VERSION "Version"

NS_ :

BS_:

BU_: ADC FLR FRR Tester

BO_ 541 FLR_Obj_28: 32 FLR
 SG_ SGU28_Msg_CheckSum : 7|8@0+ (1,0) [0|255] ""  ADC
 SG_ SGU28_Msg_AliveCounter : 11|4@0+ (1,0) [0|14] ""  ADC
 SG_ SGU28_BlockCounter : 15|4@0+ (1,0) [0|15] ""  ADC
 SG_ SGU28_Object_ID : 23|8@0+ (1,0) [0|255] ""  ADC
 SG_ SGU28_Object_wExist : 28|5@0+ (0.03125,0) [0|0.96875] ""  ADC
 SG_ SGU28_Object_Type : 31|3@0+ (1,0) [0|7] ""  ADC
 SG_ SGU28_Object_Motion_Pattern : 34|3@0+ (1,0) [0|7] ""  ADC
 SG_ SGU28_Object_wObstacle : 39|5@0+ (0.03125,0) [0|0.96875] ""  ADC
 SG_ SGU28_Object_dx : 43|12@0+ (0.0625,-128) [-128|127.9375] "m"  ADC
 SG_ SGU28_Object_dy : 59|12@0+ (0.125,-128) [-128|127.875] "m"  ADC
 SG_ SGU28_Object_DistLong_rms : 79|16@0+ (0.001953125,0) [0|127.998046875] "m"  ADC
 SG_ SGU28_Obj_DistLat_rms : 95|16@0+ (0.001953125,0) [0|127.998046875] "m"  ADC
 SG_ SGU28_Object_vx : 107|12@0+ (0.0625,-128) [-128|127.9375] "m/s"  ADC
 SG_ SGU28_Object_vy : 123|12@0+ (0.0625,-128) [-128|127.9375] "m/s"  ADC
 SG_ SGU28_Obj_VrelLong_rms : 143|16@0+ (0.001953125,0) [0|127.998046875] "m/s"  ADC
 SG_ SGU28_Obj_Vrelat_rms : 159|16@0+ (0.001953125,0) [0|127.998046875] "m/s"  ADC
 SG_ SGU28_Object_ax : 170|11@0+ (0.03125,-16) [-16|15.96875] "m/s^2"  ADC
 SG_ SGU28_Object_ay : 191|11@0+ (0.03125,-16) [-16|15.96875] "m/s^2"  ADC
 SG_ SGU28_Object_DetStatus : 173|3@0+ (1,0) [0|7] ""  ADC
 SG_ SGU28_LifeCycles_OBJ : 196|8@0+ (1,0) [0|255] ""  ADC
 SG_ SGU28_ObjRCS_28 : 204|10@0+ (0.125,-50) [-50|70] "dBm2"  ADC
 SG_ SGU28_Object_dx_Rear : 209|12@0+ (0.0625,-128) [-128|127.9375] "m"  ADC
 SG_ SGU28_Object_dy_Rear : 229|12@0+ (0.125,-128) [-128|127.875] "m"  ADC

BO_ 542 FLR_Obj_29: 32 FLR
 SG_ SGU29_Msg_CheckSum : 7|8@0+ (1,0) [0|255] ""  ADC
 SG_ SGU29_Msg_AliveCounter : 11|4@0+ (1,0) [0|14] ""  ADC
 SG_ SGU29_BlockCounter : 15|4@0+ (1,0) [0|15] ""  ADC
 SG_ SGU29_Object_ID : 23|8@0+ (1,0) [0|255] ""  ADC
 SG_ SGU29_Object_wExist : 28|5@0+ (0.03125,0) [0|0.96875] ""  ADC
 SG_ SGU29_Object_Type : 31|3@0+ (1,0) [0|7] ""  ADC
 SG_ SGU29_Object_Motion_Pattern : 34|3@0+ (1,0) [0|7] ""  ADC
 SG_ SGU29_Object_wObstacle : 39|5@0+ (0.03125,0) [0|0.96875] ""  ADC
 SG_ SGU29_Object_dx : 43|12@0+ (0.0625,-128) [-128|127.9375] "m"  ADC
 SG_ SGU29_Object_dy : 59|12@0+ (0.125,-128) [-128|127.875] "m"  ADC
 SG_ SGU29_Object_DistLong_rms : 79|16@0+ (0.001953125,0) [0|127.998046875] "m"  ADC
 SG_ SGU29_Obj_DistLat_rms : 95|16@0+ (0.001953125,0) [0|127.998046875] "m"  ADC
 SG_ SGU29_Object_vx : 107|12@0+ (0.0625,-128) [-128|127.9375] "m/s"  ADC
 SG_ SGU29_Object_vy : 123|12@0+ (0.0625,-128) [-128|127.9375] "m/s"  ADC
 SG_ SGU29_Obj_VrelLong_rms : 143|16@0+ (0.001953125,0) [0|127.998046875] "m/s"  ADC
 SG_ SGU29_Obj_Vrelat_rms : 159|16@0+ (0.001953125,0) [0|127.998046875] "m/s"  ADC
 SG_ SGU29_Object_ax : 170|11@0+ (0.03125,-16) [-16|15.96875] "m/s^2"  ADC
 SG_ SGU29_Object_ay : 191|11@0+ (0.03125,-16) [-16|15.96875] "m/s^2"  ADC
 SG_ SGU29_Object_DetStatus : 173|3@0+ (1,0) [0|7] ""  ADC
 SG_ SGU29_LifeCycles_OBJ : 196|8@0+ (1,0) [0|255] ""  ADC
 SG_ SGU29_ObjRCS_29 : 204|10@0+ (0.125,-50) [-50|70] "dBm2"  ADC
 SG_ SGU29_Object_dx_Rear : 209|12@0+ (0.0625,-128) [-128|127.9375] "m"  ADC
 SG_ SGU29_Object_dy_Rear : 229|12@0+ (0.125,-128) [-128|127.875] "m"  ADC

BO_ 543 FLR_Obj_30: 32 FLR
 SG_ SGU30_Msg_CheckSum : 7|8@0+ (1,0) [0|255] ""  ADC
 SG_ SGU30_Msg_AliveCounter : 11|4@0+ (1,0) [0|14] ""  ADC
 SG_ SGU30_BlockCounter : 15|4@0+ (1,0) [0|15] ""  ADC
 SG_ SGU30_Object_ID : 23|8@0+ (1,0) [0|255] ""  ADC
 SG_ SGU30_Object_wExist : 28|5@0+ (0.03125,0) [0|0.96875] ""  ADC
 SG_ SGU30_Object_Type : 31|3@0+ (1,0) [0|7] ""  ADC
 SG_ SGU30_Object_Motion_Pattern : 34|3@0+ (1,0) [0|7] ""  ADC
 SG_ SGU30_Object_wObstacle : 39|5@0+ (0.03125,0) [0|0.96875] ""  ADC
 SG_ SGU30_Object_dx : 43|12@0+ (0.0625,-128) [-128|127.9375] "m"  ADC
 SG_ SGU30_Object_dy : 59|12@0+ (0.125,-128) [-128|127.875] "m"  ADC
 SG_ SGU30_Object_DistLong_rms : 79|16@0+ (0.001953125,0) [0|127.998046875] "m"  ADC
 SG_ SGU30_Obj_DistLat_rms : 95|16@0+ (0.001953125,0) [0|127.998046875] "m"  ADC
 SG_ SGU30_Object_vx : 107|12@0+ (0.0625,-128) [-128|127.9375] "m/s"  ADC
 SG_ SGU30_Object_vy : 123|12@0+ (0.0625,-128) [-128|127.9375] "m/s"  ADC
 SG_ SGU30_Obj_VrelLong_rms : 143|16@0+ (0.001953125,0) [0|127.998046875] "m/s"  ADC
 SG_ SGU30_Obj_Vrelat_rms : 159|16@0+ (0.001953125,0) [0|127.998046875] "m/s"  ADC
 SG_ SGU30_Object_ax : 170|11@0+ (0.03125,-16) [-16|15.96875] "m/s^2"  ADC
 SG_ SGU30_Object_ay : 191|11@0+ (0.03125,-16) [-16|15.96875] "m/s^2"  ADC
 SG_ SGU30_Object_DetStatus : 173|3@0+ (1,0) [0|7] ""  ADC
 SG_ SGU30_LifeCycles_OBJ : 196|8@0+ (1,0) [0|255] ""  ADC
 SG_ SGU30_ObjRCS_30 : 204|10@0+ (0.125,-50) [-50|70] "dBm2"  ADC
 SG_ SGU30_Object_dx_Rear : 209|12@0+ (0.0625,-128) [-128|127.9375] "m"  ADC
 SG_ SGU30_Object_dy_Rear : 229|12@0+ (0.125,-128) [-128|127.875] "m"  ADC

BO_ 544 FLR_Obj_31: 32 FLR
 SG_ SGU31_Msg_CheckSum : 7|8@0+ (1,0) [0|255] ""  ADC
 SG_ SGU31_Msg_AliveCounter : 11|4@0+ (1,0) [0|14] ""  ADC
 SG_ SGU31_BlockCounter : 15|4@0+ (1,0) [0|15] ""  ADC
 SG_ SGU31_Object_ID : 23|8@0+ (1,0) [0|255] ""  ADC
 SG_ SGU31_Object_wExist : 28|5@0+ (0.03125,0) [0|0.96875] ""  ADC
 SG_ SGU31_Object_Type : 31|3@0+ (1,0) [0|7] ""  ADC
 SG_ SGU31_Object_Motion_Pattern : 34|3@0+ (1,0) [0|7] ""  ADC
 SG_ SGU31_Object_wObstacle : 39|5@0+ (0.03125,0) [0|0.96875] ""  ADC
 SG_ SGU31_Object_dx : 43|12@0+ (0.0625,-128) [-128|127.9375] "m"  ADC
 SG_ SGU31_Object_dy : 59|12@0+ (0.125,-128) [-128|127.875] "m"  ADC
 SG_ SGU31_Object_DistLong_rms : 79|16@0+ (0.001953125,0) [0|127.998046875] "m"  ADC
 SG_ SGU31_Obj_DistLat_rms : 95|16@0+ (0.001953125,0) [0|127.998046875] "m"  ADC
 SG_ SGU31_Object_vx : 107|12@0+ (0.0625,-128) [-128|127.9375] "m/s"  ADC
 SG_ SGU31_Object_vy : 123|12@0+ (0.0625,-128) [-128|127.9375] "m/s"  ADC
 SG_ SGU31_Obj_VrelLong_rms : 143|16@0+ (0.001953125,0) [0|127.998046875] "m/s"  ADC
 SG_ SGU31_Obj_Vrelat_rms : 159|16@0+ (0.001953125,0) [0|127.998046875] "m/s"  ADC
 SG_ SGU31_Object_ax : 170|11@0+ (0.03125,-16) [-16|15.96875] "m/s^2"  ADC
 SG_ SGU31_Object_ay : 191|11@0+ (0.03125,-16) [-16|15.96875] "m/s^2"  ADC
 SG_ SGU31_Object_DetStatus : 173|3@0+ (1,0) [0|7] ""  ADC
 SG_ SGU31_LifeCycles_OBJ : 196|8@0+ (1,0) [0|255] ""  ADC
 SG_ SGU31_ObjRCS_31 : 204|10@0+ (0.125,-50) [-50|70] "dBm2"  ADC
 SG_ SGU31_Object_dx_Rear : 209|12@0+ (0.0625,-128) [-128|127.9375] "m"  ADC
 SG_ SGU31_Object_dy_Rear : 229|12@0+ (0.125,-128) [-128|127.875] "m"  ADC

BO_ 545 FLR_Obj_32: 32 FLR
 SG_ SGU32_Msg_CheckSum : 7|8@0+ (1,0) [0|255] ""  ADC
 SG_ SGU32_Msg_AliveCounter : 11|4@0+ (1,0) [0|14] ""  ADC
 SG_ SGU32_BlockCounter : 15|4@0+ (1,0) [0|15] ""  ADC
 SG_ SGU32_Object_ID : 23|8@0+ (1,0) [0|255] ""  ADC
 SG_ SGU32_Object_wExist : 28|5@0+ (0.03125,0) [0|0.96875] ""  ADC
 SG_ SGU32_Object_Type : 31|3@0+ (1,0) [0|7] ""  ADC
 SG_ SGU32_Object_Motion_Pattern : 34|3@0+ (1,0) [0|7] ""  ADC
 SG_ SGU32_Object_wObstacle : 39|5@0+ (0.03125,0) [0|0.96875] ""  ADC
 SG_ SGU32_Object_dx : 43|12@0+ (0.0625,-128) [-128|127.9375] "m"  ADC
 SG_ SGU32_Object_dy : 59|12@0+ (0.125,-128) [-128|127.875] "m"  ADC
 SG_ SGU32_Object_DistLong_rms : 79|16@0+ (0.001953125,0) [0|127.998046875] "m"  ADC
 SG_ SGU32_Obj_DistLat_rms : 95|16@0+ (0.001953125,0) [0|127.998046875] "m"  ADC
 SG_ SGU32_Object_vx : 107|12@0+ (0.0625,-128) [-128|127.9375] "m/s"  ADC
 SG_ SGU32_Object_vy : 123|12@0+ (0.0625,-128) [-128|127.9375] "m/s"  ADC
 SG_ SGU32_Obj_VrelLong_rms : 143|16@0+ (0.001953125,0) [0|127.998046875] "m/s"  ADC
 SG_ SGU32_Obj_Vrelat_rms : 159|16@0+ (0.001953125,0) [0|127.998046875] "m/s"  ADC
 SG_ SGU32_Object_ax : 170|11@0+ (0.03125,-16) [-16|15.96875] "m/s^2"  ADC
 SG_ SGU32_Object_ay : 191|11@0+ (0.03125,-16) [-16|15.96875] "m/s^2"  ADC
 SG_ SGU32_Object_DetStatus : 173|3@0+ (1,0) [0|7] ""  ADC
 SG_ SGU32_LifeCycles_OBJ : 196|8@0+ (1,0) [0|255] ""  ADC
 SG_ SGU32_ObjRCS_32 : 204|10@0+ (0.125,-50) [-50|70] "dBm2"  ADC
 SG_ SGU32_Object_dx_Rear : 209|12@0+ (0.0625,-128) [-128|127.9375] "m"  ADC
 SG_ SGU32_Object_dy_Rear : 229|12@0+ (0.125,-128) [-128|127.875] "m"  ADC

BO_ 546 FLR_RadarInfo: 32 FLR
 SG_ FLR_RadarInfor_Checksum : 7|8@0+ (1,0) [0|255] ""  ADC
 SG_ FLR_RadarInfor_AliveCounter : 11|4@0+ (1,0) [0|14] ""  ADC
 SG_ mountAngleIndicator_az : 31|9@0+ (0.05,-12.8) [-12.8|12.75] "degree"  ADC
 SG_ mountAngleCurrent_az : 38|9@0+ (0.05,-12.8) [-12.8|12.75] "degree"  ADC
 SG_ mountAngleIndicator_el : 45|9@0+ (0.05,-12.8) [-12.8|12.75] "degree"  ADC
 SG_ mountAngleCurrent_el : 52|9@0+ (0.05,-12.8) [-12.8|12.75] "degree"  ADC
 SG_ malStablePosAz : 59|9@0+ (0.05,-12.8) [-12.8|12.75] "degree"  ADC
 SG_ malStablePosEl : 66|9@0+ (0.05,-12.8) [-12.8|12.75] "degree"  ADC
 SG_ AngleEMEIndicatorAz : 73|9@0+ (0.05,-12.8) [-12.8|12.75] "degree"  ADC
 SG_ AngleEMEIndicatorEl : 95|9@0+ (0.05,-12.8) [-12.8|12.75] "degree"  ADC
 SG_ FilteredPhiSpread : 102|11@0+ (0.1,-102.4) [-102.4|102.3] "m"  ADC
 SG_ highSpreadIndicator_el : 107|9@0+ (0.05,-12.8) [-12.8|12.75] "degree"  ADC
 SG_ highSpreadIndicator_az : 114|9@0+ (0.05,-12.8) [-12.8|12.75] "degree"  ADC
 SG_ elOutOfSpecCause : 129|2@0+ (1,0) [0|3] ""  ADC
 SG_ azOutOfSpecCause : 131|2@0+ (1,0) [0|3] ""  ADC
 SG_ Fault_MAL_HOR_ABS_EVENT : 132|1@0+ (1,0) [0|1] ""  ADC
 SG_ Fault_MAL_HOR_REL_EVENT : 133|1@0+ (1,0) [0|1] ""  ADC
 SG_ Fault_MAL_VER_ABS_EVENT : 134|1@0+ (1,0) [0|1] ""  ADC
 SG_ Fault_MAL_VER_REL_EVENT : 135|1@0+ (1,0) [0|1] ""  ADC
 SG_ azOutOfProfileCause : 143|8@0+ (1,0) [0|255] ""  ADC
 SG_ elOutOfProfileCause : 151|8@0+ (1,0) [0|255] ""  ADC
 SG_ FLR_SW_Baseline : 155|4@0+ (1,0) [0|15] ""  ADC
 SG_ FLR_SW_ReleaseType : 159|4@0+ (1,0) [0|15] ""  ADC
 SG_ FLR_SW_MajorVersion : 163|4@0+ (1,0) [0|15] ""  ADC
 SG_ FLR_SW_MinorVersion : 167|4@0+ (1,0) [0|15] ""  ADC
 SG_ FLR_SDA_CalibrationSts : 175|8@0+ (1,0) [0|255] ""  ADC
 SG_ FLR_EOL_CalibrationSts : 183|8@0+ (1,0) [0|255] ""  ADC
 SG_ FLR_Blindness_FaultSts : 192|1@0+ (1,0) [0|1] ""  ADC
 SG_ FLR_ModulationSts : 193|1@0+ (1,0) [0|1] ""  ADC
 SG_ FLR_Misalignment_FaultSts : 194|1@0+ (1,0) [0|1] ""  ADC
 SG_ FLR_Radar_FaultSts : 207|8@0+ (1,0) [0|31] ""  ADC
 SG_ FLR_DTC_VBAT_HIGH : 208|1@0+ (1,0) [0|1] ""  ADC
 SG_ FLR_DTC_VBAT_LOW : 209|1@0+ (1,0) [0|1] ""  ADC
 SG_ FLR_DTC_HARDWARE_FAILURE : 210|1@0+ (1,0) [0|1] ""  ADC
 SG_ FLR_DTC_RADAR_OVER_TEMPERATURE : 211|1@0+ (1,0) [0|1] ""  ADC
 SG_ FLR_DTC_CORNER_RADAR_BLIND : 212|1@0+ (1,0) [0|1] ""  ADC
 SG_ FLR_DTC_CORNER_RADAR_MISALIGNED : 213|1@0+ (1,0) [0|1] ""  ADC
 SG_ FLR_DTC_DACORE_OOS : 214|1@0+ (1,0) [0|1] ""  ADC
 SG_ FLR_DTC_DSP_FAILURE : 215|1@0+ (1,0) [0|1] ""  ADC
 SG_ FLR_DTC_VARIANT_SELECTION_NOT_DONE : 216|1@0+ (1,0) [0|1] ""  ADC
 SG_ FLR_DTC_RADAR_SIDE_MISMATCH : 217|1@0+ (1,0) [0|1] ""  ADC
 SG_ FLR_DTC_ALIGNMENT_NOT_DONE : 218|1@0+ (1,0) [0|1] ""  ADC
 SG_ FLR_DTC_PUBLIC_CAN_BUSOFF : 219|1@0+ (1,0) [0|1] ""  ADC
 SG_ FLR_DTC_LOST_COMM_EPS : 222|1@0+ (1,0) [0|1] ""  ADC
 SG_ FLR_DTC_INVALID_DATA_EPS : 223|1@0+ (1,0) [0|1] ""  ADC
 SG_ FLR_DTC_LOST_COMM_BCS : 224|1@0+ (1,0) [0|1] ""  ADC
 SG_ FLR_DTC_INVALID_DATA_BCS : 225|1@0+ (1,0) [0|1] ""  ADC
 SG_ FLR_DTC_LOST_COMM_SOC : 230|1@0+ (1,0) [0|1] ""  ADC
 SG_ FLR_DTC_INVALID_DATA_SOC : 231|1@0+ (1,0) [0|1] ""  ADC
 SG_ FLR_DTC_SOC_Time_SYNC_FAIL : 232|1@0+ (1,0) [0|1] ""  ADC

BO_ 616 ADC_SOC_Time: 64 ADC
 SG_ UMM_UsageModeSt : 26|3@0+ (1,0) [0|7] ""  FLR,FRR
 SG_ VMM_OTAModeSt : 167|2@0+ (1,0) [0|3] ""  FLR,FRR
 SG_ Time_Year : 343|8@0+ (1,2000) [2000|2255] "y"  FLR,FRR
 SG_ Time_Month : 351|4@0+ (1,0) [1|12] "m"  FLR,FRR
 SG_ Time_Day : 347|5@0+ (1,0) [1|31] "d"  FLR,FRR
 SG_ Time_Hour : 358|5@0+ (1,0) [0|23] "h"  FLR,FRR
 SG_ Time_Min : 353|6@0+ (1,0) [0|59] "min"  FLR,FRR
 SG_ Time_Sec : 363|6@0+ (1,0) [0|59] "s"  FLR,FRR

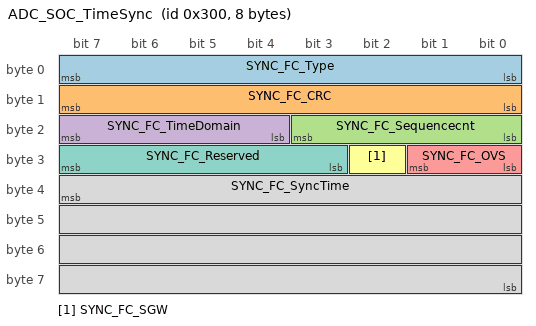
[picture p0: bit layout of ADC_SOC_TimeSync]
BO_ 768 ADC_SOC_TimeSync: 8 ADC
 SG_ SYNC_FC_Type : 7|8@0+ (1,0) [0|255] ""  FLR,FRR
 SG_ SYNC_FC_CRC : 15|8@0+ (1,0) [0|255] ""  FLR,FRR
 SG_ SYNC_FC_Sequencecnt : 19|4@0+ (1,0) [0|15] ""  FLR,FRR
 SG_ SYNC_FC_TimeDomain : 23|4@0+ (1,0) [0|15] ""  FLR,FRR
 SG_ SYNC_FC_OVS : 25|2@0+ (1,0) [0|3] ""  FLR,FRR
 SG_ SYNC_FC_SGW : 26|1@0+ (1,0) [0|1] ""  FLR,FRR
 SG_ SYNC_FC_Reserved : 31|5@0+ (1,0) [0|31] ""  FLR,FRR
 SG_ SYNC_FC_SyncTime : 39|32@0+ (1,0) [0|4294967295] ""  FLR,FRR

BO_ 769 FRR_SensorState: 32 FRR
 SG_ FRR_Msg_CheckSum : 7|8@0+ (1,0) [0|255] ""  ADC
 SG_ FRR_Msg_AliveCounter : 11|4@0+ (1,0) [0|14] ""  ADC
 SG_ FRR_BlockCounter : 15|4@0+ (1,0) [0|15] ""  ADC
 SG_ FRR_OperationMode : 20|3@0+ (1,0) [0|7] ""  ADC
 SG_ FRR_SensorType : 23|3@0+ (1,0) [0|7] ""  ADC
 SG_ FRR_Num_Of_Objects : 29|6@0+ (1,0) [0|32] ""  ADC
 SG_ FRR_SGUFail : 16|3@0+ (1,0) [0|7] ""  ADC
 SG_ FRR_TimerStampStatus : 39|8@0+ (1,0) [0|255] ""  ADC
 SG_ FRR_Object_Mea_timestamp_1 : 79|64@0+ (1,0) [0|18.4467440737096] "ns"  ADC
 SG_ FRR_Object_Mea_timestamp_2 : 143|32@0+ (1,0) [0|4294967295] "ns"  ADC
 SG_ FRR_SDA_HorzDeviationAngle_Can03 : 175|16@0+ (0.01,-180) [-180|180] "degree"  ADC
 SG_ FRR_SDA_VertDeviationAngle_Can03 : 191|16@0+ (0.01,-180) [-180|180] "degree"  ADC
 SG_ FRR_Signal_Operation_State : 210|3@0+ (1,0) [0|7] ""  ADC
 SG_ FRR_TimeSync_Operation_State : 213|3@0+ (1,0) [0|7] ""  ADC
 SG_ FRR_Signal_Operatation_Channel : 215|2@0+ (1,0) [0|4] ""  ADC
 SG_ FRR_TimeSync_Operatation_Channel : 217|2@0+ (1,0) [0|4] ""  ADC
 SG_ FRR_Moudulation_State : 220|3@0+ (1,0) [0|7] ""  ADC

BO_ 770 FRR_Obj_01: 32 FRR
 SG_ SGU1_Msg_CheckSum : 7|8@0+ (1,0) [0|255] ""  ADC
 SG_ SGU1_Msg_AliveCounter : 11|4@0+ (1,0) [0|14] ""  ADC
 SG_ SGU1_BlockCounter : 15|4@0+ (1,0) [0|15] ""  ADC
 SG_ SGU1_Object_ID : 23|8@0+ (1,0) [0|255] ""  ADC
 SG_ SGU1_Object_wExist : 28|5@0+ (0.03125,0) [0|0.96875] ""  ADC
 SG_ SGU1_Object_Type : 31|3@0+ (1,0) [0|7] ""  ADC
 SG_ SGU1_Object_Motion_Pattern : 34|3@0+ (1,0) [0|7] ""  ADC
 SG_ SGU1_Object_wObstacle : 39|5@0+ (0.03125,0) [0|0.96875] ""  ADC
 SG_ SGU1_Object_dx : 43|12@0+ (0.0625,-128) [-128|127.9375] "m"  ADC
 SG_ SGU1_Object_dy : 59|12@0+ (0.125,-128) [-128|127.875] "m"  ADC
 SG_ SGU1_Object_DistLong_rms : 79|16@0+ (0.001953125,0) [0|127.998046875] "m"  ADC
 SG_ SGU1_Obj_DistLat_rms : 95|16@0+ (0.001953125,0) [0|127.998046875] "m"  ADC
 SG_ SGU1_Object_vx : 107|12@0+ (0.0625,-128) [-128|127.9375] "m/s"  ADC
 SG_ SGU1_Object_vy : 123|12@0+ (0.0625,-128) [-128|127.9375] "m/s"  ADC
 SG_ SGU1_Obj_VrelLong_rms : 143|16@0+ (0.001953125,0) [0|127.998046875] "m/s"  ADC
 SG_ SGU1_Obj_Vrelat_rms : 159|16@0+ (0.001953125,0) [0|127.998046875] "m/s"  ADC
 SG_ SGU1_Object_ax : 170|11@0+ (0.03125,-16) [-16|15.96875] "m/s^2"  ADC
 SG_ SGU1_Object_ay : 191|11@0+ (0.03125,-16) [-16|15.96875] "m/s^2"  ADC
 SG_ SGU1_Object_DetStatus : 173|3@0+ (1,0) [0|7] ""  ADC
 SG_ SGU1_LifeCycles_OBJ : 196|8@0+ (1,0) [0|255] ""  ADC
 SG_ SGU1_ObjRCS_01 : 204|10@0+ (0.125,-50) [-50|70] "dBm2"  ADC
 SG_ SGU1_Object_dx_Rear : 209|12@0+ (0.0625,-128) [-128|127.9375] "m"  ADC
 SG_ SGU1_Object_dy_Rear : 229|12@0+ (0.125,-128) [-128|127.875] "m"  ADC

BO_ 771 FRR_Obj_02: 32 FRR
 SG_ SGU2_Msg_CheckSum : 7|8@0+ (1,0) [0|255] ""  ADC
 SG_ SGU2_Msg_AliveCounter : 11|4@0+ (1,0) [0|14] ""  ADC
 SG_ SGU2_BlockCounter : 15|4@0+ (1,0) [0|15] ""  ADC
 SG_ SGU2_Object_ID : 23|8@0+ (1,0) [0|255] ""  ADC
 SG_ SGU2_Object_wExist : 28|5@0+ (0.03125,0) [0|0.96875] ""  ADC
 SG_ SGU2_Object_Type : 31|3@0+ (1,0) [0|7] ""  ADC
 SG_ SGU2_Object_Motion_Pattern : 34|3@0+ (1,0) [0|7] ""  ADC
 SG_ SGU2_Object_wObstacle : 39|5@0+ (0.03125,0) [0|0.96875] ""  ADC
 SG_ SGU2_Object_dx : 43|12@0+ (0.0625,-128) [-128|127.9375] "m"  ADC
 SG_ SGU2_Object_dy : 59|12@0+ (0.125,-128) [-128|127.875] "m"  ADC
 SG_ SGU2_Object_DistLong_rms : 79|16@0+ (0.001953125,0) [0|127.998046875] "m"  ADC
 SG_ SGU2_Obj_DistLat_rms : 95|16@0+ (0.001953125,0) [0|127.998046875] "m"  ADC
 SG_ SGU2_Object_vx : 107|12@0+ (0.0625,-128) [-128|127.9375] "m/s"  ADC
 SG_ SGU2_Object_vy : 123|12@0+ (0.0625,-128) [-128|127.9375] "m/s"  ADC
 SG_ SGU2_Obj_VrelLong_rms : 143|16@0+ (0.001953125,0) [0|127.998046875] "m/s"  ADC
 SG_ SGU2_Obj_Vrelat_rms : 159|16@0+ (0.001953125,0) [0|127.998046875] "m/s"  ADC
 SG_ SGU2_Object_ax : 170|11@0+ (0.03125,-16) [-16|15.96875] "m/s^2"  ADC
 SG_ SGU2_Object_ay : 191|11@0+ (0.03125,-16) [-16|15.96875] "m/s^2"  ADC
 SG_ SGU2_Object_DetStatus : 173|3@0+ (1,0) [0|7] ""  ADC
 SG_ SGU2_LifeCycles_OBJ : 196|8@0+ (1,0) [0|255] ""  ADC
 SG_ SGU2_ObjRCS_02 : 204|10@0+ (0.125,-50) [-50|70] "dBm2"  ADC
 SG_ SGU2_Object_dx_Rear : 209|12@0+ (0.0625,-128) [-128|127.9375] "m"  ADC
 SG_ SGU2_Object_dy_Rear : 229|12@0+ (0.125,-128) [-128|127.875] "m"  ADC

BO_ 772 FRR_Obj_03: 32 FRR
 SG_ SGU3_Msg_CheckSum : 7|8@0+ (1,0) [0|255] ""  ADC
 SG_ SGU3_Msg_AliveCounter : 11|4@0+ (1,0) [0|14] ""  ADC
 SG_ SGU3_BlockCounter : 15|4@0+ (1,0) [0|15] ""  ADC
 SG_ SGU3_Object_ID : 23|8@0+ (1,0) [0|255] ""  ADC
 SG_ SGU3_Object_wExist : 28|5@0+ (0.03125,0) [0|0.96875] ""  ADC
 SG_ SGU3_Object_Type : 31|3@0+ (1,0) [0|7] ""  ADC
 SG_ SGU3_Object_Motion_Pattern : 34|3@0+ (1,0) [0|7] ""  ADC
 SG_ SGU3_Object_wObstacle : 39|5@0+ (0.03125,0) [0|0.96875] ""  ADC
 SG_ SGU3_Object_dx : 43|12@0+ (0.0625,-128) [-128|127.9375] "m"  ADC
 SG_ SGU3_Object_dy : 59|12@0+ (0.125,-128) [-128|127.875] "m"  ADC
 SG_ SGU3_Object_DistLong_rms : 79|16@0+ (0.001953125,0) [0|127.998046875] "m"  ADC
 SG_ SGU3_Obj_DistLat_rms : 95|16@0+ (0.001953125,0) [0|127.998046875] "m"  ADC
 SG_ SGU3_Object_vx : 107|12@0+ (0.0625,-128) [-128|127.9375] "m/s"  ADC
 SG_ SGU3_Object_vy : 123|12@0+ (0.0625,-128) [-128|127.9375] "m/s"  ADC
 SG_ SGU3_Obj_VrelLong_rms : 143|16@0+ (0.001953125,0) [0|127.998046875] "m/s"  ADC
 SG_ SGU3_Obj_Vrelat_rms : 159|16@0+ (0.001953125,0) [0|127.998046875] "m/s"  ADC
 SG_ SGU3_Object_ax : 170|11@0+ (0.03125,-16) [-16|15.96875] "m/s^2"  ADC
 SG_ SGU3_Object_ay : 191|11@0+ (0.03125,-16) [-16|15.96875] "m/s^2"  ADC
 SG_ SGU3_Object_DetStatus : 173|3@0+ (1,0) [0|7] ""  ADC
 SG_ SGU3_LifeCycles_OBJ : 196|8@0+ (1,0) [0|255] ""  ADC
 SG_ SGU3_ObjRCS_03 : 204|10@0+ (0.125,-50) [-50|70] "dBm2"  ADC
 SG_ SGU3_Object_dx_Rear : 209|12@0+ (0.0625,-128) [-128|127.9375] "m"  ADC
 SG_ SGU3_Object_dy_Rear : 229|12@0+ (0.125,-128) [-128|127.875] "m"  ADC

BO_ 773 FRR_Obj_04: 32 FRR
 SG_ SGU4_Msg_CheckSum : 7|8@0+ (1,0) [0|255] ""  ADC
 SG_ SGU4_Msg_AliveCounter : 11|4@0+ (1,0) [0|14] ""  ADC
 SG_ SGU4_BlockCounter : 15|4@0+ (1,0) [0|15] ""  ADC
 SG_ SGU4_Object_ID : 23|8@0+ (1,0) [0|255] ""  ADC
 SG_ SGU4_Object_wExist : 28|5@0+ (0.03125,0) [0|0.96875] ""  ADC
 SG_ SGU4_Object_Type : 31|3@0+ (1,0) [0|7] ""  ADC
 SG_ SGU4_Object_Motion_Pattern : 34|3@0+ (1,0) [0|7] ""  ADC
 SG_ SGU4_Object_wObstacle : 39|5@0+ (0.03125,0) [0|0.96875] ""  ADC
 SG_ SGU4_Object_dx : 43|12@0+ (0.0625,-128) [-128|127.9375] "m"  ADC
 SG_ SGU4_Object_dy : 59|12@0+ (0.125,-128) [-128|127.875] "m"  ADC
 SG_ SGU4_Object_DistLong_rms : 79|16@0+ (0.001953125,0) [0|127.998046875] "m"  ADC
 SG_ SGU4_Obj_DistLat_rms : 95|16@0+ (0.001953125,0) [0|127.998046875] "m"  ADC
 SG_ SGU4_Object_vx : 107|12@0+ (0.0625,-128) [-128|127.9375] "m/s"  ADC
 SG_ SGU4_Object_vy : 123|12@0+ (0.0625,-128) [-128|127.9375] "m/s"  ADC
 SG_ SGU4_Obj_VrelLong_rms : 143|16@0+ (0.001953125,0) [0|127.998046875] "m/s"  ADC
 SG_ SGU4_Obj_Vrelat_rms : 159|16@0+ (0.001953125,0) [0|127.998046875] "m/s"  ADC
 SG_ SGU4_Object_ax : 170|11@0+ (0.03125,-16) [-16|15.96875] "m/s^2"  ADC
 SG_ SGU4_Object_ay : 191|11@0+ (0.03125,-16) [-16|15.96875] "m/s^2"  ADC
 SG_ SGU4_Object_DetStatus : 173|3@0+ (1,0) [0|7] ""  ADC
 SG_ SGU4_LifeCycles_OBJ : 196|8@0+ (1,0) [0|255] ""  ADC
 SG_ SGU4_ObjRCS_04 : 204|10@0+ (0.125,-50) [-50|70] "dBm2"  ADC
 SG_ SGU4_Object_dx_Rear : 209|12@0+ (0.0625,-128) [-128|127.9375] "m"  ADC
 SG_ SGU4_Object_dy_Rear : 229|12@0+ (0.125,-128) [-128|127.875] "m"  ADC

BO_ 774 FRR_Obj_05: 32 FRR
 SG_ SGU5_Msg_CheckSum : 7|8@0+ (1,0) [0|255] ""  ADC
 SG_ SGU5_Msg_AliveCounter : 11|4@0+ (1,0) [0|14] ""  ADC
 SG_ SGU5_BlockCounter : 15|4@0+ (1,0) [0|15] ""  ADC
 SG_ SGU5_Object_ID : 23|8@0+ (1,0) [0|255] ""  ADC
 SG_ SGU5_Object_wExist : 28|5@0+ (0.03125,0) [0|0.96875] ""  ADC
 SG_ SGU5_Object_Type : 31|3@0+ (1,0) [0|7] ""  ADC
 SG_ SGU5_Object_Motion_Pattern : 34|3@0+ (1,0) [0|7] ""  ADC
 SG_ SGU5_Object_wObstacle : 39|5@0+ (0.03125,0) [0|0.96875] ""  ADC
 SG_ SGU5_Object_dx : 43|12@0+ (0.0625,-128) [-128|127.9375] "m"  ADC
 SG_ SGU5_Object_dy : 59|12@0+ (0.125,-128) [-128|127.875] "m"  ADC
 SG_ SGU5_Object_DistLong_rms : 79|16@0+ (0.001953125,0) [0|127.998046875] "m"  ADC
 SG_ SGU5_Obj_DistLat_rms : 95|16@0+ (0.001953125,0) [0|127.998046875] "m"  ADC
 SG_ SGU5_Object_vx : 107|12@0+ (0.0625,-128) [-128|127.9375] "m/s"  ADC
 SG_ SGU5_Object_vy : 123|12@0+ (0.0625,-128) [-128|127.9375] "m/s"  ADC
 SG_ SGU5_Obj_VrelLong_rms : 143|16@0+ (0.001953125,0) [0|127.998046875] "m/s"  ADC
 SG_ SGU5_Obj_Vrelat_rms : 159|16@0+ (0.001953125,0) [0|127.998046875] "m/s"  ADC
 SG_ SGU5_Object_ax : 170|11@0+ (0.03125,-16) [-16|15.96875] "m/s^2"  ADC
 SG_ SGU5_Object_ay : 191|11@0+ (0.03125,-16) [-16|15.96875] "m/s^2"  ADC
 SG_ SGU5_Object_DetStatus : 173|3@0+ (1,0) [0|7] ""  ADC
 SG_ SGU5_LifeCycles_OBJ : 196|8@0+ (1,0) [0|255] ""  ADC
 SG_ SGU5_ObjRCS_05 : 204|10@0+ (0.125,-50) [-50|70] "dBm2"  ADC
 SG_ SGU5_Object_dx_Rear : 209|12@0+ (0.0625,-128) [-128|127.9375] "m"  ADC
 SG_ SGU5_Object_dy_Rear : 229|12@0+ (0.125,-128) [-128|127.875] "m"  ADC

BO_ 775 FRR_Obj_06: 32 FRR
 SG_ SGU6_Msg_CheckSum : 7|8@0+ (1,0) [0|255] ""  ADC
 SG_ SGU6_Msg_AliveCounter : 11|4@0+ (1,0) [0|14] ""  ADC
 SG_ SGU6_BlockCounter : 15|4@0+ (1,0) [0|15] ""  ADC
 SG_ SGU6_Object_ID : 23|8@0+ (1,0) [0|255] ""  ADC
 SG_ SGU6_Object_wExist : 28|5@0+ (0.03125,0) [0|0.96875] ""  ADC
 SG_ SGU6_Object_Type : 31|3@0+ (1,0) [0|7] ""  ADC
 SG_ SGU6_Object_Motion_Pattern : 34|3@0+ (1,0) [0|7] ""  ADC
 SG_ SGU6_Object_wObstacle : 39|5@0+ (0.03125,0) [0|0.96875] ""  ADC
 SG_ SGU6_Object_dx : 43|12@0+ (0.0625,-128) [-128|127.9375] "m"  ADC
 SG_ SGU6_Object_dy : 59|12@0+ (0.125,-128) [-128|127.875] "m"  ADC
 SG_ SGU6_Object_DistLong_rms : 79|16@0+ (0.001953125,0) [0|127.998046875] "m"  ADC
 SG_ SGU6_Obj_DistLat_rms : 95|16@0+ (0.001953125,0) [0|127.998046875] "m"  ADC
 SG_ SGU6_Object_vx : 107|12@0+ (0.0625,-128) [-128|127.9375] "m/s"  ADC
 SG_ SGU6_Object_vy : 123|12@0+ (0.0625,-128) [-128|127.9375] "m/s"  ADC
 SG_ SGU6_Obj_VrelLong_rms : 143|16@0+ (0.001953125,0) [0|127.998046875] "m/s"  ADC
 SG_ SGU6_Obj_Vrelat_rms : 159|16@0+ (0.001953125,0) [0|127.998046875] "m/s"  ADC
 SG_ SGU6_Object_ax : 170|11@0+ (0.03125,-16) [-16|15.96875] "m/s^2"  ADC
 SG_ SGU6_Object_ay : 191|11@0+ (0.03125,-16) [-16|15.96875] "m/s^2"  ADC
 SG_ SGU6_Object_DetStatus : 173|3@0+ (1,0) [0|7] ""  ADC
 SG_ SGU6_LifeCycles_OBJ : 196|8@0+ (1,0) [0|255] ""  ADC
 SG_ SGU6_ObjRCS_06 : 204|10@0+ (0.125,-50) [-50|70] "dBm2"  ADC
 SG_ SGU6_Object_dx_Rear : 209|12@0+ (0.0625,-128) [-128|127.9375] "m"  ADC
 SG_ SGU6_Object_dy_Rear : 229|12@0+ (0.125,-128) [-128|127.875] "m"  ADC

BA_DEF_ BO_  "CANFD_BRS" ENUM  "0","1";
BA_DEF_ BO_  "GenMsgCycleTime" INT 0 0;
BA_DEF_ BO_  "GenMsgCycleTimeFast" INT 0 0;
BA_DEF_ BO_  "GenMsgSendType" ENUM  "Periodic","Event","IfActive","POE","PA","FixedPeriodic","Event","EnabledPeriodic","NotUsed","NotUsed","EventPeriodic","NotUsed","NotUsed","NoMsgSendType";
BA_DEF_ BO_  "VFrameFormat" ENUM  "StandardCAN","ExtendedCAN","reserved","reserved","reserved","reserved","reserved","reserved","reserved","reserved","reserved","reserved","reserved","reserved","StandardCAN_FD","ExtendedCAN_FD";
BA_DEF_ SG_  "EventCommandSignal" ENUM  "No","Yes";
BA_DEF_ SG_  "GatewayedSignals" ENUM  "No","Yes";
BA_DEF_ SG_  "GenSigInactiveValue" HEX 0 0;
BA_DEF_ SG_  "GenSigInvalidValue" HEX 0 0;
BA_DEF_ SG_  "GenSigSendType" ENUM  "Trigger","Passive","Cyclic","OnWrite","OnWriteWithRepetition","OnChange","OnChangeWithRepetition","IfActive","IfActiveWithRepetition","NoSigSendType";
BA_DEF_ SG_  "GenSigStartValue" HEX 0 0;
BA_DEF_ SG_  "GenSigTimeoutValue" HEX 0 0;
BA_DEF_ SG_  "Remark" STRING ;
BA_DEF_ BO_  "GenMsgILSupport" ENUM  "No","Yes";
BA_DEF_ BO_  "MsgType" ENUM  "Normal","NM","Diag","vector_leerstring";
BA_DEF_ BO_  "NmAsrMessage" ENUM  "No","Yes";
BA_DEF_ SG_  "IsCrcSignal" ENUM  "No","Yes";
BA_DEF_ SG_  "SystemSignalLongSymbol" STRING ;

BA_DEF_DEF_  "GenMsgILSupport" "Yes";
BA_DEF_DEF_  "IsCrcSignal" "No";
BA_DEF_DEF_  "MsgType" "";
BA_DEF_DEF_  "NmAsrMessage" "No";
BA_DEF_DEF_  "SystemSignalLongSymbol" "";
BA_ "CANFD_BRS" BO_ 541 1;
BA_ "CANFD_BRS" BO_ 542 1;
BA_ "CANFD_BRS" BO_ 543 1;
BA_ "CANFD_BRS" BO_ 544 1;
BA_ "CANFD_BRS" BO_ 545 1;
BA_ "CANFD_BRS" BO_ 546 1;
BA_ "CANFD_BRS" BO_ 616 1;
BA_ "CANFD_BRS" BO_ 768 1;
BA_ "CANFD_BRS" BO_ 769 1;
BA_ "CANFD_BRS" BO_ 770 1;
BA_ "CANFD_BRS" BO_ 771 1;
BA_ "CANFD_BRS" BO_ 772 1;
BA_ "CANFD_BRS" BO_ 773 1;
BA_ "CANFD_BRS" BO_ 774 1;
BA_ "CANFD_BRS" BO_ 775 1;
BA_ "GenMsgCycleTime" BO_ 541 0;
BA_ "GenMsgCycleTime" BO_ 542 0;
BA_ "GenMsgCycleTime" BO_ 543 0;
BA_ "GenMsgCycleTime" BO_ 544 0;
BA_ "GenMsgCycleTime" BO_ 545 0;
BA_ "GenMsgCycleTime" BO_ 546 50;
BA_ "GenMsgCycleTime" BO_ 616 20;
BA_ "GenMsgCycleTime" BO_ 768 500;
BA_ "GenMsgCycleTime" BO_ 769 0;
BA_ "GenMsgCycleTime" BO_ 770 0;
BA_ "GenMsgCycleTime" BO_ 771 0;
BA_ "GenMsgCycleTime" BO_ 772 0;
BA_ "GenMsgCycleTime" BO_ 773 0;
BA_ "GenMsgCycleTime" BO_ 774 0;
BA_ "GenMsgCycleTime" BO_ 775 0;
BA_ "GenMsgCycleTimeFast" BO_ 541 0;
BA_ "GenMsgCycleTimeFast" BO_ 542 0;
BA_ "GenMsgCycleTimeFast" BO_ 543 0;
BA_ "GenMsgCycleTimeFast" BO_ 544 0;
BA_ "GenMsgCycleTimeFast" BO_ 545 0;
BA_ "GenMsgCycleTimeFast" BO_ 546 0;
BA_ "GenMsgCycleTimeFast" BO_ 616 0;
BA_ "GenMsgCycleTimeFast" BO_ 768 0;
BA_ "GenMsgCycleTimeFast" BO_ 769 0;
BA_ "GenMsgCycleTimeFast" BO_ 770 0;
BA_ "GenMsgCycleTimeFast" BO_ 771 0;
BA_ "GenMsgCycleTimeFast" BO_ 772 0;
BA_ "GenMsgCycleTimeFast" BO_ 773 0;
BA_ "GenMsgCycleTimeFast" BO_ 774 0;
BA_ "GenMsgCycleTimeFast" BO_ 775 0;
BA_ "GenMsgSendType" BO_ 541 1;
BA_ "GenMsgSendType" BO_ 542 1;
BA_ "GenMsgSendType" BO_ 543 1;
BA_ "GenMsgSendType" BO_ 544 1;
BA_ "GenMsgSendType" BO_ 545 1;
BA_ "GenMsgSendType" BO_ 546 0;
BA_ "GenMsgSendType" BO_ 616 0;
BA_ "GenMsgSendType" BO_ 768 0;
BA_ "GenMsgSendType" BO_ 769 1;
BA_ "GenMsgSendType" BO_ 770 1;
BA_ "GenMsgSendType" BO_ 771 1;
BA_ "GenMsgSendType" BO_ 772 1;
BA_ "GenMsgSendType" BO_ 773 1;
BA_ "GenMsgSendType" BO_ 774 1;
BA_ "GenMsgSendType" BO_ 775 1;
BA_ "VFrameFormat" BO_ 541 14;
BA_ "VFrameFormat" BO_ 542 14;
BA_ "VFrameFormat" BO_ 543 14;
BA_ "VFrameFormat" BO_ 544 14;
BA_ "VFrameFormat" BO_ 545 14;
BA_ "VFrameFormat" BO_ 546 14;
BA_ "VFrameFormat" BO_ 616 14;
BA_ "VFrameFormat" BO_ 768 14;
BA_ "VFrameFormat" BO_ 769 14;
BA_ "VFrameFormat" BO_ 770 14;
BA_ "VFrameFormat" BO_ 771 14;
BA_ "VFrameFormat" BO_ 772 14;
BA_ "VFrameFormat" BO_ 773 14;
BA_ "VFrameFormat" BO_ 774 14;
BA_ "VFrameFormat" BO_ 775 14;
BA_ "EventCommandSignal" SG_ 541 SGU28_BlockCounter 0;
BA_ "GatewayedSignals" SG_ 541 SGU28_BlockCounter 0;
BA_ "GenSigInactiveValue" SG_ 541 SGU28_BlockCounter 0;
BA_ "GenSigInvalidValue" SG_ 541 SGU28_BlockCounter 0;
BA_ "GenSigSendType" SG_ 541 SGU28_BlockCounter 1;
BA_ "GenSigStartValue" SG_ 541 SGU28_BlockCounter 0;
BA_ "GenSigTimeoutValue" SG_ 541 SGU28_BlockCounter 0;
BA_ "Remark" SG_ 541 SGU28_BlockCounter "";
BA_ "EventCommandSignal" SG_ 541 SGU28_LifeCycles_OBJ 0;
BA_ "GatewayedSignals" SG_ 541 SGU28_LifeCycles_OBJ 0;
BA_ "GenSigInactiveValue" SG_ 541 SGU28_LifeCycles_OBJ 0;
BA_ "GenSigInvalidValue" SG_ 541 SGU28_LifeCycles_OBJ 0;
BA_ "GenSigSendType" SG_ 541 SGU28_LifeCycles_OBJ 1;
BA_ "GenSigStartValue" SG_ 541 SGU28_LifeCycles_OBJ 0;
BA_ "GenSigTimeoutValue" SG_ 541 SGU28_LifeCycles_OBJ 0;
BA_ "Remark" SG_ 541 SGU28_LifeCycles_OBJ "";
BA_ "EventCommandSignal" SG_ 541 SGU28_Msg_AliveCounter 0;
BA_ "GatewayedSignals" SG_ 541 SGU28_Msg_AliveCounter 0;
BA_ "GenSigInactiveValue" SG_ 541 SGU28_Msg_AliveCounter 0;
BA_ "GenSigInvalidValue" SG_ 541 SGU28_Msg_AliveCounter 0;
BA_ "GenSigSendType" SG_ 541 SGU28_Msg_AliveCounter 1;
BA_ "GenSigStartValue" SG_ 541 SGU28_Msg_AliveCounter 0;
BA_ "GenSigTimeoutValue" SG_ 541 SGU28_Msg_AliveCounter 0;
BA_ "Remark" SG_ 541 SGU28_Msg_AliveCounter "";
BA_ "EventCommandSignal" SG_ 541 SGU28_Msg_CheckSum 0;
BA_ "GatewayedSignals" SG_ 541 SGU28_Msg_CheckSum 0;
BA_ "GenSigInactiveValue" SG_ 541 SGU28_Msg_CheckSum 0;
BA_ "GenSigInvalidValue" SG_ 541 SGU28_Msg_CheckSum 0;
BA_ "GenSigSendType" SG_ 541 SGU28_Msg_CheckSum 1;
BA_ "GenSigStartValue" SG_ 541 SGU28_Msg_CheckSum 0;
BA_ "GenSigTimeoutValue" SG_ 541 SGU28_Msg_CheckSum 0;
BA_ "Remark" SG_ 541 SGU28_Msg_CheckSum "";
BA_ "EventCommandSignal" SG_ 541 SGU28_ObjRCS_28 0;
BA_ "GatewayedSignals" SG_ 541 SGU28_ObjRCS_28 0;
BA_ "GenSigInactiveValue" SG_ 541 SGU28_ObjRCS_28 0;
BA_ "GenSigInvalidValue" SG_ 541 SGU28_ObjRCS_28 0;
BA_ "GenSigSendType" SG_ 541 SGU28_ObjRCS_28 1;
BA_ "GenSigStartValue" SG_ 541 SGU28_ObjRCS_28 0;
BA_ "GenSigTimeoutValue" SG_ 541 SGU28_ObjRCS_28 0;
BA_ "Remark" SG_ 541 SGU28_ObjRCS_28 "";
BA_ "EventCommandSignal" SG_ 541 SGU28_Obj_DistLat_rms 0;
BA_ "GatewayedSignals" SG_ 541 SGU28_Obj_DistLat_rms 0;
BA_ "GenSigInactiveValue" SG_ 541 SGU28_Obj_DistLat_rms 0;
BA_ "GenSigInvalidValue" SG_ 541 SGU28_Obj_DistLat_rms 0;
BA_ "GenSigSendType" SG_ 541 SGU28_Obj_DistLat_rms 1;
BA_ "GenSigStartValue" SG_ 541 SGU28_Obj_DistLat_rms 0;
BA_ "GenSigTimeoutValue" SG_ 541 SGU28_Obj_DistLat_rms 0;
BA_ "Remark" SG_ 541 SGU28_Obj_DistLat_rms "";
BA_ "EventCommandSignal" SG_ 541 SGU28_Obj_VrelLong_rms 0;
BA_ "GatewayedSignals" SG_ 541 SGU28_Obj_VrelLong_rms 0;
BA_ "GenSigInactiveValue" SG_ 541 SGU28_Obj_VrelLong_rms 0;
BA_ "GenSigInvalidValue" SG_ 541 SGU28_Obj_VrelLong_rms 0;
BA_ "GenSigSendType" SG_ 541 SGU28_Obj_VrelLong_rms 1;
BA_ "GenSigStartValue" SG_ 541 SGU28_Obj_VrelLong_rms 0;
BA_ "GenSigTimeoutValue" SG_ 541 SGU28_Obj_VrelLong_rms 0;
BA_ "Remark" SG_ 541 SGU28_Obj_VrelLong_rms "";
BA_ "EventCommandSignal" SG_ 541 SGU28_Obj_Vrelat_rms 0;
BA_ "GatewayedSignals" SG_ 541 SGU28_Obj_Vrelat_rms 0;
BA_ "GenSigInactiveValue" SG_ 541 SGU28_Obj_Vrelat_rms 0;
BA_ "GenSigInvalidValue" SG_ 541 SGU28_Obj_Vrelat_rms 0;
BA_ "GenSigSendType" SG_ 541 SGU28_Obj_Vrelat_rms 1;
BA_ "GenSigStartValue" SG_ 541 SGU28_Obj_Vrelat_rms 0;
BA_ "GenSigTimeoutValue" SG_ 541 SGU28_Obj_Vrelat_rms 0;
BA_ "Remark" SG_ 541 SGU28_Obj_Vrelat_rms "";
BA_ "EventCommandSignal" SG_ 541 SGU28_Object_DetStatus 0;
BA_ "GatewayedSignals" SG_ 541 SGU28_Object_DetStatus 0;
BA_ "GenSigInactiveValue" SG_ 541 SGU28_Object_DetStatus 0;
BA_ "GenSigInvalidValue" SG_ 541 SGU28_Object_DetStatus 0;
BA_ "GenSigSendType" SG_ 541 SGU28_Object_DetStatus 1;
BA_ "GenSigStartValue" SG_ 541 SGU28_Object_DetStatus 0;
BA_ "GenSigTimeoutValue" SG_ 541 SGU28_Object_DetStatus 0;
BA_ "Remark" SG_ 541 SGU28_Object_DetStatus "";
BA_ "EventCommandSignal" SG_ 541 SGU28_Object_DistLong_rms 0;
BA_ "GatewayedSignals" SG_ 541 SGU28_Object_DistLong_rms 0;
BA_ "GenSigInactiveValue" SG_ 541 SGU28_Object_DistLong_rms 0;
BA_ "GenSigInvalidValue" SG_ 541 SGU28_Object_DistLong_rms 0;
BA_ "GenSigSendType" SG_ 541 SGU28_Object_DistLong_rms 1;
BA_ "GenSigStartValue" SG_ 541 SGU28_Object_DistLong_rms 0;
BA_ "GenSigTimeoutValue" SG_ 541 SGU28_Object_DistLong_rms 0;
BA_ "Remark" SG_ 541 SGU28_Object_DistLong_rms "";
BA_ "EventCommandSignal" SG_ 541 SGU28_Object_ID 0;
BA_ "GatewayedSignals" SG_ 541 SGU28_Object_ID 0;
BA_ "GenSigInactiveValue" SG_ 541 SGU28_Object_ID 0;
BA_ "GenSigInvalidValue" SG_ 541 SGU28_Object_ID 0;
BA_ "GenSigSendType" SG_ 541 SGU28_Object_ID 1;
BA_ "GenSigStartValue" SG_ 541 SGU28_Object_ID 0;
BA_ "GenSigTimeoutValue" SG_ 541 SGU28_Object_ID 0;
BA_ "Remark" SG_ 541 SGU28_Object_ID "";
BA_ "EventCommandSignal" SG_ 541 SGU28_Object_Motion_Pattern 0;
BA_ "GatewayedSignals" SG_ 541 SGU28_Object_Motion_Pattern 0;
BA_ "GenSigInactiveValue" SG_ 541 SGU28_Object_Motion_Pattern 0;
BA_ "GenSigInvalidValue" SG_ 541 SGU28_Object_Motion_Pattern 0;
BA_ "GenSigSendType" SG_ 541 SGU28_Object_Motion_Pattern 1;
BA_ "GenSigStartValue" SG_ 541 SGU28_Object_Motion_Pattern 0;
BA_ "GenSigTimeoutValue" SG_ 541 SGU28_Object_Motion_Pattern 0;
BA_ "Remark" SG_ 541 SGU28_Object_Motion_Pattern "";
BA_ "EventCommandSignal" SG_ 541 SGU28_Object_Type 0;
BA_ "GatewayedSignals" SG_ 541 SGU28_Object_Type 0;
BA_ "GenSigInactiveValue" SG_ 541 SGU28_Object_Type 0;
BA_ "GenSigInvalidValue" SG_ 541 SGU28_Object_Type 0;
BA_ "GenSigSendType" SG_ 541 SGU28_Object_Type 1;
BA_ "GenSigStartValue" SG_ 541 SGU28_Object_Type 0;
BA_ "GenSigTimeoutValue" SG_ 541 SGU28_Object_Type 0;
BA_ "Remark" SG_ 541 SGU28_Object_Type "";
BA_ "EventCommandSignal" SG_ 541 SGU28_Object_ax 0;
BA_ "GatewayedSignals" SG_ 541 SGU28_Object_ax 0;
BA_ "GenSigInactiveValue" SG_ 541 SGU28_Object_ax 0;
BA_ "GenSigInvalidValue" SG_ 541 SGU28_Object_ax 0;
BA_ "GenSigSendType" SG_ 541 SGU28_Object_ax 1;
BA_ "GenSigStartValue" SG_ 541 SGU28_Object_ax 0;
BA_ "GenSigTimeoutValue" SG_ 541 SGU28_Object_ax 0;
BA_ "Remark" SG_ 541 SGU28_Object_ax "";
BA_ "EventCommandSignal" SG_ 541 SGU28_Object_ay 0;
BA_ "GatewayedSignals" SG_ 541 SGU28_Object_ay 0;
BA_ "GenSigInactiveValue" SG_ 541 SGU28_Object_ay 0;
BA_ "GenSigInvalidValue" SG_ 541 SGU28_Object_ay 0;
BA_ "GenSigSendType" SG_ 541 SGU28_Object_ay 1;
BA_ "GenSigStartValue" SG_ 541 SGU28_Object_ay 0;
BA_ "GenSigTimeoutValue" SG_ 541 SGU28_Object_ay 0;
BA_ "Remark" SG_ 541 SGU28_Object_ay "";
BA_ "EventCommandSignal" SG_ 541 SGU28_Object_dx 0;
BA_ "GatewayedSignals" SG_ 541 SGU28_Object_dx 0;
BA_ "GenSigInactiveValue" SG_ 541 SGU28_Object_dx 0;
BA_ "GenSigInvalidValue" SG_ 541 SGU28_Object_dx 0;
BA_ "GenSigSendType" SG_ 541 SGU28_Object_dx 1;
BA_ "GenSigStartValue" SG_ 541 SGU28_Object_dx 0;
BA_ "GenSigTimeoutValue" SG_ 541 SGU28_Object_dx 0;
BA_ "Remark" SG_ 541 SGU28_Object_dx "";
BA_ "EventCommandSignal" SG_ 541 SGU28_Object_dx_Rear 0;
BA_ "GatewayedSignals" SG_ 541 SGU28_Object_dx_Rear 0;
BA_ "GenSigInactiveValue" SG_ 541 SGU28_Object_dx_Rear 0;
BA_ "GenSigInvalidValue" SG_ 541 SGU28_Object_dx_Rear 0;
BA_ "GenSigSendType" SG_ 541 SGU28_Object_dx_Rear 1;
BA_ "GenSigStartValue" SG_ 541 SGU28_Object_dx_Rear 0;
BA_ "GenSigTimeoutValue" SG_ 541 SGU28_Object_dx_Rear 0;
BA_ "Remark" SG_ 541 SGU28_Object_dx_Rear "";
BA_ "EventCommandSignal" SG_ 541 SGU28_Object_dy 0;
BA_ "GatewayedSignals" SG_ 541 SGU28_Object_dy 0;
BA_ "GenSigInactiveValue" SG_ 541 SGU28_Object_dy 0;
BA_ "GenSigInvalidValue" SG_ 541 SGU28_Object_dy 0;
BA_ "GenSigSendType" SG_ 541 SGU28_Object_dy 1;
BA_ "GenSigStartValue" SG_ 541 SGU28_Object_dy 0;
BA_ "GenSigTimeoutValue" SG_ 541 SGU28_Object_dy 0;
BA_ "Remark" SG_ 541 SGU28_Object_dy "";
BA_ "EventCommandSignal" SG_ 541 SGU28_Object_dy_Rear 0;
BA_ "GatewayedSignals" SG_ 541 SGU28_Object_dy_Rear 0;
BA_ "GenSigInactiveValue" SG_ 541 SGU28_Object_dy_Rear 0;
BA_ "GenSigInvalidValue" SG_ 541 SGU28_Object_dy_Rear 0;
BA_ "GenSigSendType" SG_ 541 SGU28_Object_dy_Rear 1;
BA_ "GenSigStartValue" SG_ 541 SGU28_Object_dy_Rear 0;
BA_ "GenSigTimeoutValue" SG_ 541 SGU28_Object_dy_Rear 0;
BA_ "Remark" SG_ 541 SGU28_Object_dy_Rear "";
BA_ "EventCommandSignal" SG_ 541 SGU28_Object_vx 0;
BA_ "GatewayedSignals" SG_ 541 SGU28_Object_vx 0;
BA_ "GenSigInactiveValue" SG_ 541 SGU28_Object_vx 0;
BA_ "GenSigInvalidValue" SG_ 541 SGU28_Object_vx 0;
BA_ "GenSigSendType" SG_ 541 SGU28_Object_vx 1;
BA_ "GenSigStartValue" SG_ 541 SGU28_Object_vx 0;
BA_ "GenSigTimeoutValue" SG_ 541 SGU28_Object_vx 0;
BA_ "Remark" SG_ 541 SGU28_Object_vx "";
BA_ "EventCommandSignal" SG_ 541 SGU28_Object_vy 0;
BA_ "GatewayedSignals" SG_ 541 SGU28_Object_vy 0;
BA_ "GenSigInactiveValue" SG_ 541 SGU28_Object_vy 0;
BA_ "GenSigInvalidValue" SG_ 541 SGU28_Object_vy 0;
BA_ "GenSigSendType" SG_ 541 SGU28_Object_vy 1;
BA_ "GenSigStartValue" SG_ 541 SGU28_Object_vy 0;
BA_ "GenSigTimeoutValue" SG_ 541 SGU28_Object_vy 0;
BA_ "Remark" SG_ 541 SGU28_Object_vy "";
BA_ "EventCommandSignal" SG_ 541 SGU28_Object_wExist 0;
BA_ "GatewayedSignals" SG_ 541 SGU28_Object_wExist 0;
BA_ "GenSigInactiveValue" SG_ 541 SGU28_Object_wExist 0;
BA_ "GenSigInvalidValue" SG_ 541 SGU28_Object_wExist 0;
BA_ "GenSigSendType" SG_ 541 SGU28_Object_wExist 1;
BA_ "GenSigStartValue" SG_ 541 SGU28_Object_wExist 0;
BA_ "GenSigTimeoutValue" SG_ 541 SGU28_Object_wExist 0;
BA_ "Remark" SG_ 541 SGU28_Object_wExist "";
BA_ "EventCommandSignal" SG_ 541 SGU28_Object_wObstacle 0;
BA_ "GatewayedSignals" SG_ 541 SGU28_Object_wObstacle 0;
BA_ "GenSigInactiveValue" SG_ 541 SGU28_Object_wObstacle 0;
BA_ "GenSigInvalidValue" SG_ 541 SGU28_Object_wObstacle 0;
BA_ "GenSigSendType" SG_ 541 SGU28_Object_wObstacle 1;
BA_ "GenSigStartValue" SG_ 541 SGU28_Object_wObstacle 0;
BA_ "GenSigTimeoutValue" SG_ 541 SGU28_Object_wObstacle 0;
BA_ "Remark" SG_ 541 SGU28_Object_wObstacle "";
BA_ "EventCommandSignal" SG_ 542 SGU29_BlockCounter 0;
BA_ "GatewayedSignals" SG_ 542 SGU29_BlockCounter 0;
BA_ "GenSigInactiveValue" SG_ 542 SGU29_BlockCounter 0;
BA_ "GenSigInvalidValue" SG_ 542 SGU29_BlockCounter 0;
BA_ "GenSigSendType" SG_ 542 SGU29_BlockCounter 1;
BA_ "GenSigStartValue" SG_ 542 SGU29_BlockCounter 0;
BA_ "GenSigTimeoutValue" SG_ 542 SGU29_BlockCounter 0;
BA_ "Remark" SG_ 542 SGU29_BlockCounter "";
BA_ "EventCommandSignal" SG_ 542 SGU29_LifeCycles_OBJ 0;
BA_ "GatewayedSignals" SG_ 542 SGU29_LifeCycles_OBJ 0;
BA_ "GenSigInactiveValue" SG_ 542 SGU29_LifeCycles_OBJ 0;
BA_ "GenSigInvalidValue" SG_ 542 SGU29_LifeCycles_OBJ 0;
BA_ "GenSigSendType" SG_ 542 SGU29_LifeCycles_OBJ 1;
BA_ "GenSigStartValue" SG_ 542 SGU29_LifeCycles_OBJ 0;
BA_ "GenSigTimeoutValue" SG_ 542 SGU29_LifeCycles_OBJ 0;
BA_ "Remark" SG_ 542 SGU29_LifeCycles_OBJ "";
BA_ "EventCommandSignal" SG_ 542 SGU29_Msg_AliveCounter 0;
BA_ "GatewayedSignals" SG_ 542 SGU29_Msg_AliveCounter 0;
BA_ "GenSigInactiveValue" SG_ 542 SGU29_Msg_AliveCounter 0;
BA_ "GenSigInvalidValue" SG_ 542 SGU29_Msg_AliveCounter 0;
BA_ "GenSigSendType" SG_ 542 SGU29_Msg_AliveCounter 1;
BA_ "GenSigStartValue" SG_ 542 SGU29_Msg_AliveCounter 0;
BA_ "GenSigTimeoutValue" SG_ 542 SGU29_Msg_AliveCounter 0;
BA_ "Remark" SG_ 542 SGU29_Msg_AliveCounter "";
BA_ "EventCommandSignal" SG_ 542 SGU29_Msg_CheckSum 0;
BA_ "GatewayedSignals" SG_ 542 SGU29_Msg_CheckSum 0;
BA_ "GenSigInactiveValue" SG_ 542 SGU29_Msg_CheckSum 0;
BA_ "GenSigInvalidValue" SG_ 542 SGU29_Msg_CheckSum 0;
BA_ "GenSigSendType" SG_ 542 SGU29_Msg_CheckSum 1;
BA_ "GenSigStartValue" SG_ 542 SGU29_Msg_CheckSum 0;
BA_ "GenSigTimeoutValue" SG_ 542 SGU29_Msg_CheckSum 0;
BA_ "Remark" SG_ 542 SGU29_Msg_CheckSum "";
BA_ "EventCommandSignal" SG_ 542 SGU29_ObjRCS_29 0;
BA_ "GatewayedSignals" SG_ 542 SGU29_ObjRCS_29 0;
BA_ "GenSigInactiveValue" SG_ 542 SGU29_ObjRCS_29 0;
BA_ "GenSigInvalidValue" SG_ 542 SGU29_ObjRCS_29 0;
BA_ "GenSigSendType" SG_ 542 SGU29_ObjRCS_29 1;
BA_ "GenSigStartValue" SG_ 542 SGU29_ObjRCS_29 0;
BA_ "GenSigTimeoutValue" SG_ 542 SGU29_ObjRCS_29 0;
BA_ "Remark" SG_ 542 SGU29_ObjRCS_29 "";
BA_ "EventCommandSignal" SG_ 542 SGU29_Obj_DistLat_rms 0;
BA_ "GatewayedSignals" SG_ 542 SGU29_Obj_DistLat_rms 0;
BA_ "GenSigInactiveValue" SG_ 542 SGU29_Obj_DistLat_rms 0;
BA_ "GenSigInvalidValue" SG_ 542 SGU29_Obj_DistLat_rms 0;
BA_ "GenSigSendType" SG_ 542 SGU29_Obj_DistLat_rms 1;
BA_ "GenSigStartValue" SG_ 542 SGU29_Obj_DistLat_rms 0;
BA_ "GenSigTimeoutValue" SG_ 542 SGU29_Obj_DistLat_rms 0;
BA_ "Remark" SG_ 542 SGU29_Obj_DistLat_rms "";
BA_ "EventCommandSignal" SG_ 542 SGU29_Obj_VrelLong_rms 0;
BA_ "GatewayedSignals" SG_ 542 SGU29_Obj_VrelLong_rms 0;
BA_ "GenSigInactiveValue" SG_ 542 SGU29_Obj_VrelLong_rms 0;
BA_ "GenSigInvalidValue" SG_ 542 SGU29_Obj_VrelLong_rms 0;
BA_ "GenSigSendType" SG_ 542 SGU29_Obj_VrelLong_rms 1;
BA_ "GenSigStartValue" SG_ 542 SGU29_Obj_VrelLong_rms 0;
BA_ "GenSigTimeoutValue" SG_ 542 SGU29_Obj_VrelLong_rms 0;
BA_ "Remark" SG_ 542 SGU29_Obj_VrelLong_rms "";
BA_ "EventCommandSignal" SG_ 542 SGU29_Obj_Vrelat_rms 0;
BA_ "GatewayedSignals" SG_ 542 SGU29_Obj_Vrelat_rms 0;
BA_ "GenSigInactiveValue" SG_ 542 SGU29_Obj_Vrelat_rms 0;
BA_ "GenSigInvalidValue" SG_ 542 SGU29_Obj_Vrelat_rms 0;
BA_ "GenSigSendType" SG_ 542 SGU29_Obj_Vrelat_rms 1;
BA_ "GenSigStartValue" SG_ 542 SGU29_Obj_Vrelat_rms 0;
BA_ "GenSigTimeoutValue" SG_ 542 SGU29_Obj_Vrelat_rms 0;
BA_ "Remark" SG_ 542 SGU29_Obj_Vrelat_rms "";
BA_ "EventCommandSignal" SG_ 542 SGU29_Object_DetStatus 0;
BA_ "GatewayedSignals" SG_ 542 SGU29_Object_DetStatus 0;
BA_ "GenSigInactiveValue" SG_ 542 SGU29_Object_DetStatus 0;
BA_ "GenSigInvalidValue" SG_ 542 SGU29_Object_DetStatus 0;
BA_ "GenSigSendType" SG_ 542 SGU29_Object_DetStatus 1;
BA_ "GenSigStartValue" SG_ 542 SGU29_Object_DetStatus 0;
BA_ "GenSigTimeoutValue" SG_ 542 SGU29_Object_DetStatus 0;
BA_ "Remark" SG_ 542 SGU29_Object_DetStatus "";
BA_ "EventCommandSignal" SG_ 542 SGU29_Object_DistLong_rms 0;
BA_ "GatewayedSignals" SG_ 542 SGU29_Object_DistLong_rms 0;
BA_ "GenSigInactiveValue" SG_ 542 SGU29_Object_DistLong_rms 0;
BA_ "GenSigInvalidValue" SG_ 542 SGU29_Object_DistLong_rms 0;
BA_ "GenSigSendType" SG_ 542 SGU29_Object_DistLong_rms 1;
BA_ "GenSigStartValue" SG_ 542 SGU29_Object_DistLong_rms 0;
BA_ "GenSigTimeoutValue" SG_ 542 SGU29_Object_DistLong_rms 0;
BA_ "Remark" SG_ 542 SGU29_Object_DistLong_rms "";
BA_ "EventCommandSignal" SG_ 542 SGU29_Object_ID 0;
BA_ "GatewayedSignals" SG_ 542 SGU29_Object_ID 0;
BA_ "GenSigInactiveValue" SG_ 542 SGU29_Object_ID 0;
BA_ "GenSigInvalidValue" SG_ 542 SGU29_Object_ID 0;
BA_ "GenSigSendType" SG_ 542 SGU29_Object_ID 1;
BA_ "GenSigStartValue" SG_ 542 SGU29_Object_ID 0;
BA_ "GenSigTimeoutValue" SG_ 542 SGU29_Object_ID 0;
BA_ "Remark" SG_ 542 SGU29_Object_ID "";
BA_ "EventCommandSignal" SG_ 542 SGU29_Object_Motion_Pattern 0;
BA_ "GatewayedSignals" SG_ 542 SGU29_Object_Motion_Pattern 0;
BA_ "GenSigInactiveValue" SG_ 542 SGU29_Object_Motion_Pattern 0;
BA_ "GenSigInvalidValue" SG_ 542 SGU29_Object_Motion_Pattern 0;
BA_ "GenSigSendType" SG_ 542 SGU29_Object_Motion_Pattern 1;
BA_ "GenSigStartValue" SG_ 542 SGU29_Object_Motion_Pattern 0;
BA_ "GenSigTimeoutValue" SG_ 542 SGU29_Object_Motion_Pattern 0;
BA_ "Remark" SG_ 542 SGU29_Object_Motion_Pattern "";
BA_ "EventCommandSignal" SG_ 542 SGU29_Object_Type 0;
BA_ "GatewayedSignals" SG_ 542 SGU29_Object_Type 0;
BA_ "GenSigInactiveValue" SG_ 542 SGU29_Object_Type 0;
BA_ "GenSigInvalidValue" SG_ 542 SGU29_Object_Type 0;
BA_ "GenSigSendType" SG_ 542 SGU29_Object_Type 1;
BA_ "GenSigStartValue" SG_ 542 SGU29_Object_Type 0;
BA_ "GenSigTimeoutValue" SG_ 542 SGU29_Object_Type 0;
BA_ "Remark" SG_ 542 SGU29_Object_Type "";
BA_ "EventCommandSignal" SG_ 542 SGU29_Object_ax 0;
BA_ "GatewayedSignals" SG_ 542 SGU29_Object_ax 0;
BA_ "GenSigInactiveValue" SG_ 542 SGU29_Object_ax 0;
BA_ "GenSigInvalidValue" SG_ 542 SGU29_Object_ax 0;
BA_ "GenSigSendType" SG_ 542 SGU29_Object_ax 1;
BA_ "GenSigStartValue" SG_ 542 SGU29_Object_ax 0;
BA_ "GenSigTimeoutValue" SG_ 542 SGU29_Object_ax 0;
BA_ "Remark" SG_ 542 SGU29_Object_ax "";
BA_ "EventCommandSignal" SG_ 542 SGU29_Object_ay 0;
BA_ "GatewayedSignals" SG_ 542 SGU29_Object_ay 0;
BA_ "GenSigInactiveValue" SG_ 542 SGU29_Object_ay 0;
BA_ "GenSigInvalidValue" SG_ 542 SGU29_Object_ay 0;
BA_ "GenSigSendType" SG_ 542 SGU29_Object_ay 1;
BA_ "GenSigStartValue" SG_ 542 SGU29_Object_ay 0;
BA_ "GenSigTimeoutValue" SG_ 542 SGU29_Object_ay 0;
BA_ "Remark" SG_ 542 SGU29_Object_ay "";
BA_ "EventCommandSignal" SG_ 542 SGU29_Object_dx 0;
BA_ "GatewayedSignals" SG_ 542 SGU29_Object_dx 0;
BA_ "GenSigInactiveValue" SG_ 542 SGU29_Object_dx 0;
BA_ "GenSigInvalidValue" SG_ 542 SGU29_Object_dx 0;
BA_ "GenSigSendType" SG_ 542 SGU29_Object_dx 1;
BA_ "GenSigStartValue" SG_ 542 SGU29_Object_dx 0;
BA_ "GenSigTimeoutValue" SG_ 542 SGU29_Object_dx 0;
BA_ "Remark" SG_ 542 SGU29_Object_dx "";
BA_ "EventCommandSignal" SG_ 542 SGU29_Object_dx_Rear 0;
BA_ "GatewayedSignals" SG_ 542 SGU29_Object_dx_Rear 0;
BA_ "GenSigInactiveValue" SG_ 542 SGU29_Object_dx_Rear 0;
BA_ "GenSigInvalidValue" SG_ 542 SGU29_Object_dx_Rear 0;
BA_ "GenSigSendType" SG_ 542 SGU29_Object_dx_Rear 1;
BA_ "GenSigStartValue" SG_ 542 SGU29_Object_dx_Rear 0;
BA_ "GenSigTimeoutValue" SG_ 542 SGU29_Object_dx_Rear 0;
BA_ "Remark" SG_ 542 SGU29_Object_dx_Rear "";
BA_ "EventCommandSignal" SG_ 542 SGU29_Object_dy 0;
BA_ "GatewayedSignals" SG_ 542 SGU29_Object_dy 0;
BA_ "GenSigInactiveValue" SG_ 542 SGU29_Object_dy 0;
BA_ "GenSigInvalidValue" SG_ 542 SGU29_Object_dy 0;
BA_ "GenSigSendType" SG_ 542 SGU29_Object_dy 1;
BA_ "GenSigStartValue" SG_ 542 SGU29_Object_dy 0;
BA_ "GenSigTimeoutValue" SG_ 542 SGU29_Object_dy 0;
BA_ "Remark" SG_ 542 SGU29_Object_dy "";
BA_ "EventCommandSignal" SG_ 542 SGU29_Object_dy_Rear 0;
BA_ "GatewayedSignals" SG_ 542 SGU29_Object_dy_Rear 0;
BA_ "GenSigInactiveValue" SG_ 542 SGU29_Object_dy_Rear 0;
BA_ "GenSigInvalidValue" SG_ 542 SGU29_Object_dy_Rear 0;
BA_ "GenSigSendType" SG_ 542 SGU29_Object_dy_Rear 1;
BA_ "GenSigStartValue" SG_ 542 SGU29_Object_dy_Rear 0;
BA_ "GenSigTimeoutValue" SG_ 542 SGU29_Object_dy_Rear 0;
BA_ "Remark" SG_ 542 SGU29_Object_dy_Rear "";
BA_ "EventCommandSignal" SG_ 542 SGU29_Object_vx 0;
BA_ "GatewayedSignals" SG_ 542 SGU29_Object_vx 0;
BA_ "GenSigInactiveValue" SG_ 542 SGU29_Object_vx 0;
BA_ "GenSigInvalidValue" SG_ 542 SGU29_Object_vx 0;
BA_ "GenSigSendType" SG_ 542 SGU29_Object_vx 1;
BA_ "GenSigStartValue" SG_ 542 SGU29_Object_vx 0;
BA_ "GenSigTimeoutValue" SG_ 542 SGU29_Object_vx 0;
BA_ "Remark" SG_ 542 SGU29_Object_vx "";
BA_ "EventCommandSignal" SG_ 542 SGU29_Object_vy 0;
BA_ "GatewayedSignals" SG_ 542 SGU29_Object_vy 0;
BA_ "GenSigInactiveValue" SG_ 542 SGU29_Object_vy 0;
BA_ "GenSigInvalidValue" SG_ 542 SGU29_Object_vy 0;
BA_ "GenSigSendType" SG_ 542 SGU29_Object_vy 1;
BA_ "GenSigStartValue" SG_ 542 SGU29_Object_vy 0;
BA_ "GenSigTimeoutValue" SG_ 542 SGU29_Object_vy 0;
BA_ "Remark" SG_ 542 SGU29_Object_vy "";
BA_ "EventCommandSignal" SG_ 542 SGU29_Object_wExist 0;
BA_ "GatewayedSignals" SG_ 542 SGU29_Object_wExist 0;
BA_ "GenSigInactiveValue" SG_ 542 SGU29_Object_wExist 0;
BA_ "GenSigInvalidValue" SG_ 542 SGU29_Object_wExist 0;
BA_ "GenSigSendType" SG_ 542 SGU29_Object_wExist 1;
BA_ "GenSigStartValue" SG_ 542 SGU29_Object_wExist 0;
BA_ "GenSigTimeoutValue" SG_ 542 SGU29_Object_wExist 0;
BA_ "Remark" SG_ 542 SGU29_Object_wExist "";
BA_ "EventCommandSignal" SG_ 542 SGU29_Object_wObstacle 0;
BA_ "GatewayedSignals" SG_ 542 SGU29_Object_wObstacle 0;
BA_ "GenSigInactiveValue" SG_ 542 SGU29_Object_wObstacle 0;
BA_ "GenSigInvalidValue" SG_ 542 SGU29_Object_wObstacle 0;
BA_ "GenSigSendType" SG_ 542 SGU29_Object_wObstacle 1;
BA_ "GenSigStartValue" SG_ 542 SGU29_Object_wObstacle 0;
BA_ "GenSigTimeoutValue" SG_ 542 SGU29_Object_wObstacle 0;
BA_ "Remark" SG_ 542 SGU29_Object_wObstacle "";
BA_ "EventCommandSignal" SG_ 543 SGU30_BlockCounter 0;
BA_ "GatewayedSignals" SG_ 543 SGU30_BlockCounter 0;
BA_ "GenSigInactiveValue" SG_ 543 SGU30_BlockCounter 0;
BA_ "GenSigInvalidValue" SG_ 543 SGU30_BlockCounter 0;
BA_ "GenSigSendType" SG_ 543 SGU30_BlockCounter 1;
BA_ "GenSigStartValue" SG_ 543 SGU30_BlockCounter 0;
BA_ "GenSigTimeoutValue" SG_ 543 SGU30_BlockCounter 0;
BA_ "Remark" SG_ 543 SGU30_BlockCounter "";
BA_ "EventCommandSignal" SG_ 543 SGU30_LifeCycles_OBJ 0;
BA_ "GatewayedSignals" SG_ 543 SGU30_LifeCycles_OBJ 0;
BA_ "GenSigInactiveValue" SG_ 543 SGU30_LifeCycles_OBJ 0;
BA_ "GenSigInvalidValue" SG_ 543 SGU30_LifeCycles_OBJ 0;
BA_ "GenSigSendType" SG_ 543 SGU30_LifeCycles_OBJ 1;
BA_ "GenSigStartValue" SG_ 543 SGU30_LifeCycles_OBJ 0;
BA_ "GenSigTimeoutValue" SG_ 543 SGU30_LifeCycles_OBJ 0;
BA_ "Remark" SG_ 543 SGU30_LifeCycles_OBJ "";
BA_ "EventCommandSignal" SG_ 543 SGU30_Msg_AliveCounter 0;
BA_ "GatewayedSignals" SG_ 543 SGU30_Msg_AliveCounter 0;
BA_ "GenSigInactiveValue" SG_ 543 SGU30_Msg_AliveCounter 0;
BA_ "GenSigInvalidValue" SG_ 543 SGU30_Msg_AliveCounter 0;
BA_ "GenSigSendType" SG_ 543 SGU30_Msg_AliveCounter 1;
BA_ "GenSigStartValue" SG_ 543 SGU30_Msg_AliveCounter 0;
BA_ "GenSigTimeoutValue" SG_ 543 SGU30_Msg_AliveCounter 0;
BA_ "Remark" SG_ 543 SGU30_Msg_AliveCounter "";
BA_ "EventCommandSignal" SG_ 543 SGU30_Msg_CheckSum 0;
BA_ "GatewayedSignals" SG_ 543 SGU30_Msg_CheckSum 0;
BA_ "GenSigInactiveValue" SG_ 543 SGU30_Msg_CheckSum 0;
BA_ "GenSigInvalidValue" SG_ 543 SGU30_Msg_CheckSum 0;
BA_ "GenSigSendType" SG_ 543 SGU30_Msg_CheckSum 1;
BA_ "GenSigStartValue" SG_ 543 SGU30_Msg_CheckSum 0;
BA_ "GenSigTimeoutValue" SG_ 543 SGU30_Msg_CheckSum 0;
BA_ "Remark" SG_ 543 SGU30_Msg_CheckSum "";
BA_ "EventCommandSignal" SG_ 543 SGU30_ObjRCS_30 0;
BA_ "GatewayedSignals" SG_ 543 SGU30_ObjRCS_30 0;
BA_ "GenSigInactiveValue" SG_ 543 SGU30_ObjRCS_30 0;
BA_ "GenSigInvalidValue" SG_ 543 SGU30_ObjRCS_30 0;
BA_ "GenSigSendType" SG_ 543 SGU30_ObjRCS_30 1;
BA_ "GenSigStartValue" SG_ 543 SGU30_ObjRCS_30 0;
BA_ "GenSigTimeoutValue" SG_ 543 SGU30_ObjRCS_30 0;
BA_ "Remark" SG_ 543 SGU30_ObjRCS_30 "";
BA_ "EventCommandSignal" SG_ 543 SGU30_Obj_DistLat_rms 0;
BA_ "GatewayedSignals" SG_ 543 SGU30_Obj_DistLat_rms 0;
BA_ "GenSigInactiveValue" SG_ 543 SGU30_Obj_DistLat_rms 0;
BA_ "GenSigInvalidValue" SG_ 543 SGU30_Obj_DistLat_rms 0;
BA_ "GenSigSendType" SG_ 543 SGU30_Obj_DistLat_rms 1;
BA_ "GenSigStartValue" SG_ 543 SGU30_Obj_DistLat_rms 0;
BA_ "GenSigTimeoutValue" SG_ 543 SGU30_Obj_DistLat_rms 0;
BA_ "Remark" SG_ 543 SGU30_Obj_DistLat_rms "";
BA_ "EventCommandSignal" SG_ 543 SGU30_Obj_VrelLong_rms 0;
BA_ "GatewayedSignals" SG_ 543 SGU30_Obj_VrelLong_rms 0;
BA_ "GenSigInactiveValue" SG_ 543 SGU30_Obj_VrelLong_rms 0;
BA_ "GenSigInvalidValue" SG_ 543 SGU30_Obj_VrelLong_rms 0;
BA_ "GenSigSendType" SG_ 543 SGU30_Obj_VrelLong_rms 1;
BA_ "GenSigStartValue" SG_ 543 SGU30_Obj_VrelLong_rms 0;
BA_ "GenSigTimeoutValue" SG_ 543 SGU30_Obj_VrelLong_rms 0;
BA_ "Remark" SG_ 543 SGU30_Obj_VrelLong_rms "";
BA_ "EventCommandSignal" SG_ 543 SGU30_Obj_Vrelat_rms 0;
BA_ "GatewayedSignals" SG_ 543 SGU30_Obj_Vrelat_rms 0;
BA_ "GenSigInactiveValue" SG_ 543 SGU30_Obj_Vrelat_rms 0;
BA_ "GenSigInvalidValue" SG_ 543 SGU30_Obj_Vrelat_rms 0;
BA_ "GenSigSendType" SG_ 543 SGU30_Obj_Vrelat_rms 1;
BA_ "GenSigStartValue" SG_ 543 SGU30_Obj_Vrelat_rms 0;
BA_ "GenSigTimeoutValue" SG_ 543 SGU30_Obj_Vrelat_rms 0;
BA_ "Remark" SG_ 543 SGU30_Obj_Vrelat_rms "";
BA_ "EventCommandSignal" SG_ 543 SGU30_Object_DetStatus 0;
BA_ "GatewayedSignals" SG_ 543 SGU30_Object_DetStatus 0;
BA_ "GenSigInactiveValue" SG_ 543 SGU30_Object_DetStatus 0;
BA_ "GenSigInvalidValue" SG_ 543 SGU30_Object_DetStatus 0;
BA_ "GenSigSendType" SG_ 543 SGU30_Object_DetStatus 1;
BA_ "GenSigStartValue" SG_ 543 SGU30_Object_DetStatus 0;
BA_ "GenSigTimeoutValue" SG_ 543 SGU30_Object_DetStatus 0;
BA_ "Remark" SG_ 543 SGU30_Object_DetStatus "";
BA_ "EventCommandSignal" SG_ 543 SGU30_Object_DistLong_rms 0;
BA_ "GatewayedSignals" SG_ 543 SGU30_Object_DistLong_rms 0;
BA_ "GenSigInactiveValue" SG_ 543 SGU30_Object_DistLong_rms 0;
BA_ "GenSigInvalidValue" SG_ 543 SGU30_Object_DistLong_rms 0;
BA_ "GenSigSendType" SG_ 543 SGU30_Object_DistLong_rms 1;
BA_ "GenSigStartValue" SG_ 543 SGU30_Object_DistLong_rms 0;
BA_ "GenSigTimeoutValue" SG_ 543 SGU30_Object_DistLong_rms 0;
BA_ "Remark" SG_ 543 SGU30_Object_DistLong_rms "";
BA_ "EventCommandSignal" SG_ 543 SGU30_Object_ID 0;
BA_ "GatewayedSignals" SG_ 543 SGU30_Object_ID 0;
BA_ "GenSigInactiveValue" SG_ 543 SGU30_Object_ID 0;
BA_ "GenSigInvalidValue" SG_ 543 SGU30_Object_ID 0;
BA_ "GenSigSendType" SG_ 543 SGU30_Object_ID 1;
BA_ "GenSigStartValue" SG_ 543 SGU30_Object_ID 0;
BA_ "GenSigTimeoutValue" SG_ 543 SGU30_Object_ID 0;
BA_ "Remark" SG_ 543 SGU30_Object_ID "";
BA_ "EventCommandSignal" SG_ 543 SGU30_Object_Motion_Pattern 0;
BA_ "GatewayedSignals" SG_ 543 SGU30_Object_Motion_Pattern 0;
BA_ "GenSigInactiveValue" SG_ 543 SGU30_Object_Motion_Pattern 0;
BA_ "GenSigInvalidValue" SG_ 543 SGU30_Object_Motion_Pattern 0;
BA_ "GenSigSendType" SG_ 543 SGU30_Object_Motion_Pattern 1;
BA_ "GenSigStartValue" SG_ 543 SGU30_Object_Motion_Pattern 0;
BA_ "GenSigTimeoutValue" SG_ 543 SGU30_Object_Motion_Pattern 0;
BA_ "Remark" SG_ 543 SGU30_Object_Motion_Pattern "";
BA_ "EventCommandSignal" SG_ 543 SGU30_Object_Type 0;
BA_ "GatewayedSignals" SG_ 543 SGU30_Object_Type 0;
BA_ "GenSigInactiveValue" SG_ 543 SGU30_Object_Type 0;
BA_ "GenSigInvalidValue" SG_ 543 SGU30_Object_Type 0;
BA_ "GenSigSendType" SG_ 543 SGU30_Object_Type 1;
BA_ "GenSigStartValue" SG_ 543 SGU30_Object_Type 0;
BA_ "GenSigTimeoutValue" SG_ 543 SGU30_Object_Type 0;
BA_ "Remark" SG_ 543 SGU30_Object_Type "";
BA_ "EventCommandSignal" SG_ 543 SGU30_Object_ax 0;
BA_ "GatewayedSignals" SG_ 543 SGU30_Object_ax 0;
BA_ "GenSigInactiveValue" SG_ 543 SGU30_Object_ax 0;
BA_ "GenSigInvalidValue" SG_ 543 SGU30_Object_ax 0;
BA_ "GenSigSendType" SG_ 543 SGU30_Object_ax 1;
BA_ "GenSigStartValue" SG_ 543 SGU30_Object_ax 0;
BA_ "GenSigTimeoutValue" SG_ 543 SGU30_Object_ax 0;
BA_ "Remark" SG_ 543 SGU30_Object_ax "";
BA_ "EventCommandSignal" SG_ 543 SGU30_Object_ay 0;
BA_ "GatewayedSignals" SG_ 543 SGU30_Object_ay 0;
BA_ "GenSigInactiveValue" SG_ 543 SGU30_Object_ay 0;
BA_ "GenSigInvalidValue" SG_ 543 SGU30_Object_ay 0;
BA_ "GenSigSendType" SG_ 543 SGU30_Object_ay 1;
BA_ "GenSigStartValue" SG_ 543 SGU30_Object_ay 0;
BA_ "GenSigTimeoutValue" SG_ 543 SGU30_Object_ay 0;
BA_ "Remark" SG_ 543 SGU30_Object_ay "";
BA_ "EventCommandSignal" SG_ 543 SGU30_Object_dx 0;
BA_ "GatewayedSignals" SG_ 543 SGU30_Object_dx 0;
BA_ "GenSigInactiveValue" SG_ 543 SGU30_Object_dx 0;
BA_ "GenSigInvalidValue" SG_ 543 SGU30_Object_dx 0;
BA_ "GenSigSendType" SG_ 543 SGU30_Object_dx 1;
BA_ "GenSigStartValue" SG_ 543 SGU30_Object_dx 0;
BA_ "GenSigTimeoutValue" SG_ 543 SGU30_Object_dx 0;
BA_ "Remark" SG_ 543 SGU30_Object_dx "";
BA_ "EventCommandSignal" SG_ 543 SGU30_Object_dx_Rear 0;
BA_ "GatewayedSignals" SG_ 543 SGU30_Object_dx_Rear 0;
BA_ "GenSigInactiveValue" SG_ 543 SGU30_Object_dx_Rear 0;
BA_ "GenSigInvalidValue" SG_ 543 SGU30_Object_dx_Rear 0;
BA_ "GenSigSendType" SG_ 543 SGU30_Object_dx_Rear 1;
BA_ "GenSigStartValue" SG_ 543 SGU30_Object_dx_Rear 0;
BA_ "GenSigTimeoutValue" SG_ 543 SGU30_Object_dx_Rear 0;
BA_ "Remark" SG_ 543 SGU30_Object_dx_Rear "";
BA_ "EventCommandSignal" SG_ 543 SGU30_Object_dy 0;
BA_ "GatewayedSignals" SG_ 543 SGU30_Object_dy 0;
BA_ "GenSigInactiveValue" SG_ 543 SGU30_Object_dy 0;
BA_ "GenSigInvalidValue" SG_ 543 SGU30_Object_dy 0;
BA_ "GenSigSendType" SG_ 543 SGU30_Object_dy 1;
BA_ "GenSigStartValue" SG_ 543 SGU30_Object_dy 0;
BA_ "GenSigTimeoutValue" SG_ 543 SGU30_Object_dy 0;
BA_ "Remark" SG_ 543 SGU30_Object_dy "";
BA_ "EventCommandSignal" SG_ 543 SGU30_Object_dy_Rear 0;
BA_ "GatewayedSignals" SG_ 543 SGU30_Object_dy_Rear 0;
BA_ "GenSigInactiveValue" SG_ 543 SGU30_Object_dy_Rear 0;
BA_ "GenSigInvalidValue" SG_ 543 SGU30_Object_dy_Rear 0;
BA_ "GenSigSendType" SG_ 543 SGU30_Object_dy_Rear 1;
BA_ "GenSigStartValue" SG_ 543 SGU30_Object_dy_Rear 0;
BA_ "GenSigTimeoutValue" SG_ 543 SGU30_Object_dy_Rear 0;
BA_ "Remark" SG_ 543 SGU30_Object_dy_Rear "";
BA_ "EventCommandSignal" SG_ 543 SGU30_Object_vx 0;
BA_ "GatewayedSignals" SG_ 543 SGU30_Object_vx 0;
BA_ "GenSigInactiveValue" SG_ 543 SGU30_Object_vx 0;
BA_ "GenSigInvalidValue" SG_ 543 SGU30_Object_vx 0;
BA_ "GenSigSendType" SG_ 543 SGU30_Object_vx 1;
BA_ "GenSigStartValue" SG_ 543 SGU30_Object_vx 0;
BA_ "GenSigTimeoutValue" SG_ 543 SGU30_Object_vx 0;
BA_ "Remark" SG_ 543 SGU30_Object_vx "";
BA_ "EventCommandSignal" SG_ 543 SGU30_Object_vy 0;
BA_ "GatewayedSignals" SG_ 543 SGU30_Object_vy 0;
BA_ "GenSigInactiveValue" SG_ 543 SGU30_Object_vy 0;
BA_ "GenSigInvalidValue" SG_ 543 SGU30_Object_vy 0;
BA_ "GenSigSendType" SG_ 543 SGU30_Object_vy 1;
BA_ "GenSigStartValue" SG_ 543 SGU30_Object_vy 0;
BA_ "GenSigTimeoutValue" SG_ 543 SGU30_Object_vy 0;
BA_ "Remark" SG_ 543 SGU30_Object_vy "";
BA_ "EventCommandSignal" SG_ 543 SGU30_Object_wExist 0;
BA_ "GatewayedSignals" SG_ 543 SGU30_Object_wExist 0;
BA_ "GenSigInactiveValue" SG_ 543 SGU30_Object_wExist 0;
BA_ "GenSigInvalidValue" SG_ 543 SGU30_Object_wExist 0;
BA_ "GenSigSendType" SG_ 543 SGU30_Object_wExist 1;
BA_ "GenSigStartValue" SG_ 543 SGU30_Object_wExist 0;
BA_ "GenSigTimeoutValue" SG_ 543 SGU30_Object_wExist 0;
BA_ "Remark" SG_ 543 SGU30_Object_wExist "";
BA_ "EventCommandSignal" SG_ 543 SGU30_Object_wObstacle 0;
BA_ "GatewayedSignals" SG_ 543 SGU30_Object_wObstacle 0;
BA_ "GenSigInactiveValue" SG_ 543 SGU30_Object_wObstacle 0;
BA_ "GenSigInvalidValue" SG_ 543 SGU30_Object_wObstacle 0;
BA_ "GenSigSendType" SG_ 543 SGU30_Object_wObstacle 1;
BA_ "GenSigStartValue" SG_ 543 SGU30_Object_wObstacle 0;
BA_ "GenSigTimeoutValue" SG_ 543 SGU30_Object_wObstacle 0;
BA_ "Remark" SG_ 543 SGU30_Object_wObstacle "";
BA_ "EventCommandSignal" SG_ 544 SGU31_BlockCounter 0;
BA_ "GatewayedSignals" SG_ 544 SGU31_BlockCounter 0;
BA_ "GenSigInactiveValue" SG_ 544 SGU31_BlockCounter 0;
BA_ "GenSigInvalidValue" SG_ 544 SGU31_BlockCounter 0;
BA_ "GenSigSendType" SG_ 544 SGU31_BlockCounter 1;
BA_ "GenSigStartValue" SG_ 544 SGU31_BlockCounter 0;
BA_ "GenSigTimeoutValue" SG_ 544 SGU31_BlockCounter 0;
BA_ "Remark" SG_ 544 SGU31_BlockCounter "";
BA_ "EventCommandSignal" SG_ 544 SGU31_LifeCycles_OBJ 0;
BA_ "GatewayedSignals" SG_ 544 SGU31_LifeCycles_OBJ 0;
BA_ "GenSigInactiveValue" SG_ 544 SGU31_LifeCycles_OBJ 0;
BA_ "GenSigInvalidValue" SG_ 544 SGU31_LifeCycles_OBJ 0;
BA_ "GenSigSendType" SG_ 544 SGU31_LifeCycles_OBJ 1;
BA_ "GenSigStartValue" SG_ 544 SGU31_LifeCycles_OBJ 0;
BA_ "GenSigTimeoutValue" SG_ 544 SGU31_LifeCycles_OBJ 0;
BA_ "Remark" SG_ 544 SGU31_LifeCycles_OBJ "";
BA_ "EventCommandSignal" SG_ 544 SGU31_Msg_AliveCounter 0;
BA_ "GatewayedSignals" SG_ 544 SGU31_Msg_AliveCounter 0;
BA_ "GenSigInactiveValue" SG_ 544 SGU31_Msg_AliveCounter 0;
BA_ "GenSigInvalidValue" SG_ 544 SGU31_Msg_AliveCounter 0;
BA_ "GenSigSendType" SG_ 544 SGU31_Msg_AliveCounter 1;
BA_ "GenSigStartValue" SG_ 544 SGU31_Msg_AliveCounter 0;
BA_ "GenSigTimeoutValue" SG_ 544 SGU31_Msg_AliveCounter 0;
BA_ "Remark" SG_ 544 SGU31_Msg_AliveCounter "";
BA_ "EventCommandSignal" SG_ 544 SGU31_Msg_CheckSum 0;
BA_ "GatewayedSignals" SG_ 544 SGU31_Msg_CheckSum 0;
BA_ "GenSigInactiveValue" SG_ 544 SGU31_Msg_CheckSum 0;
BA_ "GenSigInvalidValue" SG_ 544 SGU31_Msg_CheckSum 0;
BA_ "GenSigSendType" SG_ 544 SGU31_Msg_CheckSum 1;
BA_ "GenSigStartValue" SG_ 544 SGU31_Msg_CheckSum 0;
BA_ "GenSigTimeoutValue" SG_ 544 SGU31_Msg_CheckSum 0;
BA_ "Remark" SG_ 544 SGU31_Msg_CheckSum "";
BA_ "EventCommandSignal" SG_ 544 SGU31_ObjRCS_31 0;
BA_ "GatewayedSignals" SG_ 544 SGU31_ObjRCS_31 0;
BA_ "GenSigInactiveValue" SG_ 544 SGU31_ObjRCS_31 0;
BA_ "GenSigInvalidValue" SG_ 544 SGU31_ObjRCS_31 0;
BA_ "GenSigSendType" SG_ 544 SGU31_ObjRCS_31 1;
BA_ "GenSigStartValue" SG_ 544 SGU31_ObjRCS_31 0;
BA_ "GenSigTimeoutValue" SG_ 544 SGU31_ObjRCS_31 0;
BA_ "Remark" SG_ 544 SGU31_ObjRCS_31 "";
BA_ "EventCommandSignal" SG_ 544 SGU31_Obj_DistLat_rms 0;
BA_ "GatewayedSignals" SG_ 544 SGU31_Obj_DistLat_rms 0;
BA_ "GenSigInactiveValue" SG_ 544 SGU31_Obj_DistLat_rms 0;
BA_ "GenSigInvalidValue" SG_ 544 SGU31_Obj_DistLat_rms 0;
BA_ "GenSigSendType" SG_ 544 SGU31_Obj_DistLat_rms 1;
BA_ "GenSigStartValue" SG_ 544 SGU31_Obj_DistLat_rms 0;
BA_ "GenSigTimeoutValue" SG_ 544 SGU31_Obj_DistLat_rms 0;
BA_ "Remark" SG_ 544 SGU31_Obj_DistLat_rms "";
BA_ "EventCommandSignal" SG_ 544 SGU31_Obj_VrelLong_rms 0;
BA_ "GatewayedSignals" SG_ 544 SGU31_Obj_VrelLong_rms 0;
BA_ "GenSigInactiveValue" SG_ 544 SGU31_Obj_VrelLong_rms 0;
BA_ "GenSigInvalidValue" SG_ 544 SGU31_Obj_VrelLong_rms 0;
BA_ "GenSigSendType" SG_ 544 SGU31_Obj_VrelLong_rms 1;
BA_ "GenSigStartValue" SG_ 544 SGU31_Obj_VrelLong_rms 0;
BA_ "GenSigTimeoutValue" SG_ 544 SGU31_Obj_VrelLong_rms 0;
BA_ "Remark" SG_ 544 SGU31_Obj_VrelLong_rms "";
BA_ "EventCommandSignal" SG_ 544 SGU31_Obj_Vrelat_rms 0;
BA_ "GatewayedSignals" SG_ 544 SGU31_Obj_Vrelat_rms 0;
BA_ "GenSigInactiveValue" SG_ 544 SGU31_Obj_Vrelat_rms 0;
BA_ "GenSigInvalidValue" SG_ 544 SGU31_Obj_Vrelat_rms 0;
BA_ "GenSigSendType" SG_ 544 SGU31_Obj_Vrelat_rms 1;
BA_ "GenSigStartValue" SG_ 544 SGU31_Obj_Vrelat_rms 0;
BA_ "GenSigTimeoutValue" SG_ 544 SGU31_Obj_Vrelat_rms 0;
BA_ "Remark" SG_ 544 SGU31_Obj_Vrelat_rms "";
BA_ "EventCommandSignal" SG_ 544 SGU31_Object_DetStatus 0;
BA_ "GatewayedSignals" SG_ 544 SGU31_Object_DetStatus 0;
BA_ "GenSigInactiveValue" SG_ 544 SGU31_Object_DetStatus 0;
BA_ "GenSigInvalidValue" SG_ 544 SGU31_Object_DetStatus 0;
BA_ "GenSigSendType" SG_ 544 SGU31_Object_DetStatus 1;
BA_ "GenSigStartValue" SG_ 544 SGU31_Object_DetStatus 0;
BA_ "GenSigTimeoutValue" SG_ 544 SGU31_Object_DetStatus 0;
BA_ "Remark" SG_ 544 SGU31_Object_DetStatus "";
BA_ "EventCommandSignal" SG_ 544 SGU31_Object_DistLong_rms 0;
BA_ "GatewayedSignals" SG_ 544 SGU31_Object_DistLong_rms 0;
BA_ "GenSigInactiveValue" SG_ 544 SGU31_Object_DistLong_rms 0;
BA_ "GenSigInvalidValue" SG_ 544 SGU31_Object_DistLong_rms 0;
BA_ "GenSigSendType" SG_ 544 SGU31_Object_DistLong_rms 1;
BA_ "GenSigStartValue" SG_ 544 SGU31_Object_DistLong_rms 0;
BA_ "GenSigTimeoutValue" SG_ 544 SGU31_Object_DistLong_rms 0;
BA_ "Remark" SG_ 544 SGU31_Object_DistLong_rms "";
BA_ "EventCommandSignal" SG_ 544 SGU31_Object_ID 0;
BA_ "GatewayedSignals" SG_ 544 SGU31_Object_ID 0;
BA_ "GenSigInactiveValue" SG_ 544 SGU31_Object_ID 0;
BA_ "GenSigInvalidValue" SG_ 544 SGU31_Object_ID 0;
BA_ "GenSigSendType" SG_ 544 SGU31_Object_ID 1;
BA_ "GenSigStartValue" SG_ 544 SGU31_Object_ID 0;
BA_ "GenSigTimeoutValue" SG_ 544 SGU31_Object_ID 0;
BA_ "Remark" SG_ 544 SGU31_Object_ID "";
BA_ "EventCommandSignal" SG_ 544 SGU31_Object_Motion_Pattern 0;
BA_ "GatewayedSignals" SG_ 544 SGU31_Object_Motion_Pattern 0;
BA_ "GenSigInactiveValue" SG_ 544 SGU31_Object_Motion_Pattern 0;
BA_ "GenSigInvalidValue" SG_ 544 SGU31_Object_Motion_Pattern 0;
BA_ "GenSigSendType" SG_ 544 SGU31_Object_Motion_Pattern 1;
BA_ "GenSigStartValue" SG_ 544 SGU31_Object_Motion_Pattern 0;
BA_ "GenSigTimeoutValue" SG_ 544 SGU31_Object_Motion_Pattern 0;
BA_ "Remark" SG_ 544 SGU31_Object_Motion_Pattern "";
BA_ "EventCommandSignal" SG_ 544 SGU31_Object_Type 0;
BA_ "GatewayedSignals" SG_ 544 SGU31_Object_Type 0;
BA_ "GenSigInactiveValue" SG_ 544 SGU31_Object_Type 0;
BA_ "GenSigInvalidValue" SG_ 544 SGU31_Object_Type 0;
BA_ "GenSigSendType" SG_ 544 SGU31_Object_Type 1;
BA_ "GenSigStartValue" SG_ 544 SGU31_Object_Type 0;
BA_ "GenSigTimeoutValue" SG_ 544 SGU31_Object_Type 0;
BA_ "Remark" SG_ 544 SGU31_Object_Type "";
BA_ "EventCommandSignal" SG_ 544 SGU31_Object_ax 0;
BA_ "GatewayedSignals" SG_ 544 SGU31_Object_ax 0;
BA_ "GenSigInactiveValue" SG_ 544 SGU31_Object_ax 0;
BA_ "GenSigInvalidValue" SG_ 544 SGU31_Object_ax 0;
BA_ "GenSigSendType" SG_ 544 SGU31_Object_ax 1;
BA_ "GenSigStartValue" SG_ 544 SGU31_Object_ax 0;
BA_ "GenSigTimeoutValue" SG_ 544 SGU31_Object_ax 0;
BA_ "Remark" SG_ 544 SGU31_Object_ax "";
BA_ "EventCommandSignal" SG_ 544 SGU31_Object_ay 0;
BA_ "GatewayedSignals" SG_ 544 SGU31_Object_ay 0;
BA_ "GenSigInactiveValue" SG_ 544 SGU31_Object_ay 0;
BA_ "GenSigInvalidValue" SG_ 544 SGU31_Object_ay 0;
BA_ "GenSigSendType" SG_ 544 SGU31_Object_ay 1;
BA_ "GenSigStartValue" SG_ 544 SGU31_Object_ay 0;
BA_ "GenSigTimeoutValue" SG_ 544 SGU31_Object_ay 0;
BA_ "Remark" SG_ 544 SGU31_Object_ay "";
BA_ "EventCommandSignal" SG_ 544 SGU31_Object_dx 0;
BA_ "GatewayedSignals" SG_ 544 SGU31_Object_dx 0;
BA_ "GenSigInactiveValue" SG_ 544 SGU31_Object_dx 0;
BA_ "GenSigInvalidValue" SG_ 544 SGU31_Object_dx 0;
BA_ "GenSigSendType" SG_ 544 SGU31_Object_dx 1;
BA_ "GenSigStartValue" SG_ 544 SGU31_Object_dx 0;
BA_ "GenSigTimeoutValue" SG_ 544 SGU31_Object_dx 0;
BA_ "Remark" SG_ 544 SGU31_Object_dx "";
BA_ "EventCommandSignal" SG_ 544 SGU31_Object_dx_Rear 0;
BA_ "GatewayedSignals" SG_ 544 SGU31_Object_dx_Rear 0;
BA_ "GenSigInactiveValue" SG_ 544 SGU31_Object_dx_Rear 0;
BA_ "GenSigInvalidValue" SG_ 544 SGU31_Object_dx_Rear 0;
BA_ "GenSigSendType" SG_ 544 SGU31_Object_dx_Rear 1;
BA_ "GenSigStartValue" SG_ 544 SGU31_Object_dx_Rear 0;
BA_ "GenSigTimeoutValue" SG_ 544 SGU31_Object_dx_Rear 0;
BA_ "Remark" SG_ 544 SGU31_Object_dx_Rear "";
BA_ "EventCommandSignal" SG_ 544 SGU31_Object_dy 0;
BA_ "GatewayedSignals" SG_ 544 SGU31_Object_dy 0;
BA_ "GenSigInactiveValue" SG_ 544 SGU31_Object_dy 0;
BA_ "GenSigInvalidValue" SG_ 544 SGU31_Object_dy 0;
BA_ "GenSigSendType" SG_ 544 SGU31_Object_dy 1;
BA_ "GenSigStartValue" SG_ 544 SGU31_Object_dy 0;
BA_ "GenSigTimeoutValue" SG_ 544 SGU31_Object_dy 0;
BA_ "Remark" SG_ 544 SGU31_Object_dy "";
BA_ "EventCommandSignal" SG_ 544 SGU31_Object_dy_Rear 0;
BA_ "GatewayedSignals" SG_ 544 SGU31_Object_dy_Rear 0;
BA_ "GenSigInactiveValue" SG_ 544 SGU31_Object_dy_Rear 0;
BA_ "GenSigInvalidValue" SG_ 544 SGU31_Object_dy_Rear 0;
BA_ "GenSigSendType" SG_ 544 SGU31_Object_dy_Rear 1;
BA_ "GenSigStartValue" SG_ 544 SGU31_Object_dy_Rear 0;
BA_ "GenSigTimeoutValue" SG_ 544 SGU31_Object_dy_Rear 0;
BA_ "Remark" SG_ 544 SGU31_Object_dy_Rear "";
BA_ "EventCommandSignal" SG_ 544 SGU31_Object_vx 0;
BA_ "GatewayedSignals" SG_ 544 SGU31_Object_vx 0;
BA_ "GenSigInactiveValue" SG_ 544 SGU31_Object_vx 0;
BA_ "GenSigInvalidValue" SG_ 544 SGU31_Object_vx 0;
BA_ "GenSigSendType" SG_ 544 SGU31_Object_vx 1;
BA_ "GenSigStartValue" SG_ 544 SGU31_Object_vx 0;
BA_ "GenSigTimeoutValue" SG_ 544 SGU31_Object_vx 0;
BA_ "Remark" SG_ 544 SGU31_Object_vx "";
BA_ "EventCommandSignal" SG_ 544 SGU31_Object_vy 0;
BA_ "GatewayedSignals" SG_ 544 SGU31_Object_vy 0;
BA_ "GenSigInactiveValue" SG_ 544 SGU31_Object_vy 0;
BA_ "GenSigInvalidValue" SG_ 544 SGU31_Object_vy 0;
BA_ "GenSigSendType" SG_ 544 SGU31_Object_vy 1;
BA_ "GenSigStartValue" SG_ 544 SGU31_Object_vy 0;
BA_ "GenSigTimeoutValue" SG_ 544 SGU31_Object_vy 0;
BA_ "Remark" SG_ 544 SGU31_Object_vy "";
BA_ "EventCommandSignal" SG_ 544 SGU31_Object_wExist 0;
BA_ "GatewayedSignals" SG_ 544 SGU31_Object_wExist 0;
BA_ "GenSigInactiveValue" SG_ 544 SGU31_Object_wExist 0;
BA_ "GenSigInvalidValue" SG_ 544 SGU31_Object_wExist 0;
BA_ "GenSigSendType" SG_ 544 SGU31_Object_wExist 1;
BA_ "GenSigStartValue" SG_ 544 SGU31_Object_wExist 0;
BA_ "GenSigTimeoutValue" SG_ 544 SGU31_Object_wExist 0;
BA_ "Remark" SG_ 544 SGU31_Object_wExist "";
BA_ "EventCommandSignal" SG_ 544 SGU31_Object_wObstacle 0;
BA_ "GatewayedSignals" SG_ 544 SGU31_Object_wObstacle 0;
BA_ "GenSigInactiveValue" SG_ 544 SGU31_Object_wObstacle 0;
BA_ "GenSigInvalidValue" SG_ 544 SGU31_Object_wObstacle 0;
BA_ "GenSigSendType" SG_ 544 SGU31_Object_wObstacle 1;
BA_ "GenSigStartValue" SG_ 544 SGU31_Object_wObstacle 0;
BA_ "GenSigTimeoutValue" SG_ 544 SGU31_Object_wObstacle 0;
BA_ "Remark" SG_ 544 SGU31_Object_wObstacle "";
BA_ "EventCommandSignal" SG_ 545 SGU32_BlockCounter 0;
BA_ "GatewayedSignals" SG_ 545 SGU32_BlockCounter 0;
BA_ "GenSigInactiveValue" SG_ 545 SGU32_BlockCounter 0;
BA_ "GenSigInvalidValue" SG_ 545 SGU32_BlockCounter 0;
BA_ "GenSigSendType" SG_ 545 SGU32_BlockCounter 1;
BA_ "GenSigStartValue" SG_ 545 SGU32_BlockCounter 0;
BA_ "GenSigTimeoutValue" SG_ 545 SGU32_BlockCounter 0;
BA_ "Remark" SG_ 545 SGU32_BlockCounter "";
BA_ "EventCommandSignal" SG_ 545 SGU32_LifeCycles_OBJ 0;
BA_ "GatewayedSignals" SG_ 545 SGU32_LifeCycles_OBJ 0;
BA_ "GenSigInactiveValue" SG_ 545 SGU32_LifeCycles_OBJ 0;
BA_ "GenSigInvalidValue" SG_ 545 SGU32_LifeCycles_OBJ 0;
BA_ "GenSigSendType" SG_ 545 SGU32_LifeCycles_OBJ 1;
BA_ "GenSigStartValue" SG_ 545 SGU32_LifeCycles_OBJ 0;
BA_ "GenSigTimeoutValue" SG_ 545 SGU32_LifeCycles_OBJ 0;
BA_ "Remark" SG_ 545 SGU32_LifeCycles_OBJ "";
BA_ "EventCommandSignal" SG_ 545 SGU32_Msg_AliveCounter 0;
BA_ "GatewayedSignals" SG_ 545 SGU32_Msg_AliveCounter 0;
BA_ "GenSigInactiveValue" SG_ 545 SGU32_Msg_AliveCounter 0;
BA_ "GenSigInvalidValue" SG_ 545 SGU32_Msg_AliveCounter 0;
BA_ "GenSigSendType" SG_ 545 SGU32_Msg_AliveCounter 1;
BA_ "GenSigStartValue" SG_ 545 SGU32_Msg_AliveCounter 0;
BA_ "GenSigTimeoutValue" SG_ 545 SGU32_Msg_AliveCounter 0;
BA_ "Remark" SG_ 545 SGU32_Msg_AliveCounter "";
BA_ "EventCommandSignal" SG_ 545 SGU32_Msg_CheckSum 0;
BA_ "GatewayedSignals" SG_ 545 SGU32_Msg_CheckSum 0;
BA_ "GenSigInactiveValue" SG_ 545 SGU32_Msg_CheckSum 0;
BA_ "GenSigInvalidValue" SG_ 545 SGU32_Msg_CheckSum 0;
BA_ "GenSigSendType" SG_ 545 SGU32_Msg_CheckSum 1;
BA_ "GenSigStartValue" SG_ 545 SGU32_Msg_CheckSum 0;
BA_ "GenSigTimeoutValue" SG_ 545 SGU32_Msg_CheckSum 0;
BA_ "Remark" SG_ 545 SGU32_Msg_CheckSum "";
BA_ "EventCommandSignal" SG_ 545 SGU32_ObjRCS_32 0;
BA_ "GatewayedSignals" SG_ 545 SGU32_ObjRCS_32 0;
BA_ "GenSigInactiveValue" SG_ 545 SGU32_ObjRCS_32 0;
BA_ "GenSigInvalidValue" SG_ 545 SGU32_ObjRCS_32 0;
BA_ "GenSigSendType" SG_ 545 SGU32_ObjRCS_32 1;
BA_ "GenSigStartValue" SG_ 545 SGU32_ObjRCS_32 0;
BA_ "GenSigTimeoutValue" SG_ 545 SGU32_ObjRCS_32 0;
BA_ "Remark" SG_ 545 SGU32_ObjRCS_32 "";
BA_ "EventCommandSignal" SG_ 545 SGU32_Obj_DistLat_rms 0;
BA_ "GatewayedSignals" SG_ 545 SGU32_Obj_DistLat_rms 0;
BA_ "GenSigInactiveValue" SG_ 545 SGU32_Obj_DistLat_rms 0;
BA_ "GenSigInvalidValue" SG_ 545 SGU32_Obj_DistLat_rms 0;
BA_ "GenSigSendType" SG_ 545 SGU32_Obj_DistLat_rms 1;
BA_ "GenSigStartValue" SG_ 545 SGU32_Obj_DistLat_rms 0;
BA_ "GenSigTimeoutValue" SG_ 545 SGU32_Obj_DistLat_rms 0;
BA_ "Remark" SG_ 545 SGU32_Obj_DistLat_rms "";
BA_ "EventCommandSignal" SG_ 545 SGU32_Obj_VrelLong_rms 0;
BA_ "GatewayedSignals" SG_ 545 SGU32_Obj_VrelLong_rms 0;
BA_ "GenSigInactiveValue" SG_ 545 SGU32_Obj_VrelLong_rms 0;
BA_ "GenSigInvalidValue" SG_ 545 SGU32_Obj_VrelLong_rms 0;
BA_ "GenSigSendType" SG_ 545 SGU32_Obj_VrelLong_rms 1;
BA_ "GenSigStartValue" SG_ 545 SGU32_Obj_VrelLong_rms 0;
BA_ "GenSigTimeoutValue" SG_ 545 SGU32_Obj_VrelLong_rms 0;
BA_ "Remark" SG_ 545 SGU32_Obj_VrelLong_rms "";
BA_ "EventCommandSignal" SG_ 545 SGU32_Obj_Vrelat_rms 0;
BA_ "GatewayedSignals" SG_ 545 SGU32_Obj_Vrelat_rms 0;
BA_ "GenSigInactiveValue" SG_ 545 SGU32_Obj_Vrelat_rms 0;
BA_ "GenSigInvalidValue" SG_ 545 SGU32_Obj_Vrelat_rms 0;
BA_ "GenSigSendType" SG_ 545 SGU32_Obj_Vrelat_rms 1;
BA_ "GenSigStartValue" SG_ 545 SGU32_Obj_Vrelat_rms 0;
BA_ "GenSigTimeoutValue" SG_ 545 SGU32_Obj_Vrelat_rms 0;
BA_ "Remark" SG_ 545 SGU32_Obj_Vrelat_rms "";
BA_ "EventCommandSignal" SG_ 545 SGU32_Object_DetStatus 0;
BA_ "GatewayedSignals" SG_ 545 SGU32_Object_DetStatus 0;
BA_ "GenSigInactiveValue" SG_ 545 SGU32_Object_DetStatus 0;
BA_ "GenSigInvalidValue" SG_ 545 SGU32_Object_DetStatus 0;
BA_ "GenSigSendType" SG_ 545 SGU32_Object_DetStatus 1;
BA_ "GenSigStartValue" SG_ 545 SGU32_Object_DetStatus 0;
BA_ "GenSigTimeoutValue" SG_ 545 SGU32_Object_DetStatus 0;
BA_ "Remark" SG_ 545 SGU32_Object_DetStatus "";
BA_ "EventCommandSignal" SG_ 545 SGU32_Object_DistLong_rms 0;
BA_ "GatewayedSignals" SG_ 545 SGU32_Object_DistLong_rms 0;
BA_ "GenSigInactiveValue" SG_ 545 SGU32_Object_DistLong_rms 0;
BA_ "GenSigInvalidValue" SG_ 545 SGU32_Object_DistLong_rms 0;
BA_ "GenSigSendType" SG_ 545 SGU32_Object_DistLong_rms 1;
BA_ "GenSigStartValue" SG_ 545 SGU32_Object_DistLong_rms 0;
BA_ "GenSigTimeoutValue" SG_ 545 SGU32_Object_DistLong_rms 0;
BA_ "Remark" SG_ 545 SGU32_Object_DistLong_rms "";
BA_ "EventCommandSignal" SG_ 545 SGU32_Object_ID 0;
BA_ "GatewayedSignals" SG_ 545 SGU32_Object_ID 0;
BA_ "GenSigInactiveValue" SG_ 545 SGU32_Object_ID 0;
BA_ "GenSigInvalidValue" SG_ 545 SGU32_Object_ID 0;
BA_ "GenSigSendType" SG_ 545 SGU32_Object_ID 1;
BA_ "GenSigStartValue" SG_ 545 SGU32_Object_ID 0;
BA_ "GenSigTimeoutValue" SG_ 545 SGU32_Object_ID 0;
BA_ "Remark" SG_ 545 SGU32_Object_ID "";
BA_ "EventCommandSignal" SG_ 545 SGU32_Object_Motion_Pattern 0;
BA_ "GatewayedSignals" SG_ 545 SGU32_Object_Motion_Pattern 0;
BA_ "GenSigInactiveValue" SG_ 545 SGU32_Object_Motion_Pattern 0;
BA_ "GenSigInvalidValue" SG_ 545 SGU32_Object_Motion_Pattern 0;
BA_ "GenSigSendType" SG_ 545 SGU32_Object_Motion_Pattern 1;
BA_ "GenSigStartValue" SG_ 545 SGU32_Object_Motion_Pattern 0;
BA_ "GenSigTimeoutValue" SG_ 545 SGU32_Object_Motion_Pattern 0;
BA_ "Remark" SG_ 545 SGU32_Object_Motion_Pattern "";
BA_ "EventCommandSignal" SG_ 545 SGU32_Object_Type 0;
BA_ "GatewayedSignals" SG_ 545 SGU32_Object_Type 0;
BA_ "GenSigInactiveValue" SG_ 545 SGU32_Object_Type 0;
BA_ "GenSigInvalidValue" SG_ 545 SGU32_Object_Type 0;
BA_ "GenSigSendType" SG_ 545 SGU32_Object_Type 1;
BA_ "GenSigStartValue" SG_ 545 SGU32_Object_Type 0;
BA_ "GenSigTimeoutValue" SG_ 545 SGU32_Object_Type 0;
BA_ "Remark" SG_ 545 SGU32_Object_Type "";
BA_ "EventCommandSignal" SG_ 545 SGU32_Object_ax 0;
BA_ "GatewayedSignals" SG_ 545 SGU32_Object_ax 0;
BA_ "GenSigInactiveValue" SG_ 545 SGU32_Object_ax 0;
BA_ "GenSigInvalidValue" SG_ 545 SGU32_Object_ax 0;
BA_ "GenSigSendType" SG_ 545 SGU32_Object_ax 1;
BA_ "GenSigStartValue" SG_ 545 SGU32_Object_ax 0;
BA_ "GenSigTimeoutValue" SG_ 545 SGU32_Object_ax 0;
BA_ "Remark" SG_ 545 SGU32_Object_ax "";
BA_ "EventCommandSignal" SG_ 545 SGU32_Object_ay 0;
BA_ "GatewayedSignals" SG_ 545 SGU32_Object_ay 0;
BA_ "GenSigInactiveValue" SG_ 545 SGU32_Object_ay 0;
BA_ "GenSigInvalidValue" SG_ 545 SGU32_Object_ay 0;
BA_ "GenSigSendType" SG_ 545 SGU32_Object_ay 1;
BA_ "GenSigStartValue" SG_ 545 SGU32_Object_ay 0;
BA_ "GenSigTimeoutValue" SG_ 545 SGU32_Object_ay 0;
BA_ "Remark" SG_ 545 SGU32_Object_ay "";
BA_ "EventCommandSignal" SG_ 545 SGU32_Object_dx 0;
BA_ "GatewayedSignals" SG_ 545 SGU32_Object_dx 0;
BA_ "GenSigInactiveValue" SG_ 545 SGU32_Object_dx 0;
BA_ "GenSigInvalidValue" SG_ 545 SGU32_Object_dx 0;
BA_ "GenSigSendType" SG_ 545 SGU32_Object_dx 1;
BA_ "GenSigStartValue" SG_ 545 SGU32_Object_dx 0;
BA_ "GenSigTimeoutValue" SG_ 545 SGU32_Object_dx 0;
BA_ "Remark" SG_ 545 SGU32_Object_dx "";
BA_ "EventCommandSignal" SG_ 545 SGU32_Object_dx_Rear 0;
BA_ "GatewayedSignals" SG_ 545 SGU32_Object_dx_Rear 0;
BA_ "GenSigInactiveValue" SG_ 545 SGU32_Object_dx_Rear 0;
BA_ "GenSigInvalidValue" SG_ 545 SGU32_Object_dx_Rear 0;
BA_ "GenSigSendType" SG_ 545 SGU32_Object_dx_Rear 1;
BA_ "GenSigStartValue" SG_ 545 SGU32_Object_dx_Rear 0;
BA_ "GenSigTimeoutValue" SG_ 545 SGU32_Object_dx_Rear 0;
BA_ "Remark" SG_ 545 SGU32_Object_dx_Rear "";
BA_ "EventCommandSignal" SG_ 545 SGU32_Object_dy 0;
BA_ "GatewayedSignals" SG_ 545 SGU32_Object_dy 0;
BA_ "GenSigInactiveValue" SG_ 545 SGU32_Object_dy 0;
BA_ "GenSigInvalidValue" SG_ 545 SGU32_Object_dy 0;
BA_ "GenSigSendType" SG_ 545 SGU32_Object_dy 1;
BA_ "GenSigStartValue" SG_ 545 SGU32_Object_dy 0;
BA_ "GenSigTimeoutValue" SG_ 545 SGU32_Object_dy 0;
BA_ "Remark" SG_ 545 SGU32_Object_dy "";
BA_ "EventCommandSignal" SG_ 545 SGU32_Object_dy_Rear 0;
BA_ "GatewayedSignals" SG_ 545 SGU32_Object_dy_Rear 0;
BA_ "GenSigInactiveValue" SG_ 545 SGU32_Object_dy_Rear 0;
BA_ "GenSigInvalidValue" SG_ 545 SGU32_Object_dy_Rear 0;
BA_ "GenSigSendType" SG_ 545 SGU32_Object_dy_Rear 1;
BA_ "GenSigStartValue" SG_ 545 SGU32_Object_dy_Rear 0;
BA_ "GenSigTimeoutValue" SG_ 545 SGU32_Object_dy_Rear 0;
BA_ "Remark" SG_ 545 SGU32_Object_dy_Rear "";
BA_ "EventCommandSignal" SG_ 545 SGU32_Object_vx 0;
BA_ "GatewayedSignals" SG_ 545 SGU32_Object_vx 0;
BA_ "GenSigInactiveValue" SG_ 545 SGU32_Object_vx 0;
BA_ "GenSigInvalidValue" SG_ 545 SGU32_Object_vx 0;
BA_ "GenSigSendType" SG_ 545 SGU32_Object_vx 1;
BA_ "GenSigStartValue" SG_ 545 SGU32_Object_vx 0;
BA_ "GenSigTimeoutValue" SG_ 545 SGU32_Object_vx 0;
BA_ "Remark" SG_ 545 SGU32_Object_vx "";
BA_ "EventCommandSignal" SG_ 545 SGU32_Object_vy 0;
BA_ "GatewayedSignals" SG_ 545 SGU32_Object_vy 0;
BA_ "GenSigInactiveValue" SG_ 545 SGU32_Object_vy 0;
BA_ "GenSigInvalidValue" SG_ 545 SGU32_Object_vy 0;
BA_ "GenSigSendType" SG_ 545 SGU32_Object_vy 1;
BA_ "GenSigStartValue" SG_ 545 SGU32_Object_vy 0;
BA_ "GenSigTimeoutValue" SG_ 545 SGU32_Object_vy 0;
BA_ "Remark" SG_ 545 SGU32_Object_vy "";
BA_ "EventCommandSignal" SG_ 545 SGU32_Object_wExist 0;
BA_ "GatewayedSignals" SG_ 545 SGU32_Object_wExist 0;
BA_ "GenSigInactiveValue" SG_ 545 SGU32_Object_wExist 0;
BA_ "GenSigInvalidValue" SG_ 545 SGU32_Object_wExist 0;
BA_ "GenSigSendType" SG_ 545 SGU32_Object_wExist 1;
BA_ "GenSigStartValue" SG_ 545 SGU32_Object_wExist 0;
BA_ "GenSigTimeoutValue" SG_ 545 SGU32_Object_wExist 0;
BA_ "Remark" SG_ 545 SGU32_Object_wExist "";
BA_ "EventCommandSignal" SG_ 545 SGU32_Object_wObstacle 0;
BA_ "GatewayedSignals" SG_ 545 SGU32_Object_wObstacle 0;
BA_ "GenSigInactiveValue" SG_ 545 SGU32_Object_wObstacle 0;
BA_ "GenSigInvalidValue" SG_ 545 SGU32_Object_wObstacle 0;
BA_ "GenSigSendType" SG_ 545 SGU32_Object_wObstacle 1;
BA_ "GenSigStartValue" SG_ 545 SGU32_Object_wObstacle 0;
BA_ "GenSigTimeoutValue" SG_ 545 SGU32_Object_wObstacle 0;
BA_ "Remark" SG_ 545 SGU32_Object_wObstacle "";
BA_ "EventCommandSignal" SG_ 546 AngleEMEIndicatorAz 0;
BA_ "GatewayedSignals" SG_ 546 AngleEMEIndicatorAz 0;
BA_ "GenSigInactiveValue" SG_ 546 AngleEMEIndicatorAz 0;
BA_ "GenSigInvalidValue" SG_ 546 AngleEMEIndicatorAz 0;
BA_ "GenSigSendType" SG_ 546 AngleEMEIndicatorAz 1;
BA_ "GenSigStartValue" SG_ 546 AngleEMEIndicatorAz 0;
BA_ "GenSigTimeoutValue" SG_ 546 AngleEMEIndicatorAz 0;
BA_ "Remark" SG_ 546 AngleEMEIndicatorAz "";
BA_ "EventCommandSignal" SG_ 546 AngleEMEIndicatorEl 0;
BA_ "GatewayedSignals" SG_ 546 AngleEMEIndicatorEl 0;
BA_ "GenSigInactiveValue" SG_ 546 AngleEMEIndicatorEl 0;
BA_ "GenSigInvalidValue" SG_ 546 AngleEMEIndicatorEl 0;
BA_ "GenSigSendType" SG_ 546 AngleEMEIndicatorEl 1;
BA_ "GenSigStartValue" SG_ 546 AngleEMEIndicatorEl 0;
BA_ "GenSigTimeoutValue" SG_ 546 AngleEMEIndicatorEl 0;
BA_ "Remark" SG_ 546 AngleEMEIndicatorEl "";
BA_ "EventCommandSignal" SG_ 546 FLR_Blindness_FaultSts 0;
BA_ "GatewayedSignals" SG_ 546 FLR_Blindness_FaultSts 0;
BA_ "GenSigInactiveValue" SG_ 546 FLR_Blindness_FaultSts 0;
BA_ "GenSigInvalidValue" SG_ 546 FLR_Blindness_FaultSts 0;
BA_ "GenSigSendType" SG_ 546 FLR_Blindness_FaultSts 1;
BA_ "GenSigStartValue" SG_ 546 FLR_Blindness_FaultSts 0;
BA_ "GenSigTimeoutValue" SG_ 546 FLR_Blindness_FaultSts 0;
BA_ "Remark" SG_ 546 FLR_Blindness_FaultSts "";
BA_ "EventCommandSignal" SG_ 546 FLR_DTC_ALIGNMENT_NOT_DONE 0;
BA_ "GatewayedSignals" SG_ 546 FLR_DTC_ALIGNMENT_NOT_DONE 0;
BA_ "GenSigInactiveValue" SG_ 546 FLR_DTC_ALIGNMENT_NOT_DONE 0;
BA_ "GenSigInvalidValue" SG_ 546 FLR_DTC_ALIGNMENT_NOT_DONE 0;
BA_ "GenSigSendType" SG_ 546 FLR_DTC_ALIGNMENT_NOT_DONE 1;
BA_ "GenSigStartValue" SG_ 546 FLR_DTC_ALIGNMENT_NOT_DONE 0;
BA_ "GenSigTimeoutValue" SG_ 546 FLR_DTC_ALIGNMENT_NOT_DONE 0;
BA_ "Remark" SG_ 546 FLR_DTC_ALIGNMENT_NOT_DONE "";
BA_ "EventCommandSignal" SG_ 546 FLR_DTC_CORNER_RADAR_BLIND 0;
BA_ "GatewayedSignals" SG_ 546 FLR_DTC_CORNER_RADAR_BLIND 0;
BA_ "GenSigInactiveValue" SG_ 546 FLR_DTC_CORNER_RADAR_BLIND 0;
BA_ "GenSigInvalidValue" SG_ 546 FLR_DTC_CORNER_RADAR_BLIND 0;
BA_ "GenSigSendType" SG_ 546 FLR_DTC_CORNER_RADAR_BLIND 1;
BA_ "GenSigStartValue" SG_ 546 FLR_DTC_CORNER_RADAR_BLIND 0;
BA_ "GenSigTimeoutValue" SG_ 546 FLR_DTC_CORNER_RADAR_BLIND 0;
BA_ "Remark" SG_ 546 FLR_DTC_CORNER_RADAR_BLIND "";
BA_ "EventCommandSignal" SG_ 546 FLR_DTC_CORNER_RADAR_MISALIGNED 0;
BA_ "GatewayedSignals" SG_ 546 FLR_DTC_CORNER_RADAR_MISALIGNED 0;
BA_ "GenSigInactiveValue" SG_ 546 FLR_DTC_CORNER_RADAR_MISALIGNED 0;
BA_ "GenSigInvalidValue" SG_ 546 FLR_DTC_CORNER_RADAR_MISALIGNED 0;
BA_ "GenSigSendType" SG_ 546 FLR_DTC_CORNER_RADAR_MISALIGNED 1;
BA_ "GenSigStartValue" SG_ 546 FLR_DTC_CORNER_RADAR_MISALIGNED 0;
BA_ "GenSigTimeoutValue" SG_ 546 FLR_DTC_CORNER_RADAR_MISALIGNED 0;
BA_ "Remark" SG_ 546 FLR_DTC_CORNER_RADAR_MISALIGNED "";
BA_ "EventCommandSignal" SG_ 546 FLR_DTC_DACORE_OOS 0;
BA_ "GatewayedSignals" SG_ 546 FLR_DTC_DACORE_OOS 0;
BA_ "GenSigInactiveValue" SG_ 546 FLR_DTC_DACORE_OOS 0;
BA_ "GenSigInvalidValue" SG_ 546 FLR_DTC_DACORE_OOS 0;
BA_ "GenSigSendType" SG_ 546 FLR_DTC_DACORE_OOS 1;
BA_ "GenSigStartValue" SG_ 546 FLR_DTC_DACORE_OOS 0;
BA_ "GenSigTimeoutValue" SG_ 546 FLR_DTC_DACORE_OOS 0;
BA_ "Remark" SG_ 546 FLR_DTC_DACORE_OOS "";
BA_ "EventCommandSignal" SG_ 546 FLR_DTC_DSP_FAILURE 0;
BA_ "GatewayedSignals" SG_ 546 FLR_DTC_DSP_FAILURE 0;
BA_ "GenSigInactiveValue" SG_ 546 FLR_DTC_DSP_FAILURE 0;
BA_ "GenSigInvalidValue" SG_ 546 FLR_DTC_DSP_FAILURE 0;
BA_ "GenSigSendType" SG_ 546 FLR_DTC_DSP_FAILURE 1;
BA_ "GenSigStartValue" SG_ 546 FLR_DTC_DSP_FAILURE 0;
BA_ "GenSigTimeoutValue" SG_ 546 FLR_DTC_DSP_FAILURE 0;
BA_ "Remark" SG_ 546 FLR_DTC_DSP_FAILURE "";
BA_ "EventCommandSignal" SG_ 546 FLR_DTC_HARDWARE_FAILURE 0;
BA_ "GatewayedSignals" SG_ 546 FLR_DTC_HARDWARE_FAILURE 0;
BA_ "GenSigInactiveValue" SG_ 546 FLR_DTC_HARDWARE_FAILURE 0;
BA_ "GenSigInvalidValue" SG_ 546 FLR_DTC_HARDWARE_FAILURE 0;
BA_ "GenSigSendType" SG_ 546 FLR_DTC_HARDWARE_FAILURE 1;
BA_ "GenSigStartValue" SG_ 546 FLR_DTC_HARDWARE_FAILURE 0;
BA_ "GenSigTimeoutValue" SG_ 546 FLR_DTC_HARDWARE_FAILURE 0;
BA_ "Remark" SG_ 546 FLR_DTC_HARDWARE_FAILURE "";
BA_ "EventCommandSignal" SG_ 546 FLR_DTC_INVALID_DATA_BCS 0;
BA_ "GatewayedSignals" SG_ 546 FLR_DTC_INVALID_DATA_BCS 0;
BA_ "GenSigInactiveValue" SG_ 546 FLR_DTC_INVALID_DATA_BCS 0;
BA_ "GenSigInvalidValue" SG_ 546 FLR_DTC_INVALID_DATA_BCS 0;
BA_ "GenSigSendType" SG_ 546 FLR_DTC_INVALID_DATA_BCS 1;
BA_ "GenSigStartValue" SG_ 546 FLR_DTC_INVALID_DATA_BCS 0;
BA_ "GenSigTimeoutValue" SG_ 546 FLR_DTC_INVALID_DATA_BCS 0;
BA_ "Remark" SG_ 546 FLR_DTC_INVALID_DATA_BCS "";
BA_ "EventCommandSignal" SG_ 546 FLR_DTC_INVALID_DATA_EPS 0;
BA_ "GatewayedSignals" SG_ 546 FLR_DTC_INVALID_DATA_EPS 0;
BA_ "GenSigInactiveValue" SG_ 546 FLR_DTC_INVALID_DATA_EPS 0;
BA_ "GenSigInvalidValue" SG_ 546 FLR_DTC_INVALID_DATA_EPS 0;
BA_ "GenSigSendType" SG_ 546 FLR_DTC_INVALID_DATA_EPS 1;
BA_ "GenSigStartValue" SG_ 546 FLR_DTC_INVALID_DATA_EPS 0;
BA_ "GenSigTimeoutValue" SG_ 546 FLR_DTC_INVALID_DATA_EPS 0;
BA_ "Remark" SG_ 546 FLR_DTC_INVALID_DATA_EPS "";
BA_ "EventCommandSignal" SG_ 546 FLR_DTC_INVALID_DATA_SOC 0;
BA_ "GatewayedSignals" SG_ 546 FLR_DTC_INVALID_DATA_SOC 0;
BA_ "GenSigInactiveValue" SG_ 546 FLR_DTC_INVALID_DATA_SOC 0;
BA_ "GenSigInvalidValue" SG_ 546 FLR_DTC_INVALID_DATA_SOC 0;
BA_ "GenSigSendType" SG_ 546 FLR_DTC_INVALID_DATA_SOC 1;
BA_ "GenSigStartValue" SG_ 546 FLR_DTC_INVALID_DATA_SOC 0;
BA_ "GenSigTimeoutValue" SG_ 546 FLR_DTC_INVALID_DATA_SOC 0;
BA_ "Remark" SG_ 546 FLR_DTC_INVALID_DATA_SOC "";
BA_ "EventCommandSignal" SG_ 546 FLR_DTC_LOST_COMM_BCS 0;
BA_ "GatewayedSignals" SG_ 546 FLR_DTC_LOST_COMM_BCS 0;
BA_ "GenSigInactiveValue" SG_ 546 FLR_DTC_LOST_COMM_BCS 0;
BA_ "GenSigInvalidValue" SG_ 546 FLR_DTC_LOST_COMM_BCS 0;
BA_ "GenSigSendType" SG_ 546 FLR_DTC_LOST_COMM_BCS 1;
BA_ "GenSigStartValue" SG_ 546 FLR_DTC_LOST_COMM_BCS 0;
BA_ "GenSigTimeoutValue" SG_ 546 FLR_DTC_LOST_COMM_BCS 0;
BA_ "Remark" SG_ 546 FLR_DTC_LOST_COMM_BCS "";
BA_ "EventCommandSignal" SG_ 546 FLR_DTC_LOST_COMM_EPS 0;
BA_ "GatewayedSignals" SG_ 546 FLR_DTC_LOST_COMM_EPS 0;
BA_ "GenSigInactiveValue" SG_ 546 FLR_DTC_LOST_COMM_EPS 0;
BA_ "GenSigInvalidValue" SG_ 546 FLR_DTC_LOST_COMM_EPS 0;
BA_ "GenSigSendType" SG_ 546 FLR_DTC_LOST_COMM_EPS 1;
BA_ "GenSigStartValue" SG_ 546 FLR_DTC_LOST_COMM_EPS 0;
BA_ "GenSigTimeoutValue" SG_ 546 FLR_DTC_LOST_COMM_EPS 0;
BA_ "Remark" SG_ 546 FLR_DTC_LOST_COMM_EPS "";
BA_ "EventCommandSignal" SG_ 546 FLR_DTC_LOST_COMM_SOC 0;
BA_ "GatewayedSignals" SG_ 546 FLR_DTC_LOST_COMM_SOC 0;
BA_ "GenSigInactiveValue" SG_ 546 FLR_DTC_LOST_COMM_SOC 0;
BA_ "GenSigInvalidValue" SG_ 546 FLR_DTC_LOST_COMM_SOC 0;
BA_ "GenSigSendType" SG_ 546 FLR_DTC_LOST_COMM_SOC 1;
BA_ "GenSigStartValue" SG_ 546 FLR_DTC_LOST_COMM_SOC 0;
BA_ "GenSigTimeoutValue" SG_ 546 FLR_DTC_LOST_COMM_SOC 0;
BA_ "Remark" SG_ 546 FLR_DTC_LOST_COMM_SOC "";
BA_ "EventCommandSignal" SG_ 546 FLR_DTC_PUBLIC_CAN_BUSOFF 0;
BA_ "GatewayedSignals" SG_ 546 FLR_DTC_PUBLIC_CAN_BUSOFF 0;
BA_ "GenSigInactiveValue" SG_ 546 FLR_DTC_PUBLIC_CAN_BUSOFF 0;
BA_ "GenSigInvalidValue" SG_ 546 FLR_DTC_PUBLIC_CAN_BUSOFF 0;
BA_ "GenSigSendType" SG_ 546 FLR_DTC_PUBLIC_CAN_BUSOFF 1;
BA_ "GenSigStartValue" SG_ 546 FLR_DTC_PUBLIC_CAN_BUSOFF 0;
BA_ "GenSigTimeoutValue" SG_ 546 FLR_DTC_PUBLIC_CAN_BUSOFF 0;
BA_ "Remark" SG_ 546 FLR_DTC_PUBLIC_CAN_BUSOFF "";
BA_ "EventCommandSignal" SG_ 546 FLR_DTC_RADAR_OVER_TEMPERATURE 0;
BA_ "GatewayedSignals" SG_ 546 FLR_DTC_RADAR_OVER_TEMPERATURE 0;
BA_ "GenSigInactiveValue" SG_ 546 FLR_DTC_RADAR_OVER_TEMPERATURE 0;
BA_ "GenSigInvalidValue" SG_ 546 FLR_DTC_RADAR_OVER_TEMPERATURE 0;
BA_ "GenSigSendType" SG_ 546 FLR_DTC_RADAR_OVER_TEMPERATURE 1;
BA_ "GenSigStartValue" SG_ 546 FLR_DTC_RADAR_OVER_TEMPERATURE 0;
BA_ "GenSigTimeoutValue" SG_ 546 FLR_DTC_RADAR_OVER_TEMPERATURE 0;
BA_ "Remark" SG_ 546 FLR_DTC_RADAR_OVER_TEMPERATURE "";
BA_ "EventCommandSignal" SG_ 546 FLR_DTC_RADAR_SIDE_MISMATCH 0;
BA_ "GatewayedSignals" SG_ 546 FLR_DTC_RADAR_SIDE_MISMATCH 0;
BA_ "GenSigInactiveValue" SG_ 546 FLR_DTC_RADAR_SIDE_MISMATCH 0;
BA_ "GenSigInvalidValue" SG_ 546 FLR_DTC_RADAR_SIDE_MISMATCH 0;
BA_ "GenSigSendType" SG_ 546 FLR_DTC_RADAR_SIDE_MISMATCH 1;
BA_ "GenSigStartValue" SG_ 546 FLR_DTC_RADAR_SIDE_MISMATCH 0;
BA_ "GenSigTimeoutValue" SG_ 546 FLR_DTC_RADAR_SIDE_MISMATCH 0;
BA_ "Remark" SG_ 546 FLR_DTC_RADAR_SIDE_MISMATCH "";
BA_ "EventCommandSignal" SG_ 546 FLR_DTC_SOC_Time_SYNC_FAIL 0;
BA_ "GatewayedSignals" SG_ 546 FLR_DTC_SOC_Time_SYNC_FAIL 0;
BA_ "GenSigInactiveValue" SG_ 546 FLR_DTC_SOC_Time_SYNC_FAIL 0;
BA_ "GenSigInvalidValue" SG_ 546 FLR_DTC_SOC_Time_SYNC_FAIL 0;
BA_ "GenSigSendType" SG_ 546 FLR_DTC_SOC_Time_SYNC_FAIL 1;
BA_ "GenSigStartValue" SG_ 546 FLR_DTC_SOC_Time_SYNC_FAIL 0;
BA_ "GenSigTimeoutValue" SG_ 546 FLR_DTC_SOC_Time_SYNC_FAIL 0;
BA_ "Remark" SG_ 546 FLR_DTC_SOC_Time_SYNC_FAIL "";
BA_ "EventCommandSignal" SG_ 546 FLR_DTC_VARIANT_SELECTION_NOT_DONE 0;
BA_ "GatewayedSignals" SG_ 546 FLR_DTC_VARIANT_SELECTION_NOT_DONE 0;
BA_ "GenSigInactiveValue" SG_ 546 FLR_DTC_VARIANT_SELECTION_NOT_DONE 0;
BA_ "GenSigInvalidValue" SG_ 546 FLR_DTC_VARIANT_SELECTION_NOT_DONE 0;
BA_ "GenSigSendType" SG_ 546 FLR_DTC_VARIANT_SELECTION_NOT_DONE 1;
BA_ "GenSigStartValue" SG_ 546 FLR_DTC_VARIANT_SELECTION_NOT_DONE 0;
BA_ "GenSigTimeoutValue" SG_ 546 FLR_DTC_VARIANT_SELECTION_NOT_DONE 0;
BA_ "Remark" SG_ 546 FLR_DTC_VARIANT_SELECTION_NOT_DONE "";
BA_ "EventCommandSignal" SG_ 546 FLR_DTC_VBAT_HIGH 0;
BA_ "GatewayedSignals" SG_ 546 FLR_DTC_VBAT_HIGH 0;
BA_ "GenSigInactiveValue" SG_ 546 FLR_DTC_VBAT_HIGH 0;
BA_ "GenSigInvalidValue" SG_ 546 FLR_DTC_VBAT_HIGH 0;
BA_ "GenSigSendType" SG_ 546 FLR_DTC_VBAT_HIGH 1;
BA_ "GenSigStartValue" SG_ 546 FLR_DTC_VBAT_HIGH 0;
BA_ "GenSigTimeoutValue" SG_ 546 FLR_DTC_VBAT_HIGH 0;
BA_ "Remark" SG_ 546 FLR_DTC_VBAT_HIGH "";
BA_ "EventCommandSignal" SG_ 546 FLR_DTC_VBAT_LOW 0;
BA_ "GatewayedSignals" SG_ 546 FLR_DTC_VBAT_LOW 0;
BA_ "GenSigInactiveValue" SG_ 546 FLR_DTC_VBAT_LOW 0;
BA_ "GenSigInvalidValue" SG_ 546 FLR_DTC_VBAT_LOW 0;
BA_ "GenSigSendType" SG_ 546 FLR_DTC_VBAT_LOW 1;
BA_ "GenSigStartValue" SG_ 546 FLR_DTC_VBAT_LOW 0;
BA_ "GenSigTimeoutValue" SG_ 546 FLR_DTC_VBAT_LOW 0;
BA_ "Remark" SG_ 546 FLR_DTC_VBAT_LOW "";
BA_ "EventCommandSignal" SG_ 546 FLR_EOL_CalibrationSts 0;
BA_ "GatewayedSignals" SG_ 546 FLR_EOL_CalibrationSts 0;
BA_ "GenSigInactiveValue" SG_ 546 FLR_EOL_CalibrationSts 0;
BA_ "GenSigInvalidValue" SG_ 546 FLR_EOL_CalibrationSts 0;
BA_ "GenSigSendType" SG_ 546 FLR_EOL_CalibrationSts 1;
BA_ "GenSigStartValue" SG_ 546 FLR_EOL_CalibrationSts 255;
BA_ "GenSigTimeoutValue" SG_ 546 FLR_EOL_CalibrationSts 0;
BA_ "Remark" SG_ 546 FLR_EOL_CalibrationSts "";
BA_ "EventCommandSignal" SG_ 546 FLR_Misalignment_FaultSts 0;
BA_ "GatewayedSignals" SG_ 546 FLR_Misalignment_FaultSts 0;
BA_ "GenSigInactiveValue" SG_ 546 FLR_Misalignment_FaultSts 0;
BA_ "GenSigInvalidValue" SG_ 546 FLR_Misalignment_FaultSts 0;
BA_ "GenSigSendType" SG_ 546 FLR_Misalignment_FaultSts 1;
BA_ "GenSigStartValue" SG_ 546 FLR_Misalignment_FaultSts 0;
BA_ "GenSigTimeoutValue" SG_ 546 FLR_Misalignment_FaultSts 0;
BA_ "Remark" SG_ 546 FLR_Misalignment_FaultSts "";
BA_ "EventCommandSignal" SG_ 546 FLR_ModulationSts 0;
BA_ "GatewayedSignals" SG_ 546 FLR_ModulationSts 0;
BA_ "GenSigInactiveValue" SG_ 546 FLR_ModulationSts 0;
BA_ "GenSigInvalidValue" SG_ 546 FLR_ModulationSts 0;
BA_ "GenSigSendType" SG_ 546 FLR_ModulationSts 1;
BA_ "GenSigStartValue" SG_ 546 FLR_ModulationSts 0;
BA_ "GenSigTimeoutValue" SG_ 546 FLR_ModulationSts 0;
BA_ "Remark" SG_ 546 FLR_ModulationSts "";
BA_ "EventCommandSignal" SG_ 546 FLR_RadarInfor_AliveCounter 0;
BA_ "GatewayedSignals" SG_ 546 FLR_RadarInfor_AliveCounter 0;
BA_ "GenSigInactiveValue" SG_ 546 FLR_RadarInfor_AliveCounter 0;
BA_ "GenSigInvalidValue" SG_ 546 FLR_RadarInfor_AliveCounter 0;
BA_ "GenSigSendType" SG_ 546 FLR_RadarInfor_AliveCounter 1;
BA_ "GenSigStartValue" SG_ 546 FLR_RadarInfor_AliveCounter 0;
BA_ "GenSigTimeoutValue" SG_ 546 FLR_RadarInfor_AliveCounter 0;
BA_ "Remark" SG_ 546 FLR_RadarInfor_AliveCounter "";
BA_ "EventCommandSignal" SG_ 546 FLR_RadarInfor_Checksum 0;
BA_ "GatewayedSignals" SG_ 546 FLR_RadarInfor_Checksum 0;
BA_ "GenSigInactiveValue" SG_ 546 FLR_RadarInfor_Checksum 0;
BA_ "GenSigInvalidValue" SG_ 546 FLR_RadarInfor_Checksum 0;
BA_ "GenSigSendType" SG_ 546 FLR_RadarInfor_Checksum 1;
BA_ "GenSigStartValue" SG_ 546 FLR_RadarInfor_Checksum 0;
BA_ "GenSigTimeoutValue" SG_ 546 FLR_RadarInfor_Checksum 0;
BA_ "Remark" SG_ 546 FLR_RadarInfor_Checksum "";
BA_ "EventCommandSignal" SG_ 546 FLR_Radar_FaultSts 0;
BA_ "GatewayedSignals" SG_ 546 FLR_Radar_FaultSts 0;
BA_ "GenSigInactiveValue" SG_ 546 FLR_Radar_FaultSts 0;
BA_ "GenSigInvalidValue" SG_ 546 FLR_Radar_FaultSts 0;
BA_ "GenSigSendType" SG_ 546 FLR_Radar_FaultSts 1;
BA_ "GenSigStartValue" SG_ 546 FLR_Radar_FaultSts 0;
BA_ "GenSigTimeoutValue" SG_ 546 FLR_Radar_FaultSts 0;
BA_ "Remark" SG_ 546 FLR_Radar_FaultSts "";
BA_ "EventCommandSignal" SG_ 546 FLR_SDA_CalibrationSts 0;
BA_ "GatewayedSignals" SG_ 546 FLR_SDA_CalibrationSts 0;
BA_ "GenSigInactiveValue" SG_ 546 FLR_SDA_CalibrationSts 0;
BA_ "GenSigInvalidValue" SG_ 546 FLR_SDA_CalibrationSts 0;
BA_ "GenSigSendType" SG_ 546 FLR_SDA_CalibrationSts 1;
BA_ "GenSigStartValue" SG_ 546 FLR_SDA_CalibrationSts 255;
BA_ "GenSigTimeoutValue" SG_ 546 FLR_SDA_CalibrationSts 0;
BA_ "Remark" SG_ 546 FLR_SDA_CalibrationSts "";
BA_ "EventCommandSignal" SG_ 546 FLR_SW_Baseline 0;
BA_ "GatewayedSignals" SG_ 546 FLR_SW_Baseline 0;
BA_ "GenSigInactiveValue" SG_ 546 FLR_SW_Baseline 0;
BA_ "GenSigInvalidValue" SG_ 546 FLR_SW_Baseline 0;
BA_ "GenSigSendType" SG_ 546 FLR_SW_Baseline 1;
BA_ "GenSigStartValue" SG_ 546 FLR_SW_Baseline 0;
BA_ "GenSigTimeoutValue" SG_ 546 FLR_SW_Baseline 0;
BA_ "Remark" SG_ 546 FLR_SW_Baseline "";
BA_ "EventCommandSignal" SG_ 546 FLR_SW_MajorVersion 0;
BA_ "GatewayedSignals" SG_ 546 FLR_SW_MajorVersion 0;
BA_ "GenSigInactiveValue" SG_ 546 FLR_SW_MajorVersion 0;
BA_ "GenSigInvalidValue" SG_ 546 FLR_SW_MajorVersion 0;
BA_ "GenSigSendType" SG_ 546 FLR_SW_MajorVersion 1;
BA_ "GenSigStartValue" SG_ 546 FLR_SW_MajorVersion 0;
BA_ "GenSigTimeoutValue" SG_ 546 FLR_SW_MajorVersion 0;
BA_ "Remark" SG_ 546 FLR_SW_MajorVersion "";
BA_ "EventCommandSignal" SG_ 546 FLR_SW_MinorVersion 0;
BA_ "GatewayedSignals" SG_ 546 FLR_SW_MinorVersion 0;
BA_ "GenSigInactiveValue" SG_ 546 FLR_SW_MinorVersion 0;
BA_ "GenSigInvalidValue" SG_ 546 FLR_SW_MinorVersion 0;
BA_ "GenSigSendType" SG_ 546 FLR_SW_MinorVersion 1;
BA_ "GenSigStartValue" SG_ 546 FLR_SW_MinorVersion 0;
BA_ "GenSigTimeoutValue" SG_ 546 FLR_SW_MinorVersion 0;
BA_ "Remark" SG_ 546 FLR_SW_MinorVersion "";
BA_ "EventCommandSignal" SG_ 546 FLR_SW_ReleaseType 0;
BA_ "GatewayedSignals" SG_ 546 FLR_SW_ReleaseType 0;
BA_ "GenSigInactiveValue" SG_ 546 FLR_SW_ReleaseType 0;
BA_ "GenSigInvalidValue" SG_ 546 FLR_SW_ReleaseType 0;
BA_ "GenSigSendType" SG_ 546 FLR_SW_ReleaseType 1;
BA_ "GenSigStartValue" SG_ 546 FLR_SW_ReleaseType 0;
BA_ "GenSigTimeoutValue" SG_ 546 FLR_SW_ReleaseType 0;
BA_ "Remark" SG_ 546 FLR_SW_ReleaseType "";
BA_ "EventCommandSignal" SG_ 546 Fault_MAL_HOR_ABS_EVENT 0;
BA_ "GatewayedSignals" SG_ 546 Fault_MAL_HOR_ABS_EVENT 0;
BA_ "GenSigInactiveValue" SG_ 546 Fault_MAL_HOR_ABS_EVENT 0;
BA_ "GenSigInvalidValue" SG_ 546 Fault_MAL_HOR_ABS_EVENT 0;
BA_ "GenSigSendType" SG_ 546 Fault_MAL_HOR_ABS_EVENT 1;
BA_ "GenSigStartValue" SG_ 546 Fault_MAL_HOR_ABS_EVENT 0;
BA_ "GenSigTimeoutValue" SG_ 546 Fault_MAL_HOR_ABS_EVENT 0;
BA_ "Remark" SG_ 546 Fault_MAL_HOR_ABS_EVENT "";
BA_ "EventCommandSignal" SG_ 546 Fault_MAL_HOR_REL_EVENT 0;
BA_ "GatewayedSignals" SG_ 546 Fault_MAL_HOR_REL_EVENT 0;
BA_ "GenSigInactiveValue" SG_ 546 Fault_MAL_HOR_REL_EVENT 0;
BA_ "GenSigInvalidValue" SG_ 546 Fault_MAL_HOR_REL_EVENT 0;
BA_ "GenSigSendType" SG_ 546 Fault_MAL_HOR_REL_EVENT 1;
BA_ "GenSigStartValue" SG_ 546 Fault_MAL_HOR_REL_EVENT 0;
BA_ "GenSigTimeoutValue" SG_ 546 Fault_MAL_HOR_REL_EVENT 0;
BA_ "Remark" SG_ 546 Fault_MAL_HOR_REL_EVENT "";
BA_ "EventCommandSignal" SG_ 546 Fault_MAL_VER_ABS_EVENT 0;
BA_ "GatewayedSignals" SG_ 546 Fault_MAL_VER_ABS_EVENT 0;
BA_ "GenSigInactiveValue" SG_ 546 Fault_MAL_VER_ABS_EVENT 0;
BA_ "GenSigInvalidValue" SG_ 546 Fault_MAL_VER_ABS_EVENT 0;
BA_ "GenSigSendType" SG_ 546 Fault_MAL_VER_ABS_EVENT 1;
BA_ "GenSigStartValue" SG_ 546 Fault_MAL_VER_ABS_EVENT 0;
BA_ "GenSigTimeoutValue" SG_ 546 Fault_MAL_VER_ABS_EVENT 0;
BA_ "Remark" SG_ 546 Fault_MAL_VER_ABS_EVENT "";
BA_ "EventCommandSignal" SG_ 546 Fault_MAL_VER_REL_EVENT 0;
BA_ "GatewayedSignals" SG_ 546 Fault_MAL_VER_REL_EVENT 0;
BA_ "GenSigInactiveValue" SG_ 546 Fault_MAL_VER_REL_EVENT 0;
BA_ "GenSigInvalidValue" SG_ 546 Fault_MAL_VER_REL_EVENT 0;
BA_ "GenSigSendType" SG_ 546 Fault_MAL_VER_REL_EVENT 1;
BA_ "GenSigStartValue" SG_ 546 Fault_MAL_VER_REL_EVENT 0;
BA_ "GenSigTimeoutValue" SG_ 546 Fault_MAL_VER_REL_EVENT 0;
BA_ "Remark" SG_ 546 Fault_MAL_VER_REL_EVENT "";
BA_ "EventCommandSignal" SG_ 546 FilteredPhiSpread 0;
BA_ "GatewayedSignals" SG_ 546 FilteredPhiSpread 0;
BA_ "GenSigInactiveValue" SG_ 546 FilteredPhiSpread 0;
BA_ "GenSigInvalidValue" SG_ 546 FilteredPhiSpread 0;
BA_ "GenSigSendType" SG_ 546 FilteredPhiSpread 1;
BA_ "GenSigStartValue" SG_ 546 FilteredPhiSpread 0;
BA_ "GenSigTimeoutValue" SG_ 546 FilteredPhiSpread 0;
BA_ "Remark" SG_ 546 FilteredPhiSpread "";
BA_ "EventCommandSignal" SG_ 546 azOutOfProfileCause 0;
BA_ "GatewayedSignals" SG_ 546 azOutOfProfileCause 0;
BA_ "GenSigInactiveValue" SG_ 546 azOutOfProfileCause 0;
BA_ "GenSigInvalidValue" SG_ 546 azOutOfProfileCause 0;
BA_ "GenSigSendType" SG_ 546 azOutOfProfileCause 1;
BA_ "GenSigStartValue" SG_ 546 azOutOfProfileCause 0;
BA_ "GenSigTimeoutValue" SG_ 546 azOutOfProfileCause 0;
BA_ "Remark" SG_ 546 azOutOfProfileCause "";
BA_ "EventCommandSignal" SG_ 546 azOutOfSpecCause 0;
BA_ "GatewayedSignals" SG_ 546 azOutOfSpecCause 0;
BA_ "GenSigInactiveValue" SG_ 546 azOutOfSpecCause 0;
BA_ "GenSigInvalidValue" SG_ 546 azOutOfSpecCause 0;
BA_ "GenSigSendType" SG_ 546 azOutOfSpecCause 1;
BA_ "GenSigStartValue" SG_ 546 azOutOfSpecCause 0;
BA_ "GenSigTimeoutValue" SG_ 546 azOutOfSpecCause 0;
BA_ "Remark" SG_ 546 azOutOfSpecCause "";
BA_ "EventCommandSignal" SG_ 546 elOutOfProfileCause 0;
BA_ "GatewayedSignals" SG_ 546 elOutOfProfileCause 0;
BA_ "GenSigInactiveValue" SG_ 546 elOutOfProfileCause 0;
BA_ "GenSigInvalidValue" SG_ 546 elOutOfProfileCause 0;
BA_ "GenSigSendType" SG_ 546 elOutOfProfileCause 1;
BA_ "GenSigStartValue" SG_ 546 elOutOfProfileCause 0;
BA_ "GenSigTimeoutValue" SG_ 546 elOutOfProfileCause 0;
BA_ "Remark" SG_ 546 elOutOfProfileCause "";
BA_ "EventCommandSignal" SG_ 546 elOutOfSpecCause 0;
BA_ "GatewayedSignals" SG_ 546 elOutOfSpecCause 0;
BA_ "GenSigInactiveValue" SG_ 546 elOutOfSpecCause 0;
BA_ "GenSigInvalidValue" SG_ 546 elOutOfSpecCause 0;
BA_ "GenSigSendType" SG_ 546 elOutOfSpecCause 1;
BA_ "GenSigStartValue" SG_ 546 elOutOfSpecCause 0;
BA_ "GenSigTimeoutValue" SG_ 546 elOutOfSpecCause 0;
BA_ "Remark" SG_ 546 elOutOfSpecCause "";
BA_ "EventCommandSignal" SG_ 546 highSpreadIndicator_az 0;
BA_ "GatewayedSignals" SG_ 546 highSpreadIndicator_az 0;
BA_ "GenSigInactiveValue" SG_ 546 highSpreadIndicator_az 0;
BA_ "GenSigInvalidValue" SG_ 546 highSpreadIndicator_az 0;
BA_ "GenSigSendType" SG_ 546 highSpreadIndicator_az 1;
BA_ "GenSigStartValue" SG_ 546 highSpreadIndicator_az 0;
BA_ "GenSigTimeoutValue" SG_ 546 highSpreadIndicator_az 0;
BA_ "Remark" SG_ 546 highSpreadIndicator_az "";
BA_ "EventCommandSignal" SG_ 546 highSpreadIndicator_el 0;
BA_ "GatewayedSignals" SG_ 546 highSpreadIndicator_el 0;
BA_ "GenSigInactiveValue" SG_ 546 highSpreadIndicator_el 0;
BA_ "GenSigInvalidValue" SG_ 546 highSpreadIndicator_el 0;
BA_ "GenSigSendType" SG_ 546 highSpreadIndicator_el 1;
BA_ "GenSigStartValue" SG_ 546 highSpreadIndicator_el 0;
BA_ "GenSigTimeoutValue" SG_ 546 highSpreadIndicator_el 0;
BA_ "Remark" SG_ 546 highSpreadIndicator_el "";
BA_ "EventCommandSignal" SG_ 546 malStablePosAz 0;
BA_ "GatewayedSignals" SG_ 546 malStablePosAz 0;
BA_ "GenSigInactiveValue" SG_ 546 malStablePosAz 0;
BA_ "GenSigInvalidValue" SG_ 546 malStablePosAz 0;
BA_ "GenSigSendType" SG_ 546 malStablePosAz 1;
BA_ "GenSigStartValue" SG_ 546 malStablePosAz 0;
BA_ "GenSigTimeoutValue" SG_ 546 malStablePosAz 0;
BA_ "Remark" SG_ 546 malStablePosAz "";
BA_ "EventCommandSignal" SG_ 546 malStablePosEl 0;
BA_ "GatewayedSignals" SG_ 546 malStablePosEl 0;
BA_ "GenSigInactiveValue" SG_ 546 malStablePosEl 0;
BA_ "GenSigInvalidValue" SG_ 546 malStablePosEl 0;
BA_ "GenSigSendType" SG_ 546 malStablePosEl 1;
BA_ "GenSigStartValue" SG_ 546 malStablePosEl 0;
BA_ "GenSigTimeoutValue" SG_ 546 malStablePosEl 0;
BA_ "Remark" SG_ 546 malStablePosEl "";
BA_ "EventCommandSignal" SG_ 546 mountAngleCurrent_az 0;
BA_ "GatewayedSignals" SG_ 546 mountAngleCurrent_az 0;
BA_ "GenSigInactiveValue" SG_ 546 mountAngleCurrent_az 0;
BA_ "GenSigInvalidValue" SG_ 546 mountAngleCurrent_az 0;
BA_ "GenSigSendType" SG_ 546 mountAngleCurrent_az 1;
BA_ "GenSigStartValue" SG_ 546 mountAngleCurrent_az 0;
BA_ "GenSigTimeoutValue" SG_ 546 mountAngleCurrent_az 0;
BA_ "Remark" SG_ 546 mountAngleCurrent_az "";
BA_ "EventCommandSignal" SG_ 546 mountAngleCurrent_el 0;
BA_ "GatewayedSignals" SG_ 546 mountAngleCurrent_el 0;
BA_ "GenSigInactiveValue" SG_ 546 mountAngleCurrent_el 0;
BA_ "GenSigInvalidValue" SG_ 546 mountAngleCurrent_el 0;
BA_ "GenSigSendType" SG_ 546 mountAngleCurrent_el 1;
BA_ "GenSigStartValue" SG_ 546 mountAngleCurrent_el 0;
BA_ "GenSigTimeoutValue" SG_ 546 mountAngleCurrent_el 0;
BA_ "Remark" SG_ 546 mountAngleCurrent_el "";
BA_ "EventCommandSignal" SG_ 546 mountAngleIndicator_az 0;
BA_ "GatewayedSignals" SG_ 546 mountAngleIndicator_az 0;
BA_ "GenSigInactiveValue" SG_ 546 mountAngleIndicator_az 0;
BA_ "GenSigInvalidValue" SG_ 546 mountAngleIndicator_az 0;
BA_ "GenSigSendType" SG_ 546 mountAngleIndicator_az 1;
BA_ "GenSigStartValue" SG_ 546 mountAngleIndicator_az 0;
BA_ "GenSigTimeoutValue" SG_ 546 mountAngleIndicator_az 0;
BA_ "Remark" SG_ 546 mountAngleIndicator_az "";
BA_ "EventCommandSignal" SG_ 546 mountAngleIndicator_el 0;
BA_ "GatewayedSignals" SG_ 546 mountAngleIndicator_el 0;
BA_ "GenSigInactiveValue" SG_ 546 mountAngleIndicator_el 0;
BA_ "GenSigInvalidValue" SG_ 546 mountAngleIndicator_el 0;
BA_ "GenSigSendType" SG_ 546 mountAngleIndicator_el 1;
BA_ "GenSigStartValue" SG_ 546 mountAngleIndicator_el 0;
BA_ "GenSigTimeoutValue" SG_ 546 mountAngleIndicator_el 0;
BA_ "Remark" SG_ 546 mountAngleIndicator_el "";
BA_ "EventCommandSignal" SG_ 616 Time_Day 0;
BA_ "GatewayedSignals" SG_ 616 Time_Day 0;
BA_ "GenSigInactiveValue" SG_ 616 Time_Day 0;
BA_ "GenSigInvalidValue" SG_ 616 Time_Day 0;
BA_ "GenSigSendType" SG_ 616 Time_Day 1;
BA_ "GenSigStartValue" SG_ 616 Time_Day 1;
BA_ "GenSigTimeoutValue" SG_ 616 Time_Day 0;
BA_ "Remark" SG_ 616 Time_Day "";
BA_ "EventCommandSignal" SG_ 616 Time_Hour 0;
BA_ "GatewayedSignals" SG_ 616 Time_Hour 0;
BA_ "GenSigInactiveValue" SG_ 616 Time_Hour 0;
BA_ "GenSigInvalidValue" SG_ 616 Time_Hour 0;
BA_ "GenSigSendType" SG_ 616 Time_Hour 1;
BA_ "GenSigStartValue" SG_ 616 Time_Hour 1;
BA_ "GenSigTimeoutValue" SG_ 616 Time_Hour 0;
BA_ "Remark" SG_ 616 Time_Hour "";
BA_ "EventCommandSignal" SG_ 616 Time_Min 0;
BA_ "GatewayedSignals" SG_ 616 Time_Min 0;
BA_ "GenSigInactiveValue" SG_ 616 Time_Min 0;
BA_ "GenSigInvalidValue" SG_ 616 Time_Min 0;
BA_ "GenSigSendType" SG_ 616 Time_Min 1;
BA_ "GenSigStartValue" SG_ 616 Time_Min 1;
BA_ "GenSigTimeoutValue" SG_ 616 Time_Min 0;
BA_ "Remark" SG_ 616 Time_Min "";
BA_ "EventCommandSignal" SG_ 616 Time_Month 0;
BA_ "GatewayedSignals" SG_ 616 Time_Month 0;
BA_ "GenSigInactiveValue" SG_ 616 Time_Month 0;
BA_ "GenSigInvalidValue" SG_ 616 Time_Month 0;
BA_ "GenSigSendType" SG_ 616 Time_Month 1;
BA_ "GenSigStartValue" SG_ 616 Time_Month 0;
BA_ "GenSigTimeoutValue" SG_ 616 Time_Month 0;
BA_ "Remark" SG_ 616 Time_Month "";
BA_ "EventCommandSignal" SG_ 616 Time_Sec 0;
BA_ "GatewayedSignals" SG_ 616 Time_Sec 0;
BA_ "GenSigInactiveValue" SG_ 616 Time_Sec 0;
BA_ "GenSigInvalidValue" SG_ 616 Time_Sec 0;
BA_ "GenSigSendType" SG_ 616 Time_Sec 1;
BA_ "GenSigStartValue" SG_ 616 Time_Sec 1;
BA_ "GenSigTimeoutValue" SG_ 616 Time_Sec 0;
BA_ "Remark" SG_ 616 Time_Sec "";
BA_ "EventCommandSignal" SG_ 616 Time_Year 0;
BA_ "GatewayedSignals" SG_ 616 Time_Year 0;
BA_ "GenSigInactiveValue" SG_ 616 Time_Year 0;
BA_ "GenSigInvalidValue" SG_ 616 Time_Year 0;
BA_ "GenSigSendType" SG_ 616 Time_Year 1;
BA_ "GenSigStartValue" SG_ 616 Time_Year 0;
BA_ "GenSigTimeoutValue" SG_ 616 Time_Year 0;
BA_ "Remark" SG_ 616 Time_Year "";
BA_ "EventCommandSignal" SG_ 616 UMM_UsageModeSt 0;
BA_ "GatewayedSignals" SG_ 616 UMM_UsageModeSt 0;
BA_ "GenSigInactiveValue" SG_ 616 UMM_UsageModeSt 0;
BA_ "GenSigInvalidValue" SG_ 616 UMM_UsageModeSt 0;
BA_ "GenSigSendType" SG_ 616 UMM_UsageModeSt 1;
BA_ "GenSigStartValue" SG_ 616 UMM_UsageModeSt 7;
BA_ "GenSigTimeoutValue" SG_ 616 UMM_UsageModeSt 0;
BA_ "Remark" SG_ 616 UMM_UsageModeSt "";
BA_ "EventCommandSignal" SG_ 616 VMM_OTAModeSt 0;
BA_ "GatewayedSignals" SG_ 616 VMM_OTAModeSt 0;
BA_ "GenSigInactiveValue" SG_ 616 VMM_OTAModeSt 0;
BA_ "GenSigInvalidValue" SG_ 616 VMM_OTAModeSt 2;
BA_ "GenSigSendType" SG_ 616 VMM_OTAModeSt 1;
BA_ "GenSigStartValue" SG_ 616 VMM_OTAModeSt 2;
BA_ "GenSigTimeoutValue" SG_ 616 VMM_OTAModeSt 2;
BA_ "Remark" SG_ 616 VMM_OTAModeSt "";
BA_ "EventCommandSignal" SG_ 768 SYNC_FC_CRC 0;
BA_ "GatewayedSignals" SG_ 768 SYNC_FC_CRC 0;
BA_ "GenSigInactiveValue" SG_ 768 SYNC_FC_CRC 0;
BA_ "GenSigInvalidValue" SG_ 768 SYNC_FC_CRC 0;
BA_ "GenSigSendType" SG_ 768 SYNC_FC_CRC 1;
BA_ "GenSigStartValue" SG_ 768 SYNC_FC_CRC 0;
BA_ "GenSigTimeoutValue" SG_ 768 SYNC_FC_CRC 0;
BA_ "Remark" SG_ 768 SYNC_FC_CRC "";
BA_ "EventCommandSignal" SG_ 768 SYNC_FC_OVS 0;
BA_ "GatewayedSignals" SG_ 768 SYNC_FC_OVS 0;
BA_ "GenSigInactiveValue" SG_ 768 SYNC_FC_OVS 0;
BA_ "GenSigInvalidValue" SG_ 768 SYNC_FC_OVS 0;
BA_ "GenSigSendType" SG_ 768 SYNC_FC_OVS 1;
BA_ "GenSigStartValue" SG_ 768 SYNC_FC_OVS 0;
BA_ "GenSigTimeoutValue" SG_ 768 SYNC_FC_OVS 0;
BA_ "Remark" SG_ 768 SYNC_FC_OVS "";
BA_ "EventCommandSignal" SG_ 768 SYNC_FC_Reserved 0;
BA_ "GatewayedSignals" SG_ 768 SYNC_FC_Reserved 0;
BA_ "GenSigInactiveValue" SG_ 768 SYNC_FC_Reserved 0;
BA_ "GenSigInvalidValue" SG_ 768 SYNC_FC_Reserved 0;
BA_ "GenSigSendType" SG_ 768 SYNC_FC_Reserved 1;
BA_ "GenSigStartValue" SG_ 768 SYNC_FC_Reserved 0;
BA_ "GenSigTimeoutValue" SG_ 768 SYNC_FC_Reserved 0;
BA_ "Remark" SG_ 768 SYNC_FC_Reserved "";
BA_ "EventCommandSignal" SG_ 768 SYNC_FC_SGW 0;
BA_ "GatewayedSignals" SG_ 768 SYNC_FC_SGW 0;
BA_ "GenSigInactiveValue" SG_ 768 SYNC_FC_SGW 0;
BA_ "GenSigInvalidValue" SG_ 768 SYNC_FC_SGW 0;
BA_ "GenSigSendType" SG_ 768 SYNC_FC_SGW 1;
BA_ "GenSigStartValue" SG_ 768 SYNC_FC_SGW 0;
BA_ "GenSigTimeoutValue" SG_ 768 SYNC_FC_SGW 0;
BA_ "Remark" SG_ 768 SYNC_FC_SGW "";
BA_ "EventCommandSignal" SG_ 768 SYNC_FC_Sequencecnt 0;
BA_ "GatewayedSignals" SG_ 768 SYNC_FC_Sequencecnt 0;
BA_ "GenSigInactiveValue" SG_ 768 SYNC_FC_Sequencecnt 0;
BA_ "GenSigInvalidValue" SG_ 768 SYNC_FC_Sequencecnt 0;
BA_ "GenSigSendType" SG_ 768 SYNC_FC_Sequencecnt 1;
BA_ "GenSigStartValue" SG_ 768 SYNC_FC_Sequencecnt 0;
BA_ "GenSigTimeoutValue" SG_ 768 SYNC_FC_Sequencecnt 0;
BA_ "Remark" SG_ 768 SYNC_FC_Sequencecnt "";
BA_ "EventCommandSignal" SG_ 768 SYNC_FC_SyncTime 0;
BA_ "GatewayedSignals" SG_ 768 SYNC_FC_SyncTime 0;
BA_ "GenSigInactiveValue" SG_ 768 SYNC_FC_SyncTime 0;
BA_ "GenSigInvalidValue" SG_ 768 SYNC_FC_SyncTime 0;
BA_ "GenSigSendType" SG_ 768 SYNC_FC_SyncTime 1;
BA_ "GenSigStartValue" SG_ 768 SYNC_FC_SyncTime 0;
BA_ "GenSigTimeoutValue" SG_ 768 SYNC_FC_SyncTime 0;
BA_ "Remark" SG_ 768 SYNC_FC_SyncTime "";
BA_ "EventCommandSignal" SG_ 768 SYNC_FC_TimeDomain 0;
BA_ "GatewayedSignals" SG_ 768 SYNC_FC_TimeDomain 0;
BA_ "GenSigInactiveValue" SG_ 768 SYNC_FC_TimeDomain 0;
BA_ "GenSigInvalidValue" SG_ 768 SYNC_FC_TimeDomain 0;
BA_ "GenSigSendType" SG_ 768 SYNC_FC_TimeDomain 1;
BA_ "GenSigStartValue" SG_ 768 SYNC_FC_TimeDomain 0;
BA_ "GenSigTimeoutValue" SG_ 768 SYNC_FC_TimeDomain 0;
BA_ "Remark" SG_ 768 SYNC_FC_TimeDomain "";
BA_ "EventCommandSignal" SG_ 768 SYNC_FC_Type 0;
BA_ "GatewayedSignals" SG_ 768 SYNC_FC_Type 0;
BA_ "GenSigInactiveValue" SG_ 768 SYNC_FC_Type 0;
BA_ "GenSigInvalidValue" SG_ 768 SYNC_FC_Type 0;
BA_ "GenSigSendType" SG_ 768 SYNC_FC_Type 1;
BA_ "GenSigStartValue" SG_ 768 SYNC_FC_Type 0;
BA_ "GenSigTimeoutValue" SG_ 768 SYNC_FC_Type 0;
BA_ "Remark" SG_ 768 SYNC_FC_Type "";
BA_ "EventCommandSignal" SG_ 769 FRR_BlockCounter 0;
BA_ "GatewayedSignals" SG_ 769 FRR_BlockCounter 0;
BA_ "GenSigInactiveValue" SG_ 769 FRR_BlockCounter 0;
BA_ "GenSigInvalidValue" SG_ 769 FRR_BlockCounter 0;
BA_ "GenSigSendType" SG_ 769 FRR_BlockCounter 1;
BA_ "GenSigStartValue" SG_ 769 FRR_BlockCounter 0;
BA_ "GenSigTimeoutValue" SG_ 769 FRR_BlockCounter 0;
BA_ "Remark" SG_ 769 FRR_BlockCounter "";
BA_ "EventCommandSignal" SG_ 769 FRR_Moudulation_State 0;
BA_ "GatewayedSignals" SG_ 769 FRR_Moudulation_State 0;
BA_ "GenSigInactiveValue" SG_ 769 FRR_Moudulation_State 0;
BA_ "GenSigInvalidValue" SG_ 769 FRR_Moudulation_State 0;
BA_ "GenSigSendType" SG_ 769 FRR_Moudulation_State 1;
BA_ "GenSigStartValue" SG_ 769 FRR_Moudulation_State 0;
BA_ "GenSigTimeoutValue" SG_ 769 FRR_Moudulation_State 0;
BA_ "Remark" SG_ 769 FRR_Moudulation_State "";
BA_ "EventCommandSignal" SG_ 769 FRR_Msg_AliveCounter 0;
BA_ "GatewayedSignals" SG_ 769 FRR_Msg_AliveCounter 0;
BA_ "GenSigInactiveValue" SG_ 769 FRR_Msg_AliveCounter 0;
BA_ "GenSigInvalidValue" SG_ 769 FRR_Msg_AliveCounter 0;
BA_ "GenSigSendType" SG_ 769 FRR_Msg_AliveCounter 1;
BA_ "GenSigStartValue" SG_ 769 FRR_Msg_AliveCounter 0;
BA_ "GenSigTimeoutValue" SG_ 769 FRR_Msg_AliveCounter 0;
BA_ "Remark" SG_ 769 FRR_Msg_AliveCounter "";
BA_ "EventCommandSignal" SG_ 769 FRR_Msg_CheckSum 0;
BA_ "GatewayedSignals" SG_ 769 FRR_Msg_CheckSum 0;
BA_ "GenSigInactiveValue" SG_ 769 FRR_Msg_CheckSum 0;
BA_ "GenSigInvalidValue" SG_ 769 FRR_Msg_CheckSum 0;
BA_ "GenSigSendType" SG_ 769 FRR_Msg_CheckSum 1;
BA_ "GenSigStartValue" SG_ 769 FRR_Msg_CheckSum 0;
BA_ "GenSigTimeoutValue" SG_ 769 FRR_Msg_CheckSum 0;
BA_ "Remark" SG_ 769 FRR_Msg_CheckSum "";
BA_ "EventCommandSignal" SG_ 769 FRR_Num_Of_Objects 0;
BA_ "GatewayedSignals" SG_ 769 FRR_Num_Of_Objects 0;
BA_ "GenSigInactiveValue" SG_ 769 FRR_Num_Of_Objects 0;
BA_ "GenSigInvalidValue" SG_ 769 FRR_Num_Of_Objects 0;
BA_ "GenSigSendType" SG_ 769 FRR_Num_Of_Objects 1;
BA_ "GenSigStartValue" SG_ 769 FRR_Num_Of_Objects 0;
BA_ "GenSigTimeoutValue" SG_ 769 FRR_Num_Of_Objects 0;
BA_ "Remark" SG_ 769 FRR_Num_Of_Objects "";
BA_ "EventCommandSignal" SG_ 769 FRR_Object_Mea_timestamp_1 0;
BA_ "GatewayedSignals" SG_ 769 FRR_Object_Mea_timestamp_1 0;
BA_ "GenSigInactiveValue" SG_ 769 FRR_Object_Mea_timestamp_1 0;
BA_ "GenSigInvalidValue" SG_ 769 FRR_Object_Mea_timestamp_1 0;
BA_ "GenSigSendType" SG_ 769 FRR_Object_Mea_timestamp_1 1;
BA_ "GenSigStartValue" SG_ 769 FRR_Object_Mea_timestamp_1 0;
BA_ "GenSigTimeoutValue" SG_ 769 FRR_Object_Mea_timestamp_1 0;
BA_ "Remark" SG_ 769 FRR_Object_Mea_timestamp_1 "";
BA_ "EventCommandSignal" SG_ 769 FRR_Object_Mea_timestamp_2 0;
BA_ "GatewayedSignals" SG_ 769 FRR_Object_Mea_timestamp_2 0;
BA_ "GenSigInactiveValue" SG_ 769 FRR_Object_Mea_timestamp_2 0;
BA_ "GenSigInvalidValue" SG_ 769 FRR_Object_Mea_timestamp_2 0;
BA_ "GenSigSendType" SG_ 769 FRR_Object_Mea_timestamp_2 1;
BA_ "GenSigStartValue" SG_ 769 FRR_Object_Mea_timestamp_2 0;
BA_ "GenSigTimeoutValue" SG_ 769 FRR_Object_Mea_timestamp_2 0;
BA_ "Remark" SG_ 769 FRR_Object_Mea_timestamp_2 "";
BA_ "EventCommandSignal" SG_ 769 FRR_OperationMode 0;
BA_ "GatewayedSignals" SG_ 769 FRR_OperationMode 0;
BA_ "GenSigInactiveValue" SG_ 769 FRR_OperationMode 0;
BA_ "GenSigInvalidValue" SG_ 769 FRR_OperationMode 0;
BA_ "GenSigSendType" SG_ 769 FRR_OperationMode 1;
BA_ "GenSigStartValue" SG_ 769 FRR_OperationMode 0;
BA_ "GenSigTimeoutValue" SG_ 769 FRR_OperationMode 0;
BA_ "Remark" SG_ 769 FRR_OperationMode "";
BA_ "EventCommandSignal" SG_ 769 FRR_SDA_HorzDeviationAngle_Can03 0;
BA_ "GatewayedSignals" SG_ 769 FRR_SDA_HorzDeviationAngle_Can03 0;
BA_ "GenSigInactiveValue" SG_ 769 FRR_SDA_HorzDeviationAngle_Can03 0;
BA_ "GenSigInvalidValue" SG_ 769 FRR_SDA_HorzDeviationAngle_Can03 0;
BA_ "GenSigSendType" SG_ 769 FRR_SDA_HorzDeviationAngle_Can03 1;
BA_ "GenSigStartValue" SG_ 769 FRR_SDA_HorzDeviationAngle_Can03 0;
BA_ "GenSigTimeoutValue" SG_ 769 FRR_SDA_HorzDeviationAngle_Can03 0;
BA_ "Remark" SG_ 769 FRR_SDA_HorzDeviationAngle_Can03 "";
BA_ "EventCommandSignal" SG_ 769 FRR_SDA_VertDeviationAngle_Can03 0;
BA_ "GatewayedSignals" SG_ 769 FRR_SDA_VertDeviationAngle_Can03 0;
BA_ "GenSigInactiveValue" SG_ 769 FRR_SDA_VertDeviationAngle_Can03 0;
BA_ "GenSigInvalidValue" SG_ 769 FRR_SDA_VertDeviationAngle_Can03 0;
BA_ "GenSigSendType" SG_ 769 FRR_SDA_VertDeviationAngle_Can03 1;
BA_ "GenSigStartValue" SG_ 769 FRR_SDA_VertDeviationAngle_Can03 0;
BA_ "GenSigTimeoutValue" SG_ 769 FRR_SDA_VertDeviationAngle_Can03 0;
BA_ "Remark" SG_ 769 FRR_SDA_VertDeviationAngle_Can03 "";
BA_ "EventCommandSignal" SG_ 769 FRR_SGUFail 0;
BA_ "GatewayedSignals" SG_ 769 FRR_SGUFail 0;
BA_ "GenSigInactiveValue" SG_ 769 FRR_SGUFail 0;
BA_ "GenSigInvalidValue" SG_ 769 FRR_SGUFail 0;
BA_ "GenSigSendType" SG_ 769 FRR_SGUFail 1;
BA_ "GenSigStartValue" SG_ 769 FRR_SGUFail 0;
BA_ "GenSigTimeoutValue" SG_ 769 FRR_SGUFail 0;
BA_ "Remark" SG_ 769 FRR_SGUFail "";
BA_ "EventCommandSignal" SG_ 769 FRR_SensorType 0;
BA_ "GatewayedSignals" SG_ 769 FRR_SensorType 0;
BA_ "GenSigInactiveValue" SG_ 769 FRR_SensorType 0;
BA_ "GenSigInvalidValue" SG_ 769 FRR_SensorType 0;
BA_ "GenSigSendType" SG_ 769 FRR_SensorType 1;
BA_ "GenSigStartValue" SG_ 769 FRR_SensorType 0;
BA_ "GenSigTimeoutValue" SG_ 769 FRR_SensorType 0;
BA_ "Remark" SG_ 769 FRR_SensorType "";
BA_ "EventCommandSignal" SG_ 769 FRR_Signal_Operatation_Channel 0;
BA_ "GatewayedSignals" SG_ 769 FRR_Signal_Operatation_Channel 0;
BA_ "GenSigInactiveValue" SG_ 769 FRR_Signal_Operatation_Channel 0;
BA_ "GenSigInvalidValue" SG_ 769 FRR_Signal_Operatation_Channel 0;
BA_ "GenSigSendType" SG_ 769 FRR_Signal_Operatation_Channel 1;
BA_ "GenSigStartValue" SG_ 769 FRR_Signal_Operatation_Channel 0;
BA_ "GenSigTimeoutValue" SG_ 769 FRR_Signal_Operatation_Channel 0;
BA_ "Remark" SG_ 769 FRR_Signal_Operatation_Channel "";
BA_ "EventCommandSignal" SG_ 769 FRR_Signal_Operation_State 0;
BA_ "GatewayedSignals" SG_ 769 FRR_Signal_Operation_State 0;
BA_ "GenSigInactiveValue" SG_ 769 FRR_Signal_Operation_State 0;
BA_ "GenSigInvalidValue" SG_ 769 FRR_Signal_Operation_State 0;
BA_ "GenSigSendType" SG_ 769 FRR_Signal_Operation_State 1;
BA_ "GenSigStartValue" SG_ 769 FRR_Signal_Operation_State 0;
BA_ "GenSigTimeoutValue" SG_ 769 FRR_Signal_Operation_State 0;
BA_ "Remark" SG_ 769 FRR_Signal_Operation_State "";
BA_ "EventCommandSignal" SG_ 769 FRR_TimeSync_Operatation_Channel 0;
BA_ "GatewayedSignals" SG_ 769 FRR_TimeSync_Operatation_Channel 0;
BA_ "GenSigInactiveValue" SG_ 769 FRR_TimeSync_Operatation_Channel 0;
BA_ "GenSigInvalidValue" SG_ 769 FRR_TimeSync_Operatation_Channel 0;
BA_ "GenSigSendType" SG_ 769 FRR_TimeSync_Operatation_Channel 1;
BA_ "GenSigStartValue" SG_ 769 FRR_TimeSync_Operatation_Channel 0;
BA_ "GenSigTimeoutValue" SG_ 769 FRR_TimeSync_Operatation_Channel 0;
BA_ "Remark" SG_ 769 FRR_TimeSync_Operatation_Channel "";
BA_ "EventCommandSignal" SG_ 769 FRR_TimeSync_Operation_State 0;
BA_ "GatewayedSignals" SG_ 769 FRR_TimeSync_Operation_State 0;
BA_ "GenSigInactiveValue" SG_ 769 FRR_TimeSync_Operation_State 0;
BA_ "GenSigInvalidValue" SG_ 769 FRR_TimeSync_Operation_State 0;
BA_ "GenSigSendType" SG_ 769 FRR_TimeSync_Operation_State 1;
BA_ "GenSigStartValue" SG_ 769 FRR_TimeSync_Operation_State 0;
BA_ "GenSigTimeoutValue" SG_ 769 FRR_TimeSync_Operation_State 0;
BA_ "Remark" SG_ 769 FRR_TimeSync_Operation_State "";
BA_ "EventCommandSignal" SG_ 769 FRR_TimerStampStatus 0;
BA_ "GatewayedSignals" SG_ 769 FRR_TimerStampStatus 0;
BA_ "GenSigInactiveValue" SG_ 769 FRR_TimerStampStatus 0;
BA_ "GenSigInvalidValue" SG_ 769 FRR_TimerStampStatus 0;
BA_ "GenSigSendType" SG_ 769 FRR_TimerStampStatus 1;
BA_ "GenSigStartValue" SG_ 769 FRR_TimerStampStatus 0;
BA_ "GenSigTimeoutValue" SG_ 769 FRR_TimerStampStatus 0;
BA_ "Remark" SG_ 769 FRR_TimerStampStatus "";
BA_ "EventCommandSignal" SG_ 770 SGU1_BlockCounter 0;
BA_ "GatewayedSignals" SG_ 770 SGU1_BlockCounter 0;
BA_ "GenSigInactiveValue" SG_ 770 SGU1_BlockCounter 0;
BA_ "GenSigInvalidValue" SG_ 770 SGU1_BlockCounter 0;
BA_ "GenSigSendType" SG_ 770 SGU1_BlockCounter 1;
BA_ "GenSigStartValue" SG_ 770 SGU1_BlockCounter 0;
BA_ "GenSigTimeoutValue" SG_ 770 SGU1_BlockCounter 0;
BA_ "Remark" SG_ 770 SGU1_BlockCounter "";
BA_ "EventCommandSignal" SG_ 770 SGU1_LifeCycles_OBJ 0;
BA_ "GatewayedSignals" SG_ 770 SGU1_LifeCycles_OBJ 0;
BA_ "GenSigInactiveValue" SG_ 770 SGU1_LifeCycles_OBJ 0;
BA_ "GenSigInvalidValue" SG_ 770 SGU1_LifeCycles_OBJ 0;
BA_ "GenSigSendType" SG_ 770 SGU1_LifeCycles_OBJ 1;
BA_ "GenSigStartValue" SG_ 770 SGU1_LifeCycles_OBJ 0;
BA_ "GenSigTimeoutValue" SG_ 770 SGU1_LifeCycles_OBJ 0;
BA_ "Remark" SG_ 770 SGU1_LifeCycles_OBJ "";
BA_ "EventCommandSignal" SG_ 770 SGU1_Msg_AliveCounter 0;
BA_ "GatewayedSignals" SG_ 770 SGU1_Msg_AliveCounter 0;
BA_ "GenSigInactiveValue" SG_ 770 SGU1_Msg_AliveCounter 0;
BA_ "GenSigInvalidValue" SG_ 770 SGU1_Msg_AliveCounter 0;
BA_ "GenSigSendType" SG_ 770 SGU1_Msg_AliveCounter 1;
BA_ "GenSigStartValue" SG_ 770 SGU1_Msg_AliveCounter 0;
BA_ "GenSigTimeoutValue" SG_ 770 SGU1_Msg_AliveCounter 0;
BA_ "Remark" SG_ 770 SGU1_Msg_AliveCounter "";
BA_ "EventCommandSignal" SG_ 770 SGU1_Msg_CheckSum 0;
BA_ "GatewayedSignals" SG_ 770 SGU1_Msg_CheckSum 0;
BA_ "GenSigInactiveValue" SG_ 770 SGU1_Msg_CheckSum 0;
BA_ "GenSigInvalidValue" SG_ 770 SGU1_Msg_CheckSum 0;
BA_ "GenSigSendType" SG_ 770 SGU1_Msg_CheckSum 1;
BA_ "GenSigStartValue" SG_ 770 SGU1_Msg_CheckSum 0;
BA_ "GenSigTimeoutValue" SG_ 770 SGU1_Msg_CheckSum 0;
BA_ "Remark" SG_ 770 SGU1_Msg_CheckSum "";
BA_ "EventCommandSignal" SG_ 770 SGU1_ObjRCS_01 0;
BA_ "GatewayedSignals" SG_ 770 SGU1_ObjRCS_01 0;
BA_ "GenSigInactiveValue" SG_ 770 SGU1_ObjRCS_01 0;
BA_ "GenSigInvalidValue" SG_ 770 SGU1_ObjRCS_01 0;
BA_ "GenSigSendType" SG_ 770 SGU1_ObjRCS_01 1;
BA_ "GenSigStartValue" SG_ 770 SGU1_ObjRCS_01 0;
BA_ "GenSigTimeoutValue" SG_ 770 SGU1_ObjRCS_01 0;
BA_ "Remark" SG_ 770 SGU1_ObjRCS_01 "";
BA_ "EventCommandSignal" SG_ 770 SGU1_Obj_DistLat_rms 0;
BA_ "GatewayedSignals" SG_ 770 SGU1_Obj_DistLat_rms 0;
BA_ "GenSigInactiveValue" SG_ 770 SGU1_Obj_DistLat_rms 0;
BA_ "GenSigInvalidValue" SG_ 770 SGU1_Obj_DistLat_rms 0;
BA_ "GenSigSendType" SG_ 770 SGU1_Obj_DistLat_rms 1;
BA_ "GenSigStartValue" SG_ 770 SGU1_Obj_DistLat_rms 0;
BA_ "GenSigTimeoutValue" SG_ 770 SGU1_Obj_DistLat_rms 0;
BA_ "Remark" SG_ 770 SGU1_Obj_DistLat_rms "";
BA_ "EventCommandSignal" SG_ 770 SGU1_Obj_VrelLong_rms 0;
BA_ "GatewayedSignals" SG_ 770 SGU1_Obj_VrelLong_rms 0;
BA_ "GenSigInactiveValue" SG_ 770 SGU1_Obj_VrelLong_rms 0;
BA_ "GenSigInvalidValue" SG_ 770 SGU1_Obj_VrelLong_rms 0;
BA_ "GenSigSendType" SG_ 770 SGU1_Obj_VrelLong_rms 1;
BA_ "GenSigStartValue" SG_ 770 SGU1_Obj_VrelLong_rms 0;
BA_ "GenSigTimeoutValue" SG_ 770 SGU1_Obj_VrelLong_rms 0;
BA_ "Remark" SG_ 770 SGU1_Obj_VrelLong_rms "";
BA_ "EventCommandSignal" SG_ 770 SGU1_Obj_Vrelat_rms 0;
BA_ "GatewayedSignals" SG_ 770 SGU1_Obj_Vrelat_rms 0;
BA_ "GenSigInactiveValue" SG_ 770 SGU1_Obj_Vrelat_rms 0;
BA_ "GenSigInvalidValue" SG_ 770 SGU1_Obj_Vrelat_rms 0;
BA_ "GenSigSendType" SG_ 770 SGU1_Obj_Vrelat_rms 1;
BA_ "GenSigStartValue" SG_ 770 SGU1_Obj_Vrelat_rms 0;
BA_ "GenSigTimeoutValue" SG_ 770 SGU1_Obj_Vrelat_rms 0;
BA_ "Remark" SG_ 770 SGU1_Obj_Vrelat_rms "";
BA_ "EventCommandSignal" SG_ 770 SGU1_Object_DetStatus 0;
BA_ "GatewayedSignals" SG_ 770 SGU1_Object_DetStatus 0;
BA_ "GenSigInactiveValue" SG_ 770 SGU1_Object_DetStatus 0;
BA_ "GenSigInvalidValue" SG_ 770 SGU1_Object_DetStatus 0;
BA_ "GenSigSendType" SG_ 770 SGU1_Object_DetStatus 1;
BA_ "GenSigStartValue" SG_ 770 SGU1_Object_DetStatus 0;
BA_ "GenSigTimeoutValue" SG_ 770 SGU1_Object_DetStatus 0;
BA_ "Remark" SG_ 770 SGU1_Object_DetStatus "";
BA_ "EventCommandSignal" SG_ 770 SGU1_Object_DistLong_rms 0;
BA_ "GatewayedSignals" SG_ 770 SGU1_Object_DistLong_rms 0;
BA_ "GenSigInactiveValue" SG_ 770 SGU1_Object_DistLong_rms 0;
BA_ "GenSigInvalidValue" SG_ 770 SGU1_Object_DistLong_rms 0;
BA_ "GenSigSendType" SG_ 770 SGU1_Object_DistLong_rms 1;
BA_ "GenSigStartValue" SG_ 770 SGU1_Object_DistLong_rms 0;
BA_ "GenSigTimeoutValue" SG_ 770 SGU1_Object_DistLong_rms 0;
BA_ "Remark" SG_ 770 SGU1_Object_DistLong_rms "";
BA_ "EventCommandSignal" SG_ 770 SGU1_Object_ID 0;
BA_ "GatewayedSignals" SG_ 770 SGU1_Object_ID 0;
BA_ "GenSigInactiveValue" SG_ 770 SGU1_Object_ID 0;
BA_ "GenSigInvalidValue" SG_ 770 SGU1_Object_ID 0;
BA_ "GenSigSendType" SG_ 770 SGU1_Object_ID 1;
BA_ "GenSigStartValue" SG_ 770 SGU1_Object_ID 0;
BA_ "GenSigTimeoutValue" SG_ 770 SGU1_Object_ID 0;
BA_ "Remark" SG_ 770 SGU1_Object_ID "";
BA_ "EventCommandSignal" SG_ 770 SGU1_Object_Motion_Pattern 0;
BA_ "GatewayedSignals" SG_ 770 SGU1_Object_Motion_Pattern 0;
BA_ "GenSigInactiveValue" SG_ 770 SGU1_Object_Motion_Pattern 0;
BA_ "GenSigInvalidValue" SG_ 770 SGU1_Object_Motion_Pattern 0;
BA_ "GenSigSendType" SG_ 770 SGU1_Object_Motion_Pattern 1;
BA_ "GenSigStartValue" SG_ 770 SGU1_Object_Motion_Pattern 0;
BA_ "GenSigTimeoutValue" SG_ 770 SGU1_Object_Motion_Pattern 0;
BA_ "Remark" SG_ 770 SGU1_Object_Motion_Pattern "";
BA_ "EventCommandSignal" SG_ 770 SGU1_Object_Type 0;
BA_ "GatewayedSignals" SG_ 770 SGU1_Object_Type 0;
BA_ "GenSigInactiveValue" SG_ 770 SGU1_Object_Type 0;
BA_ "GenSigInvalidValue" SG_ 770 SGU1_Object_Type 0;
BA_ "GenSigSendType" SG_ 770 SGU1_Object_Type 1;
BA_ "GenSigStartValue" SG_ 770 SGU1_Object_Type 0;
BA_ "GenSigTimeoutValue" SG_ 770 SGU1_Object_Type 0;
BA_ "Remark" SG_ 770 SGU1_Object_Type "";
BA_ "EventCommandSignal" SG_ 770 SGU1_Object_ax 0;
BA_ "GatewayedSignals" SG_ 770 SGU1_Object_ax 0;
BA_ "GenSigInactiveValue" SG_ 770 SGU1_Object_ax 0;
BA_ "GenSigInvalidValue" SG_ 770 SGU1_Object_ax 0;
BA_ "GenSigSendType" SG_ 770 SGU1_Object_ax 1;
BA_ "GenSigStartValue" SG_ 770 SGU1_Object_ax 0;
BA_ "GenSigTimeoutValue" SG_ 770 SGU1_Object_ax 0;
BA_ "Remark" SG_ 770 SGU1_Object_ax "";
BA_ "EventCommandSignal" SG_ 770 SGU1_Object_ay 0;
BA_ "GatewayedSignals" SG_ 770 SGU1_Object_ay 0;
BA_ "GenSigInactiveValue" SG_ 770 SGU1_Object_ay 0;
BA_ "GenSigInvalidValue" SG_ 770 SGU1_Object_ay 0;
BA_ "GenSigSendType" SG_ 770 SGU1_Object_ay 1;
BA_ "GenSigStartValue" SG_ 770 SGU1_Object_ay 0;
BA_ "GenSigTimeoutValue" SG_ 770 SGU1_Object_ay 0;
BA_ "Remark" SG_ 770 SGU1_Object_ay "";
BA_ "EventCommandSignal" SG_ 770 SGU1_Object_dx 0;
BA_ "GatewayedSignals" SG_ 770 SGU1_Object_dx 0;
BA_ "GenSigInactiveValue" SG_ 770 SGU1_Object_dx 0;
BA_ "GenSigInvalidValue" SG_ 770 SGU1_Object_dx 0;
BA_ "GenSigSendType" SG_ 770 SGU1_Object_dx 1;
BA_ "GenSigStartValue" SG_ 770 SGU1_Object_dx 0;
BA_ "GenSigTimeoutValue" SG_ 770 SGU1_Object_dx 0;
BA_ "Remark" SG_ 770 SGU1_Object_dx "";
BA_ "EventCommandSignal" SG_ 770 SGU1_Object_dx_Rear 0;
BA_ "GatewayedSignals" SG_ 770 SGU1_Object_dx_Rear 0;
BA_ "GenSigInactiveValue" SG_ 770 SGU1_Object_dx_Rear 0;
BA_ "GenSigInvalidValue" SG_ 770 SGU1_Object_dx_Rear 0;
BA_ "GenSigSendType" SG_ 770 SGU1_Object_dx_Rear 1;
BA_ "GenSigStartValue" SG_ 770 SGU1_Object_dx_Rear 0;
BA_ "GenSigTimeoutValue" SG_ 770 SGU1_Object_dx_Rear 0;
BA_ "Remark" SG_ 770 SGU1_Object_dx_Rear "";
BA_ "EventCommandSignal" SG_ 770 SGU1_Object_dy 0;
BA_ "GatewayedSignals" SG_ 770 SGU1_Object_dy 0;
BA_ "GenSigInactiveValue" SG_ 770 SGU1_Object_dy 0;
BA_ "GenSigInvalidValue" SG_ 770 SGU1_Object_dy 0;
BA_ "GenSigSendType" SG_ 770 SGU1_Object_dy 1;
BA_ "GenSigStartValue" SG_ 770 SGU1_Object_dy 0;
BA_ "GenSigTimeoutValue" SG_ 770 SGU1_Object_dy 0;
BA_ "Remark" SG_ 770 SGU1_Object_dy "";
BA_ "EventCommandSignal" SG_ 770 SGU1_Object_dy_Rear 0;
BA_ "GatewayedSignals" SG_ 770 SGU1_Object_dy_Rear 0;
BA_ "GenSigInactiveValue" SG_ 770 SGU1_Object_dy_Rear 0;
BA_ "GenSigInvalidValue" SG_ 770 SGU1_Object_dy_Rear 0;
BA_ "GenSigSendType" SG_ 770 SGU1_Object_dy_Rear 1;
BA_ "GenSigStartValue" SG_ 770 SGU1_Object_dy_Rear 0;
BA_ "GenSigTimeoutValue" SG_ 770 SGU1_Object_dy_Rear 0;
BA_ "Remark" SG_ 770 SGU1_Object_dy_Rear "";
BA_ "EventCommandSignal" SG_ 770 SGU1_Object_vx 0;
BA_ "GatewayedSignals" SG_ 770 SGU1_Object_vx 0;
BA_ "GenSigInactiveValue" SG_ 770 SGU1_Object_vx 0;
BA_ "GenSigInvalidValue" SG_ 770 SGU1_Object_vx 0;
BA_ "GenSigSendType" SG_ 770 SGU1_Object_vx 1;
BA_ "GenSigStartValue" SG_ 770 SGU1_Object_vx 0;
BA_ "GenSigTimeoutValue" SG_ 770 SGU1_Object_vx 0;
BA_ "Remark" SG_ 770 SGU1_Object_vx "";
BA_ "EventCommandSignal" SG_ 770 SGU1_Object_vy 0;
BA_ "GatewayedSignals" SG_ 770 SGU1_Object_vy 0;
BA_ "GenSigInactiveValue" SG_ 770 SGU1_Object_vy 0;
BA_ "GenSigInvalidValue" SG_ 770 SGU1_Object_vy 0;
BA_ "GenSigSendType" SG_ 770 SGU1_Object_vy 1;
BA_ "GenSigStartValue" SG_ 770 SGU1_Object_vy 0;
BA_ "GenSigTimeoutValue" SG_ 770 SGU1_Object_vy 0;
BA_ "Remark" SG_ 770 SGU1_Object_vy "";
BA_ "EventCommandSignal" SG_ 770 SGU1_Object_wExist 0;
BA_ "GatewayedSignals" SG_ 770 SGU1_Object_wExist 0;
BA_ "GenSigInactiveValue" SG_ 770 SGU1_Object_wExist 0;
BA_ "GenSigInvalidValue" SG_ 770 SGU1_Object_wExist 0;
BA_ "GenSigSendType" SG_ 770 SGU1_Object_wExist 1;
BA_ "GenSigStartValue" SG_ 770 SGU1_Object_wExist 0;
BA_ "GenSigTimeoutValue" SG_ 770 SGU1_Object_wExist 0;
BA_ "Remark" SG_ 770 SGU1_Object_wExist "";
BA_ "EventCommandSignal" SG_ 770 SGU1_Object_wObstacle 0;
BA_ "GatewayedSignals" SG_ 770 SGU1_Object_wObstacle 0;
BA_ "GenSigInactiveValue" SG_ 770 SGU1_Object_wObstacle 0;
BA_ "GenSigInvalidValue" SG_ 770 SGU1_Object_wObstacle 0;
BA_ "GenSigSendType" SG_ 770 SGU1_Object_wObstacle 1;
BA_ "GenSigStartValue" SG_ 770 SGU1_Object_wObstacle 0;
BA_ "GenSigTimeoutValue" SG_ 770 SGU1_Object_wObstacle 0;
BA_ "Remark" SG_ 770 SGU1_Object_wObstacle "";
BA_ "EventCommandSignal" SG_ 771 SGU2_BlockCounter 0;
BA_ "GatewayedSignals" SG_ 771 SGU2_BlockCounter 0;
BA_ "GenSigInactiveValue" SG_ 771 SGU2_BlockCounter 0;
BA_ "GenSigInvalidValue" SG_ 771 SGU2_BlockCounter 0;
BA_ "GenSigSendType" SG_ 771 SGU2_BlockCounter 1;
BA_ "GenSigStartValue" SG_ 771 SGU2_BlockCounter 0;
BA_ "GenSigTimeoutValue" SG_ 771 SGU2_BlockCounter 0;
BA_ "Remark" SG_ 771 SGU2_BlockCounter "";
BA_ "EventCommandSignal" SG_ 771 SGU2_LifeCycles_OBJ 0;
BA_ "GatewayedSignals" SG_ 771 SGU2_LifeCycles_OBJ 0;
BA_ "GenSigInactiveValue" SG_ 771 SGU2_LifeCycles_OBJ 0;
BA_ "GenSigInvalidValue" SG_ 771 SGU2_LifeCycles_OBJ 0;
BA_ "GenSigSendType" SG_ 771 SGU2_LifeCycles_OBJ 1;
BA_ "GenSigStartValue" SG_ 771 SGU2_LifeCycles_OBJ 0;
BA_ "GenSigTimeoutValue" SG_ 771 SGU2_LifeCycles_OBJ 0;
BA_ "Remark" SG_ 771 SGU2_LifeCycles_OBJ "";
BA_ "EventCommandSignal" SG_ 771 SGU2_Msg_AliveCounter 0;
BA_ "GatewayedSignals" SG_ 771 SGU2_Msg_AliveCounter 0;
BA_ "GenSigInactiveValue" SG_ 771 SGU2_Msg_AliveCounter 0;
BA_ "GenSigInvalidValue" SG_ 771 SGU2_Msg_AliveCounter 0;
BA_ "GenSigSendType" SG_ 771 SGU2_Msg_AliveCounter 1;
BA_ "GenSigStartValue" SG_ 771 SGU2_Msg_AliveCounter 0;
BA_ "GenSigTimeoutValue" SG_ 771 SGU2_Msg_AliveCounter 0;
BA_ "Remark" SG_ 771 SGU2_Msg_AliveCounter "";
BA_ "EventCommandSignal" SG_ 771 SGU2_Msg_CheckSum 0;
BA_ "GatewayedSignals" SG_ 771 SGU2_Msg_CheckSum 0;
BA_ "GenSigInactiveValue" SG_ 771 SGU2_Msg_CheckSum 0;
BA_ "GenSigInvalidValue" SG_ 771 SGU2_Msg_CheckSum 0;
BA_ "GenSigSendType" SG_ 771 SGU2_Msg_CheckSum 1;
BA_ "GenSigStartValue" SG_ 771 SGU2_Msg_CheckSum 0;
BA_ "GenSigTimeoutValue" SG_ 771 SGU2_Msg_CheckSum 0;
BA_ "Remark" SG_ 771 SGU2_Msg_CheckSum "";
BA_ "EventCommandSignal" SG_ 771 SGU2_ObjRCS_02 0;
BA_ "GatewayedSignals" SG_ 771 SGU2_ObjRCS_02 0;
BA_ "GenSigInactiveValue" SG_ 771 SGU2_ObjRCS_02 0;
BA_ "GenSigInvalidValue" SG_ 771 SGU2_ObjRCS_02 0;
BA_ "GenSigSendType" SG_ 771 SGU2_ObjRCS_02 1;
BA_ "GenSigStartValue" SG_ 771 SGU2_ObjRCS_02 0;
BA_ "GenSigTimeoutValue" SG_ 771 SGU2_ObjRCS_02 0;
BA_ "Remark" SG_ 771 SGU2_ObjRCS_02 "";
BA_ "EventCommandSignal" SG_ 771 SGU2_Obj_DistLat_rms 0;
BA_ "GatewayedSignals" SG_ 771 SGU2_Obj_DistLat_rms 0;
BA_ "GenSigInactiveValue" SG_ 771 SGU2_Obj_DistLat_rms 0;
BA_ "GenSigInvalidValue" SG_ 771 SGU2_Obj_DistLat_rms 0;
BA_ "GenSigSendType" SG_ 771 SGU2_Obj_DistLat_rms 1;
BA_ "GenSigStartValue" SG_ 771 SGU2_Obj_DistLat_rms 0;
BA_ "GenSigTimeoutValue" SG_ 771 SGU2_Obj_DistLat_rms 0;
BA_ "Remark" SG_ 771 SGU2_Obj_DistLat_rms "";
BA_ "EventCommandSignal" SG_ 771 SGU2_Obj_VrelLong_rms 0;
BA_ "GatewayedSignals" SG_ 771 SGU2_Obj_VrelLong_rms 0;
BA_ "GenSigInactiveValue" SG_ 771 SGU2_Obj_VrelLong_rms 0;
BA_ "GenSigInvalidValue" SG_ 771 SGU2_Obj_VrelLong_rms 0;
BA_ "GenSigSendType" SG_ 771 SGU2_Obj_VrelLong_rms 1;
BA_ "GenSigStartValue" SG_ 771 SGU2_Obj_VrelLong_rms 0;
BA_ "GenSigTimeoutValue" SG_ 771 SGU2_Obj_VrelLong_rms 0;
BA_ "Remark" SG_ 771 SGU2_Obj_VrelLong_rms "";
BA_ "EventCommandSignal" SG_ 771 SGU2_Obj_Vrelat_rms 0;
BA_ "GatewayedSignals" SG_ 771 SGU2_Obj_Vrelat_rms 0;
BA_ "GenSigInactiveValue" SG_ 771 SGU2_Obj_Vrelat_rms 0;
BA_ "GenSigInvalidValue" SG_ 771 SGU2_Obj_Vrelat_rms 0;
BA_ "GenSigSendType" SG_ 771 SGU2_Obj_Vrelat_rms 1;
BA_ "GenSigStartValue" SG_ 771 SGU2_Obj_Vrelat_rms 0;
BA_ "GenSigTimeoutValue" SG_ 771 SGU2_Obj_Vrelat_rms 0;
BA_ "Remark" SG_ 771 SGU2_Obj_Vrelat_rms "";
BA_ "EventCommandSignal" SG_ 771 SGU2_Object_DetStatus 0;
BA_ "GatewayedSignals" SG_ 771 SGU2_Object_DetStatus 0;
BA_ "GenSigInactiveValue" SG_ 771 SGU2_Object_DetStatus 0;
BA_ "GenSigInvalidValue" SG_ 771 SGU2_Object_DetStatus 0;
BA_ "GenSigSendType" SG_ 771 SGU2_Object_DetStatus 1;
BA_ "GenSigStartValue" SG_ 771 SGU2_Object_DetStatus 0;
BA_ "GenSigTimeoutValue" SG_ 771 SGU2_Object_DetStatus 0;
BA_ "Remark" SG_ 771 SGU2_Object_DetStatus "";
BA_ "EventCommandSignal" SG_ 771 SGU2_Object_DistLong_rms 0;
BA_ "GatewayedSignals" SG_ 771 SGU2_Object_DistLong_rms 0;
BA_ "GenSigInactiveValue" SG_ 771 SGU2_Object_DistLong_rms 0;
BA_ "GenSigInvalidValue" SG_ 771 SGU2_Object_DistLong_rms 0;
BA_ "GenSigSendType" SG_ 771 SGU2_Object_DistLong_rms 1;
BA_ "GenSigStartValue" SG_ 771 SGU2_Object_DistLong_rms 0;
BA_ "GenSigTimeoutValue" SG_ 771 SGU2_Object_DistLong_rms 0;
BA_ "Remark" SG_ 771 SGU2_Object_DistLong_rms "";
BA_ "EventCommandSignal" SG_ 771 SGU2_Object_ID 0;
BA_ "GatewayedSignals" SG_ 771 SGU2_Object_ID 0;
BA_ "GenSigInactiveValue" SG_ 771 SGU2_Object_ID 0;
BA_ "GenSigInvalidValue" SG_ 771 SGU2_Object_ID 0;
BA_ "GenSigSendType" SG_ 771 SGU2_Object_ID 1;
BA_ "GenSigStartValue" SG_ 771 SGU2_Object_ID 0;
BA_ "GenSigTimeoutValue" SG_ 771 SGU2_Object_ID 0;
BA_ "Remark" SG_ 771 SGU2_Object_ID "";
BA_ "EventCommandSignal" SG_ 771 SGU2_Object_Motion_Pattern 0;
BA_ "GatewayedSignals" SG_ 771 SGU2_Object_Motion_Pattern 0;
BA_ "GenSigInactiveValue" SG_ 771 SGU2_Object_Motion_Pattern 0;
BA_ "GenSigInvalidValue" SG_ 771 SGU2_Object_Motion_Pattern 0;
BA_ "GenSigSendType" SG_ 771 SGU2_Object_Motion_Pattern 1;
BA_ "GenSigStartValue" SG_ 771 SGU2_Object_Motion_Pattern 0;
BA_ "GenSigTimeoutValue" SG_ 771 SGU2_Object_Motion_Pattern 0;
BA_ "Remark" SG_ 771 SGU2_Object_Motion_Pattern "";
BA_ "EventCommandSignal" SG_ 771 SGU2_Object_Type 0;
BA_ "GatewayedSignals" SG_ 771 SGU2_Object_Type 0;
BA_ "GenSigInactiveValue" SG_ 771 SGU2_Object_Type 0;
BA_ "GenSigInvalidValue" SG_ 771 SGU2_Object_Type 0;
BA_ "GenSigSendType" SG_ 771 SGU2_Object_Type 1;
BA_ "GenSigStartValue" SG_ 771 SGU2_Object_Type 0;
BA_ "GenSigTimeoutValue" SG_ 771 SGU2_Object_Type 0;
BA_ "Remark" SG_ 771 SGU2_Object_Type "";
BA_ "EventCommandSignal" SG_ 771 SGU2_Object_ax 0;
BA_ "GatewayedSignals" SG_ 771 SGU2_Object_ax 0;
BA_ "GenSigInactiveValue" SG_ 771 SGU2_Object_ax 0;
BA_ "GenSigInvalidValue" SG_ 771 SGU2_Object_ax 0;
BA_ "GenSigSendType" SG_ 771 SGU2_Object_ax 1;
BA_ "GenSigStartValue" SG_ 771 SGU2_Object_ax 0;
BA_ "GenSigTimeoutValue" SG_ 771 SGU2_Object_ax 0;
BA_ "Remark" SG_ 771 SGU2_Object_ax "";
BA_ "EventCommandSignal" SG_ 771 SGU2_Object_ay 0;
BA_ "GatewayedSignals" SG_ 771 SGU2_Object_ay 0;
BA_ "GenSigInactiveValue" SG_ 771 SGU2_Object_ay 0;
BA_ "GenSigInvalidValue" SG_ 771 SGU2_Object_ay 0;
BA_ "GenSigSendType" SG_ 771 SGU2_Object_ay 1;
BA_ "GenSigStartValue" SG_ 771 SGU2_Object_ay 0;
BA_ "GenSigTimeoutValue" SG_ 771 SGU2_Object_ay 0;
BA_ "Remark" SG_ 771 SGU2_Object_ay "";
BA_ "EventCommandSignal" SG_ 771 SGU2_Object_dx 0;
BA_ "GatewayedSignals" SG_ 771 SGU2_Object_dx 0;
BA_ "GenSigInactiveValue" SG_ 771 SGU2_Object_dx 0;
BA_ "GenSigInvalidValue" SG_ 771 SGU2_Object_dx 0;
BA_ "GenSigSendType" SG_ 771 SGU2_Object_dx 1;
BA_ "GenSigStartValue" SG_ 771 SGU2_Object_dx 0;
BA_ "GenSigTimeoutValue" SG_ 771 SGU2_Object_dx 0;
BA_ "Remark" SG_ 771 SGU2_Object_dx "";
BA_ "EventCommandSignal" SG_ 771 SGU2_Object_dx_Rear 0;
BA_ "GatewayedSignals" SG_ 771 SGU2_Object_dx_Rear 0;
BA_ "GenSigInactiveValue" SG_ 771 SGU2_Object_dx_Rear 0;
BA_ "GenSigInvalidValue" SG_ 771 SGU2_Object_dx_Rear 0;
BA_ "GenSigSendType" SG_ 771 SGU2_Object_dx_Rear 1;
BA_ "GenSigStartValue" SG_ 771 SGU2_Object_dx_Rear 0;
BA_ "GenSigTimeoutValue" SG_ 771 SGU2_Object_dx_Rear 0;
BA_ "Remark" SG_ 771 SGU2_Object_dx_Rear "";
BA_ "EventCommandSignal" SG_ 771 SGU2_Object_dy 0;
BA_ "GatewayedSignals" SG_ 771 SGU2_Object_dy 0;
BA_ "GenSigInactiveValue" SG_ 771 SGU2_Object_dy 0;
BA_ "GenSigInvalidValue" SG_ 771 SGU2_Object_dy 0;
BA_ "GenSigSendType" SG_ 771 SGU2_Object_dy 1;
BA_ "GenSigStartValue" SG_ 771 SGU2_Object_dy 0;
BA_ "GenSigTimeoutValue" SG_ 771 SGU2_Object_dy 0;
BA_ "Remark" SG_ 771 SGU2_Object_dy "";
BA_ "EventCommandSignal" SG_ 771 SGU2_Object_dy_Rear 0;
BA_ "GatewayedSignals" SG_ 771 SGU2_Object_dy_Rear 0;
BA_ "GenSigInactiveValue" SG_ 771 SGU2_Object_dy_Rear 0;
BA_ "GenSigInvalidValue" SG_ 771 SGU2_Object_dy_Rear 0;
BA_ "GenSigSendType" SG_ 771 SGU2_Object_dy_Rear 1;
BA_ "GenSigStartValue" SG_ 771 SGU2_Object_dy_Rear 0;
BA_ "GenSigTimeoutValue" SG_ 771 SGU2_Object_dy_Rear 0;
BA_ "Remark" SG_ 771 SGU2_Object_dy_Rear "";
BA_ "EventCommandSignal" SG_ 771 SGU2_Object_vx 0;
BA_ "GatewayedSignals" SG_ 771 SGU2_Object_vx 0;
BA_ "GenSigInactiveValue" SG_ 771 SGU2_Object_vx 0;
BA_ "GenSigInvalidValue" SG_ 771 SGU2_Object_vx 0;
BA_ "GenSigSendType" SG_ 771 SGU2_Object_vx 1;
BA_ "GenSigStartValue" SG_ 771 SGU2_Object_vx 0;
BA_ "GenSigTimeoutValue" SG_ 771 SGU2_Object_vx 0;
BA_ "Remark" SG_ 771 SGU2_Object_vx "";
BA_ "EventCommandSignal" SG_ 771 SGU2_Object_vy 0;
BA_ "GatewayedSignals" SG_ 771 SGU2_Object_vy 0;
BA_ "GenSigInactiveValue" SG_ 771 SGU2_Object_vy 0;
BA_ "GenSigInvalidValue" SG_ 771 SGU2_Object_vy 0;
BA_ "GenSigSendType" SG_ 771 SGU2_Object_vy 1;
BA_ "GenSigStartValue" SG_ 771 SGU2_Object_vy 0;
BA_ "GenSigTimeoutValue" SG_ 771 SGU2_Object_vy 0;
BA_ "Remark" SG_ 771 SGU2_Object_vy "";
BA_ "EventCommandSignal" SG_ 771 SGU2_Object_wExist 0;
BA_ "GatewayedSignals" SG_ 771 SGU2_Object_wExist 0;
BA_ "GenSigInactiveValue" SG_ 771 SGU2_Object_wExist 0;
BA_ "GenSigInvalidValue" SG_ 771 SGU2_Object_wExist 0;
BA_ "GenSigSendType" SG_ 771 SGU2_Object_wExist 1;
BA_ "GenSigStartValue" SG_ 771 SGU2_Object_wExist 0;
BA_ "GenSigTimeoutValue" SG_ 771 SGU2_Object_wExist 0;
BA_ "Remark" SG_ 771 SGU2_Object_wExist "";
BA_ "EventCommandSignal" SG_ 771 SGU2_Object_wObstacle 0;
BA_ "GatewayedSignals" SG_ 771 SGU2_Object_wObstacle 0;
BA_ "GenSigInactiveValue" SG_ 771 SGU2_Object_wObstacle 0;
BA_ "GenSigInvalidValue" SG_ 771 SGU2_Object_wObstacle 0;
BA_ "GenSigSendType" SG_ 771 SGU2_Object_wObstacle 1;
BA_ "GenSigStartValue" SG_ 771 SGU2_Object_wObstacle 0;
BA_ "GenSigTimeoutValue" SG_ 771 SGU2_Object_wObstacle 0;
BA_ "Remark" SG_ 771 SGU2_Object_wObstacle "";
BA_ "EventCommandSignal" SG_ 772 SGU3_BlockCounter 0;
BA_ "GatewayedSignals" SG_ 772 SGU3_BlockCounter 0;
BA_ "GenSigInactiveValue" SG_ 772 SGU3_BlockCounter 0;
BA_ "GenSigInvalidValue" SG_ 772 SGU3_BlockCounter 0;
BA_ "GenSigSendType" SG_ 772 SGU3_BlockCounter 1;
BA_ "GenSigStartValue" SG_ 772 SGU3_BlockCounter 0;
BA_ "GenSigTimeoutValue" SG_ 772 SGU3_BlockCounter 0;
BA_ "Remark" SG_ 772 SGU3_BlockCounter "";
BA_ "EventCommandSignal" SG_ 772 SGU3_LifeCycles_OBJ 0;
BA_ "GatewayedSignals" SG_ 772 SGU3_LifeCycles_OBJ 0;
BA_ "GenSigInactiveValue" SG_ 772 SGU3_LifeCycles_OBJ 0;
BA_ "GenSigInvalidValue" SG_ 772 SGU3_LifeCycles_OBJ 0;
BA_ "GenSigSendType" SG_ 772 SGU3_LifeCycles_OBJ 1;
BA_ "GenSigStartValue" SG_ 772 SGU3_LifeCycles_OBJ 0;
BA_ "GenSigTimeoutValue" SG_ 772 SGU3_LifeCycles_OBJ 0;
BA_ "Remark" SG_ 772 SGU3_LifeCycles_OBJ "";
BA_ "EventCommandSignal" SG_ 772 SGU3_Msg_AliveCounter 0;
BA_ "GatewayedSignals" SG_ 772 SGU3_Msg_AliveCounter 0;
BA_ "GenSigInactiveValue" SG_ 772 SGU3_Msg_AliveCounter 0;
BA_ "GenSigInvalidValue" SG_ 772 SGU3_Msg_AliveCounter 0;
BA_ "GenSigSendType" SG_ 772 SGU3_Msg_AliveCounter 1;
BA_ "GenSigStartValue" SG_ 772 SGU3_Msg_AliveCounter 0;
BA_ "GenSigTimeoutValue" SG_ 772 SGU3_Msg_AliveCounter 0;
BA_ "Remark" SG_ 772 SGU3_Msg_AliveCounter "";
BA_ "EventCommandSignal" SG_ 772 SGU3_Msg_CheckSum 0;
BA_ "GatewayedSignals" SG_ 772 SGU3_Msg_CheckSum 0;
BA_ "GenSigInactiveValue" SG_ 772 SGU3_Msg_CheckSum 0;
BA_ "GenSigInvalidValue" SG_ 772 SGU3_Msg_CheckSum 0;
BA_ "GenSigSendType" SG_ 772 SGU3_Msg_CheckSum 1;
BA_ "GenSigStartValue" SG_ 772 SGU3_Msg_CheckSum 0;
BA_ "GenSigTimeoutValue" SG_ 772 SGU3_Msg_CheckSum 0;
BA_ "Remark" SG_ 772 SGU3_Msg_CheckSum "";
BA_ "EventCommandSignal" SG_ 772 SGU3_ObjRCS_03 0;
BA_ "GatewayedSignals" SG_ 772 SGU3_ObjRCS_03 0;
BA_ "GenSigInactiveValue" SG_ 772 SGU3_ObjRCS_03 0;
BA_ "GenSigInvalidValue" SG_ 772 SGU3_ObjRCS_03 0;
BA_ "GenSigSendType" SG_ 772 SGU3_ObjRCS_03 1;
BA_ "GenSigStartValue" SG_ 772 SGU3_ObjRCS_03 0;
BA_ "GenSigTimeoutValue" SG_ 772 SGU3_ObjRCS_03 0;
BA_ "Remark" SG_ 772 SGU3_ObjRCS_03 "";
BA_ "EventCommandSignal" SG_ 772 SGU3_Obj_DistLat_rms 0;
BA_ "GatewayedSignals" SG_ 772 SGU3_Obj_DistLat_rms 0;
BA_ "GenSigInactiveValue" SG_ 772 SGU3_Obj_DistLat_rms 0;
BA_ "GenSigInvalidValue" SG_ 772 SGU3_Obj_DistLat_rms 0;
BA_ "GenSigSendType" SG_ 772 SGU3_Obj_DistLat_rms 1;
BA_ "GenSigStartValue" SG_ 772 SGU3_Obj_DistLat_rms 0;
BA_ "GenSigTimeoutValue" SG_ 772 SGU3_Obj_DistLat_rms 0;
BA_ "Remark" SG_ 772 SGU3_Obj_DistLat_rms "";
BA_ "EventCommandSignal" SG_ 772 SGU3_Obj_VrelLong_rms 0;
BA_ "GatewayedSignals" SG_ 772 SGU3_Obj_VrelLong_rms 0;
BA_ "GenSigInactiveValue" SG_ 772 SGU3_Obj_VrelLong_rms 0;
BA_ "GenSigInvalidValue" SG_ 772 SGU3_Obj_VrelLong_rms 0;
BA_ "GenSigSendType" SG_ 772 SGU3_Obj_VrelLong_rms 1;
BA_ "GenSigStartValue" SG_ 772 SGU3_Obj_VrelLong_rms 0;
BA_ "GenSigTimeoutValue" SG_ 772 SGU3_Obj_VrelLong_rms 0;
BA_ "Remark" SG_ 772 SGU3_Obj_VrelLong_rms "";
BA_ "EventCommandSignal" SG_ 772 SGU3_Obj_Vrelat_rms 0;
BA_ "GatewayedSignals" SG_ 772 SGU3_Obj_Vrelat_rms 0;
BA_ "GenSigInactiveValue" SG_ 772 SGU3_Obj_Vrelat_rms 0;
BA_ "GenSigInvalidValue" SG_ 772 SGU3_Obj_Vrelat_rms 0;
BA_ "GenSigSendType" SG_ 772 SGU3_Obj_Vrelat_rms 1;
BA_ "GenSigStartValue" SG_ 772 SGU3_Obj_Vrelat_rms 0;
BA_ "GenSigTimeoutValue" SG_ 772 SGU3_Obj_Vrelat_rms 0;
BA_ "Remark" SG_ 772 SGU3_Obj_Vrelat_rms "";
BA_ "EventCommandSignal" SG_ 772 SGU3_Object_DetStatus 0;
BA_ "GatewayedSignals" SG_ 772 SGU3_Object_DetStatus 0;
BA_ "GenSigInactiveValue" SG_ 772 SGU3_Object_DetStatus 0;
BA_ "GenSigInvalidValue" SG_ 772 SGU3_Object_DetStatus 0;
BA_ "GenSigSendType" SG_ 772 SGU3_Object_DetStatus 1;
BA_ "GenSigStartValue" SG_ 772 SGU3_Object_DetStatus 0;
BA_ "GenSigTimeoutValue" SG_ 772 SGU3_Object_DetStatus 0;
BA_ "Remark" SG_ 772 SGU3_Object_DetStatus "";
BA_ "EventCommandSignal" SG_ 772 SGU3_Object_DistLong_rms 0;
BA_ "GatewayedSignals" SG_ 772 SGU3_Object_DistLong_rms 0;
BA_ "GenSigInactiveValue" SG_ 772 SGU3_Object_DistLong_rms 0;
BA_ "GenSigInvalidValue" SG_ 772 SGU3_Object_DistLong_rms 0;
BA_ "GenSigSendType" SG_ 772 SGU3_Object_DistLong_rms 1;
BA_ "GenSigStartValue" SG_ 772 SGU3_Object_DistLong_rms 0;
BA_ "GenSigTimeoutValue" SG_ 772 SGU3_Object_DistLong_rms 0;
BA_ "Remark" SG_ 772 SGU3_Object_DistLong_rms "";
BA_ "EventCommandSignal" SG_ 772 SGU3_Object_ID 0;
BA_ "GatewayedSignals" SG_ 772 SGU3_Object_ID 0;
BA_ "GenSigInactiveValue" SG_ 772 SGU3_Object_ID 0;
BA_ "GenSigInvalidValue" SG_ 772 SGU3_Object_ID 0;
BA_ "GenSigSendType" SG_ 772 SGU3_Object_ID 1;
BA_ "GenSigStartValue" SG_ 772 SGU3_Object_ID 0;
BA_ "GenSigTimeoutValue" SG_ 772 SGU3_Object_ID 0;
BA_ "Remark" SG_ 772 SGU3_Object_ID "";
BA_ "EventCommandSignal" SG_ 772 SGU3_Object_Motion_Pattern 0;
BA_ "GatewayedSignals" SG_ 772 SGU3_Object_Motion_Pattern 0;
BA_ "GenSigInactiveValue" SG_ 772 SGU3_Object_Motion_Pattern 0;
BA_ "GenSigInvalidValue" SG_ 772 SGU3_Object_Motion_Pattern 0;
BA_ "GenSigSendType" SG_ 772 SGU3_Object_Motion_Pattern 1;
BA_ "GenSigStartValue" SG_ 772 SGU3_Object_Motion_Pattern 0;
BA_ "GenSigTimeoutValue" SG_ 772 SGU3_Object_Motion_Pattern 0;
BA_ "Remark" SG_ 772 SGU3_Object_Motion_Pattern "";
BA_ "EventCommandSignal" SG_ 772 SGU3_Object_Type 0;
BA_ "GatewayedSignals" SG_ 772 SGU3_Object_Type 0;
BA_ "GenSigInactiveValue" SG_ 772 SGU3_Object_Type 0;
BA_ "GenSigInvalidValue" SG_ 772 SGU3_Object_Type 0;
BA_ "GenSigSendType" SG_ 772 SGU3_Object_Type 1;
BA_ "GenSigStartValue" SG_ 772 SGU3_Object_Type 0;
BA_ "GenSigTimeoutValue" SG_ 772 SGU3_Object_Type 0;
BA_ "Remark" SG_ 772 SGU3_Object_Type "";
BA_ "EventCommandSignal" SG_ 772 SGU3_Object_ax 0;
BA_ "GatewayedSignals" SG_ 772 SGU3_Object_ax 0;
BA_ "GenSigInactiveValue" SG_ 772 SGU3_Object_ax 0;
BA_ "GenSigInvalidValue" SG_ 772 SGU3_Object_ax 0;
BA_ "GenSigSendType" SG_ 772 SGU3_Object_ax 1;
BA_ "GenSigStartValue" SG_ 772 SGU3_Object_ax 0;
BA_ "GenSigTimeoutValue" SG_ 772 SGU3_Object_ax 0;
BA_ "Remark" SG_ 772 SGU3_Object_ax "";
BA_ "EventCommandSignal" SG_ 772 SGU3_Object_ay 0;
BA_ "GatewayedSignals" SG_ 772 SGU3_Object_ay 0;
BA_ "GenSigInactiveValue" SG_ 772 SGU3_Object_ay 0;
BA_ "GenSigInvalidValue" SG_ 772 SGU3_Object_ay 0;
BA_ "GenSigSendType" SG_ 772 SGU3_Object_ay 1;
BA_ "GenSigStartValue" SG_ 772 SGU3_Object_ay 0;
BA_ "GenSigTimeoutValue" SG_ 772 SGU3_Object_ay 0;
BA_ "Remark" SG_ 772 SGU3_Object_ay "";
BA_ "EventCommandSignal" SG_ 772 SGU3_Object_dx 0;
BA_ "GatewayedSignals" SG_ 772 SGU3_Object_dx 0;
BA_ "GenSigInactiveValue" SG_ 772 SGU3_Object_dx 0;
BA_ "GenSigInvalidValue" SG_ 772 SGU3_Object_dx 0;
BA_ "GenSigSendType" SG_ 772 SGU3_Object_dx 1;
BA_ "GenSigStartValue" SG_ 772 SGU3_Object_dx 0;
BA_ "GenSigTimeoutValue" SG_ 772 SGU3_Object_dx 0;
BA_ "Remark" SG_ 772 SGU3_Object_dx "";
BA_ "EventCommandSignal" SG_ 772 SGU3_Object_dx_Rear 0;
BA_ "GatewayedSignals" SG_ 772 SGU3_Object_dx_Rear 0;
BA_ "GenSigInactiveValue" SG_ 772 SGU3_Object_dx_Rear 0;
BA_ "GenSigInvalidValue" SG_ 772 SGU3_Object_dx_Rear 0;
BA_ "GenSigSendType" SG_ 772 SGU3_Object_dx_Rear 1;
BA_ "GenSigStartValue" SG_ 772 SGU3_Object_dx_Rear 0;
BA_ "GenSigTimeoutValue" SG_ 772 SGU3_Object_dx_Rear 0;
BA_ "Remark" SG_ 772 SGU3_Object_dx_Rear "";
BA_ "EventCommandSignal" SG_ 772 SGU3_Object_dy 0;
BA_ "GatewayedSignals" SG_ 772 SGU3_Object_dy 0;
BA_ "GenSigInactiveValue" SG_ 772 SGU3_Object_dy 0;
BA_ "GenSigInvalidValue" SG_ 772 SGU3_Object_dy 0;
BA_ "GenSigSendType" SG_ 772 SGU3_Object_dy 1;
BA_ "GenSigStartValue" SG_ 772 SGU3_Object_dy 0;
BA_ "GenSigTimeoutValue" SG_ 772 SGU3_Object_dy 0;
BA_ "Remark" SG_ 772 SGU3_Object_dy "";
BA_ "EventCommandSignal" SG_ 772 SGU3_Object_dy_Rear 0;
BA_ "GatewayedSignals" SG_ 772 SGU3_Object_dy_Rear 0;
BA_ "GenSigInactiveValue" SG_ 772 SGU3_Object_dy_Rear 0;
BA_ "GenSigInvalidValue" SG_ 772 SGU3_Object_dy_Rear 0;
BA_ "GenSigSendType" SG_ 772 SGU3_Object_dy_Rear 1;
BA_ "GenSigStartValue" SG_ 772 SGU3_Object_dy_Rear 0;
BA_ "GenSigTimeoutValue" SG_ 772 SGU3_Object_dy_Rear 0;
BA_ "Remark" SG_ 772 SGU3_Object_dy_Rear "";
BA_ "EventCommandSignal" SG_ 772 SGU3_Object_vx 0;
BA_ "GatewayedSignals" SG_ 772 SGU3_Object_vx 0;
BA_ "GenSigInactiveValue" SG_ 772 SGU3_Object_vx 0;
BA_ "GenSigInvalidValue" SG_ 772 SGU3_Object_vx 0;
BA_ "GenSigSendType" SG_ 772 SGU3_Object_vx 1;
BA_ "GenSigStartValue" SG_ 772 SGU3_Object_vx 0;
BA_ "GenSigTimeoutValue" SG_ 772 SGU3_Object_vx 0;
BA_ "Remark" SG_ 772 SGU3_Object_vx "";
BA_ "EventCommandSignal" SG_ 772 SGU3_Object_vy 0;
BA_ "GatewayedSignals" SG_ 772 SGU3_Object_vy 0;
BA_ "GenSigInactiveValue" SG_ 772 SGU3_Object_vy 0;
BA_ "GenSigInvalidValue" SG_ 772 SGU3_Object_vy 0;
BA_ "GenSigSendType" SG_ 772 SGU3_Object_vy 1;
BA_ "GenSigStartValue" SG_ 772 SGU3_Object_vy 0;
BA_ "GenSigTimeoutValue" SG_ 772 SGU3_Object_vy 0;
BA_ "Remark" SG_ 772 SGU3_Object_vy "";
BA_ "EventCommandSignal" SG_ 772 SGU3_Object_wExist 0;
BA_ "GatewayedSignals" SG_ 772 SGU3_Object_wExist 0;
BA_ "GenSigInactiveValue" SG_ 772 SGU3_Object_wExist 0;
BA_ "GenSigInvalidValue" SG_ 772 SGU3_Object_wExist 0;
BA_ "GenSigSendType" SG_ 772 SGU3_Object_wExist 1;
BA_ "GenSigStartValue" SG_ 772 SGU3_Object_wExist 0;
BA_ "GenSigTimeoutValue" SG_ 772 SGU3_Object_wExist 0;
BA_ "Remark" SG_ 772 SGU3_Object_wExist "";
BA_ "EventCommandSignal" SG_ 772 SGU3_Object_wObstacle 0;
BA_ "GatewayedSignals" SG_ 772 SGU3_Object_wObstacle 0;
BA_ "GenSigInactiveValue" SG_ 772 SGU3_Object_wObstacle 0;
BA_ "GenSigInvalidValue" SG_ 772 SGU3_Object_wObstacle 0;
BA_ "GenSigSendType" SG_ 772 SGU3_Object_wObstacle 1;
BA_ "GenSigStartValue" SG_ 772 SGU3_Object_wObstacle 0;
BA_ "GenSigTimeoutValue" SG_ 772 SGU3_Object_wObstacle 0;
BA_ "Remark" SG_ 772 SGU3_Object_wObstacle "";
BA_ "EventCommandSignal" SG_ 773 SGU4_BlockCounter 0;
BA_ "GatewayedSignals" SG_ 773 SGU4_BlockCounter 0;
BA_ "GenSigInactiveValue" SG_ 773 SGU4_BlockCounter 0;
BA_ "GenSigInvalidValue" SG_ 773 SGU4_BlockCounter 0;
BA_ "GenSigSendType" SG_ 773 SGU4_BlockCounter 1;
BA_ "GenSigStartValue" SG_ 773 SGU4_BlockCounter 0;
BA_ "GenSigTimeoutValue" SG_ 773 SGU4_BlockCounter 0;
BA_ "Remark" SG_ 773 SGU4_BlockCounter "";
BA_ "EventCommandSignal" SG_ 773 SGU4_LifeCycles_OBJ 0;
BA_ "GatewayedSignals" SG_ 773 SGU4_LifeCycles_OBJ 0;
BA_ "GenSigInactiveValue" SG_ 773 SGU4_LifeCycles_OBJ 0;
BA_ "GenSigInvalidValue" SG_ 773 SGU4_LifeCycles_OBJ 0;
BA_ "GenSigSendType" SG_ 773 SGU4_LifeCycles_OBJ 1;
BA_ "GenSigStartValue" SG_ 773 SGU4_LifeCycles_OBJ 0;
BA_ "GenSigTimeoutValue" SG_ 773 SGU4_LifeCycles_OBJ 0;
BA_ "Remark" SG_ 773 SGU4_LifeCycles_OBJ "";
BA_ "EventCommandSignal" SG_ 773 SGU4_Msg_AliveCounter 0;
BA_ "GatewayedSignals" SG_ 773 SGU4_Msg_AliveCounter 0;
BA_ "GenSigInactiveValue" SG_ 773 SGU4_Msg_AliveCounter 0;
BA_ "GenSigInvalidValue" SG_ 773 SGU4_Msg_AliveCounter 0;
BA_ "GenSigSendType" SG_ 773 SGU4_Msg_AliveCounter 1;
BA_ "GenSigStartValue" SG_ 773 SGU4_Msg_AliveCounter 0;
BA_ "GenSigTimeoutValue" SG_ 773 SGU4_Msg_AliveCounter 0;
BA_ "Remark" SG_ 773 SGU4_Msg_AliveCounter "";
BA_ "EventCommandSignal" SG_ 773 SGU4_Msg_CheckSum 0;
BA_ "GatewayedSignals" SG_ 773 SGU4_Msg_CheckSum 0;
BA_ "GenSigInactiveValue" SG_ 773 SGU4_Msg_CheckSum 0;
BA_ "GenSigInvalidValue" SG_ 773 SGU4_Msg_CheckSum 0;
BA_ "GenSigSendType" SG_ 773 SGU4_Msg_CheckSum 1;
BA_ "GenSigStartValue" SG_ 773 SGU4_Msg_CheckSum 0;
BA_ "GenSigTimeoutValue" SG_ 773 SGU4_Msg_CheckSum 0;
BA_ "Remark" SG_ 773 SGU4_Msg_CheckSum "";
BA_ "EventCommandSignal" SG_ 773 SGU4_ObjRCS_04 0;
BA_ "GatewayedSignals" SG_ 773 SGU4_ObjRCS_04 0;
BA_ "GenSigInactiveValue" SG_ 773 SGU4_ObjRCS_04 0;
BA_ "GenSigInvalidValue" SG_ 773 SGU4_ObjRCS_04 0;
BA_ "GenSigSendType" SG_ 773 SGU4_ObjRCS_04 1;
BA_ "GenSigStartValue" SG_ 773 SGU4_ObjRCS_04 0;
BA_ "GenSigTimeoutValue" SG_ 773 SGU4_ObjRCS_04 0;
BA_ "Remark" SG_ 773 SGU4_ObjRCS_04 "";
BA_ "EventCommandSignal" SG_ 773 SGU4_Obj_DistLat_rms 0;
BA_ "GatewayedSignals" SG_ 773 SGU4_Obj_DistLat_rms 0;
BA_ "GenSigInactiveValue" SG_ 773 SGU4_Obj_DistLat_rms 0;
BA_ "GenSigInvalidValue" SG_ 773 SGU4_Obj_DistLat_rms 0;
BA_ "GenSigSendType" SG_ 773 SGU4_Obj_DistLat_rms 1;
BA_ "GenSigStartValue" SG_ 773 SGU4_Obj_DistLat_rms 0;
BA_ "GenSigTimeoutValue" SG_ 773 SGU4_Obj_DistLat_rms 0;
BA_ "Remark" SG_ 773 SGU4_Obj_DistLat_rms "";
BA_ "EventCommandSignal" SG_ 773 SGU4_Obj_VrelLong_rms 0;
BA_ "GatewayedSignals" SG_ 773 SGU4_Obj_VrelLong_rms 0;
BA_ "GenSigInactiveValue" SG_ 773 SGU4_Obj_VrelLong_rms 0;
BA_ "GenSigInvalidValue" SG_ 773 SGU4_Obj_VrelLong_rms 0;
BA_ "GenSigSendType" SG_ 773 SGU4_Obj_VrelLong_rms 1;
BA_ "GenSigStartValue" SG_ 773 SGU4_Obj_VrelLong_rms 0;
BA_ "GenSigTimeoutValue" SG_ 773 SGU4_Obj_VrelLong_rms 0;
BA_ "Remark" SG_ 773 SGU4_Obj_VrelLong_rms "";
BA_ "EventCommandSignal" SG_ 773 SGU4_Obj_Vrelat_rms 0;
BA_ "GatewayedSignals" SG_ 773 SGU4_Obj_Vrelat_rms 0;
BA_ "GenSigInactiveValue" SG_ 773 SGU4_Obj_Vrelat_rms 0;
BA_ "GenSigInvalidValue" SG_ 773 SGU4_Obj_Vrelat_rms 0;
BA_ "GenSigSendType" SG_ 773 SGU4_Obj_Vrelat_rms 1;
BA_ "GenSigStartValue" SG_ 773 SGU4_Obj_Vrelat_rms 0;
BA_ "GenSigTimeoutValue" SG_ 773 SGU4_Obj_Vrelat_rms 0;
BA_ "Remark" SG_ 773 SGU4_Obj_Vrelat_rms "";
BA_ "EventCommandSignal" SG_ 773 SGU4_Object_DetStatus 0;
BA_ "GatewayedSignals" SG_ 773 SGU4_Object_DetStatus 0;
BA_ "GenSigInactiveValue" SG_ 773 SGU4_Object_DetStatus 0;
BA_ "GenSigInvalidValue" SG_ 773 SGU4_Object_DetStatus 0;
BA_ "GenSigSendType" SG_ 773 SGU4_Object_DetStatus 1;
BA_ "GenSigStartValue" SG_ 773 SGU4_Object_DetStatus 0;
BA_ "GenSigTimeoutValue" SG_ 773 SGU4_Object_DetStatus 0;
BA_ "Remark" SG_ 773 SGU4_Object_DetStatus "";
BA_ "EventCommandSignal" SG_ 773 SGU4_Object_DistLong_rms 0;
BA_ "GatewayedSignals" SG_ 773 SGU4_Object_DistLong_rms 0;
BA_ "GenSigInactiveValue" SG_ 773 SGU4_Object_DistLong_rms 0;
BA_ "GenSigInvalidValue" SG_ 773 SGU4_Object_DistLong_rms 0;
BA_ "GenSigSendType" SG_ 773 SGU4_Object_DistLong_rms 1;
BA_ "GenSigStartValue" SG_ 773 SGU4_Object_DistLong_rms 0;
BA_ "GenSigTimeoutValue" SG_ 773 SGU4_Object_DistLong_rms 0;
BA_ "Remark" SG_ 773 SGU4_Object_DistLong_rms "";
BA_ "EventCommandSignal" SG_ 773 SGU4_Object_ID 0;
BA_ "GatewayedSignals" SG_ 773 SGU4_Object_ID 0;
BA_ "GenSigInactiveValue" SG_ 773 SGU4_Object_ID 0;
BA_ "GenSigInvalidValue" SG_ 773 SGU4_Object_ID 0;
BA_ "GenSigSendType" SG_ 773 SGU4_Object_ID 1;
BA_ "GenSigStartValue" SG_ 773 SGU4_Object_ID 0;
BA_ "GenSigTimeoutValue" SG_ 773 SGU4_Object_ID 0;
BA_ "Remark" SG_ 773 SGU4_Object_ID "";
BA_ "EventCommandSignal" SG_ 773 SGU4_Object_Motion_Pattern 0;
BA_ "GatewayedSignals" SG_ 773 SGU4_Object_Motion_Pattern 0;
BA_ "GenSigInactiveValue" SG_ 773 SGU4_Object_Motion_Pattern 0;
BA_ "GenSigInvalidValue" SG_ 773 SGU4_Object_Motion_Pattern 0;
BA_ "GenSigSendType" SG_ 773 SGU4_Object_Motion_Pattern 1;
BA_ "GenSigStartValue" SG_ 773 SGU4_Object_Motion_Pattern 0;
BA_ "GenSigTimeoutValue" SG_ 773 SGU4_Object_Motion_Pattern 0;
BA_ "Remark" SG_ 773 SGU4_Object_Motion_Pattern "";
BA_ "EventCommandSignal" SG_ 773 SGU4_Object_Type 0;
BA_ "GatewayedSignals" SG_ 773 SGU4_Object_Type 0;
BA_ "GenSigInactiveValue" SG_ 773 SGU4_Object_Type 0;
BA_ "GenSigInvalidValue" SG_ 773 SGU4_Object_Type 0;
BA_ "GenSigSendType" SG_ 773 SGU4_Object_Type 1;
BA_ "GenSigStartValue" SG_ 773 SGU4_Object_Type 0;
BA_ "GenSigTimeoutValue" SG_ 773 SGU4_Object_Type 0;
BA_ "Remark" SG_ 773 SGU4_Object_Type "";
BA_ "EventCommandSignal" SG_ 773 SGU4_Object_ax 0;
BA_ "GatewayedSignals" SG_ 773 SGU4_Object_ax 0;
BA_ "GenSigInactiveValue" SG_ 773 SGU4_Object_ax 0;
BA_ "GenSigInvalidValue" SG_ 773 SGU4_Object_ax 0;
BA_ "GenSigSendType" SG_ 773 SGU4_Object_ax 1;
BA_ "GenSigStartValue" SG_ 773 SGU4_Object_ax 0;
BA_ "GenSigTimeoutValue" SG_ 773 SGU4_Object_ax 0;
BA_ "Remark" SG_ 773 SGU4_Object_ax "";
BA_ "EventCommandSignal" SG_ 773 SGU4_Object_ay 0;
BA_ "GatewayedSignals" SG_ 773 SGU4_Object_ay 0;
BA_ "GenSigInactiveValue" SG_ 773 SGU4_Object_ay 0;
BA_ "GenSigInvalidValue" SG_ 773 SGU4_Object_ay 0;
BA_ "GenSigSendType" SG_ 773 SGU4_Object_ay 1;
BA_ "GenSigStartValue" SG_ 773 SGU4_Object_ay 0;
BA_ "GenSigTimeoutValue" SG_ 773 SGU4_Object_ay 0;
BA_ "Remark" SG_ 773 SGU4_Object_ay "";
BA_ "EventCommandSignal" SG_ 773 SGU4_Object_dx 0;
BA_ "GatewayedSignals" SG_ 773 SGU4_Object_dx 0;
BA_ "GenSigInactiveValue" SG_ 773 SGU4_Object_dx 0;
BA_ "GenSigInvalidValue" SG_ 773 SGU4_Object_dx 0;
BA_ "GenSigSendType" SG_ 773 SGU4_Object_dx 1;
BA_ "GenSigStartValue" SG_ 773 SGU4_Object_dx 0;
BA_ "GenSigTimeoutValue" SG_ 773 SGU4_Object_dx 0;
BA_ "Remark" SG_ 773 SGU4_Object_dx "";
BA_ "EventCommandSignal" SG_ 773 SGU4_Object_dx_Rear 0;
BA_ "GatewayedSignals" SG_ 773 SGU4_Object_dx_Rear 0;
BA_ "GenSigInactiveValue" SG_ 773 SGU4_Object_dx_Rear 0;
BA_ "GenSigInvalidValue" SG_ 773 SGU4_Object_dx_Rear 0;
BA_ "GenSigSendType" SG_ 773 SGU4_Object_dx_Rear 1;
BA_ "GenSigStartValue" SG_ 773 SGU4_Object_dx_Rear 0;
BA_ "GenSigTimeoutValue" SG_ 773 SGU4_Object_dx_Rear 0;
BA_ "Remark" SG_ 773 SGU4_Object_dx_Rear "";
BA_ "EventCommandSignal" SG_ 773 SGU4_Object_dy 0;
BA_ "GatewayedSignals" SG_ 773 SGU4_Object_dy 0;
BA_ "GenSigInactiveValue" SG_ 773 SGU4_Object_dy 0;
BA_ "GenSigInvalidValue" SG_ 773 SGU4_Object_dy 0;
BA_ "GenSigSendType" SG_ 773 SGU4_Object_dy 1;
BA_ "GenSigStartValue" SG_ 773 SGU4_Object_dy 0;
BA_ "GenSigTimeoutValue" SG_ 773 SGU4_Object_dy 0;
BA_ "Remark" SG_ 773 SGU4_Object_dy "";
BA_ "EventCommandSignal" SG_ 773 SGU4_Object_dy_Rear 0;
BA_ "GatewayedSignals" SG_ 773 SGU4_Object_dy_Rear 0;
BA_ "GenSigInactiveValue" SG_ 773 SGU4_Object_dy_Rear 0;
BA_ "GenSigInvalidValue" SG_ 773 SGU4_Object_dy_Rear 0;
BA_ "GenSigSendType" SG_ 773 SGU4_Object_dy_Rear 1;
BA_ "GenSigStartValue" SG_ 773 SGU4_Object_dy_Rear 0;
BA_ "GenSigTimeoutValue" SG_ 773 SGU4_Object_dy_Rear 0;
BA_ "Remark" SG_ 773 SGU4_Object_dy_Rear "";
BA_ "EventCommandSignal" SG_ 773 SGU4_Object_vx 0;
BA_ "GatewayedSignals" SG_ 773 SGU4_Object_vx 0;
BA_ "GenSigInactiveValue" SG_ 773 SGU4_Object_vx 0;
BA_ "GenSigInvalidValue" SG_ 773 SGU4_Object_vx 0;
BA_ "GenSigSendType" SG_ 773 SGU4_Object_vx 1;
BA_ "GenSigStartValue" SG_ 773 SGU4_Object_vx 0;
BA_ "GenSigTimeoutValue" SG_ 773 SGU4_Object_vx 0;
BA_ "Remark" SG_ 773 SGU4_Object_vx "";
BA_ "EventCommandSignal" SG_ 773 SGU4_Object_vy 0;
BA_ "GatewayedSignals" SG_ 773 SGU4_Object_vy 0;
BA_ "GenSigInactiveValue" SG_ 773 SGU4_Object_vy 0;
BA_ "GenSigInvalidValue" SG_ 773 SGU4_Object_vy 0;
BA_ "GenSigSendType" SG_ 773 SGU4_Object_vy 1;
BA_ "GenSigStartValue" SG_ 773 SGU4_Object_vy 0;
BA_ "GenSigTimeoutValue" SG_ 773 SGU4_Object_vy 0;
BA_ "Remark" SG_ 773 SGU4_Object_vy "";
BA_ "EventCommandSignal" SG_ 773 SGU4_Object_wExist 0;
BA_ "GatewayedSignals" SG_ 773 SGU4_Object_wExist 0;
BA_ "GenSigInactiveValue" SG_ 773 SGU4_Object_wExist 0;
BA_ "GenSigInvalidValue" SG_ 773 SGU4_Object_wExist 0;
BA_ "GenSigSendType" SG_ 773 SGU4_Object_wExist 1;
BA_ "GenSigStartValue" SG_ 773 SGU4_Object_wExist 0;
BA_ "GenSigTimeoutValue" SG_ 773 SGU4_Object_wExist 0;
BA_ "Remark" SG_ 773 SGU4_Object_wExist "";
BA_ "EventCommandSignal" SG_ 773 SGU4_Object_wObstacle 0;
BA_ "GatewayedSignals" SG_ 773 SGU4_Object_wObstacle 0;
BA_ "GenSigInactiveValue" SG_ 773 SGU4_Object_wObstacle 0;
BA_ "GenSigInvalidValue" SG_ 773 SGU4_Object_wObstacle 0;
BA_ "GenSigSendType" SG_ 773 SGU4_Object_wObstacle 1;
BA_ "GenSigStartValue" SG_ 773 SGU4_Object_wObstacle 0;
BA_ "GenSigTimeoutValue" SG_ 773 SGU4_Object_wObstacle 0;
BA_ "Remark" SG_ 773 SGU4_Object_wObstacle "";
BA_ "EventCommandSignal" SG_ 774 SGU5_BlockCounter 0;
BA_ "GatewayedSignals" SG_ 774 SGU5_BlockCounter 0;
BA_ "GenSigInactiveValue" SG_ 774 SGU5_BlockCounter 0;
BA_ "GenSigInvalidValue" SG_ 774 SGU5_BlockCounter 0;
BA_ "GenSigSendType" SG_ 774 SGU5_BlockCounter 1;
BA_ "GenSigStartValue" SG_ 774 SGU5_BlockCounter 0;
BA_ "GenSigTimeoutValue" SG_ 774 SGU5_BlockCounter 0;
BA_ "Remark" SG_ 774 SGU5_BlockCounter "";
BA_ "EventCommandSignal" SG_ 774 SGU5_LifeCycles_OBJ 0;
BA_ "GatewayedSignals" SG_ 774 SGU5_LifeCycles_OBJ 0;
BA_ "GenSigInactiveValue" SG_ 774 SGU5_LifeCycles_OBJ 0;
BA_ "GenSigInvalidValue" SG_ 774 SGU5_LifeCycles_OBJ 0;
BA_ "GenSigSendType" SG_ 774 SGU5_LifeCycles_OBJ 1;
BA_ "GenSigStartValue" SG_ 774 SGU5_LifeCycles_OBJ 0;
BA_ "GenSigTimeoutValue" SG_ 774 SGU5_LifeCycles_OBJ 0;
BA_ "Remark" SG_ 774 SGU5_LifeCycles_OBJ "";
BA_ "EventCommandSignal" SG_ 774 SGU5_Msg_AliveCounter 0;
BA_ "GatewayedSignals" SG_ 774 SGU5_Msg_AliveCounter 0;
BA_ "GenSigInactiveValue" SG_ 774 SGU5_Msg_AliveCounter 0;
BA_ "GenSigInvalidValue" SG_ 774 SGU5_Msg_AliveCounter 0;
BA_ "GenSigSendType" SG_ 774 SGU5_Msg_AliveCounter 1;
BA_ "GenSigStartValue" SG_ 774 SGU5_Msg_AliveCounter 0;
BA_ "GenSigTimeoutValue" SG_ 774 SGU5_Msg_AliveCounter 0;
BA_ "Remark" SG_ 774 SGU5_Msg_AliveCounter "";
BA_ "EventCommandSignal" SG_ 774 SGU5_Msg_CheckSum 0;
BA_ "GatewayedSignals" SG_ 774 SGU5_Msg_CheckSum 0;
BA_ "GenSigInactiveValue" SG_ 774 SGU5_Msg_CheckSum 0;
BA_ "GenSigInvalidValue" SG_ 774 SGU5_Msg_CheckSum 0;
BA_ "GenSigSendType" SG_ 774 SGU5_Msg_CheckSum 1;
BA_ "GenSigStartValue" SG_ 774 SGU5_Msg_CheckSum 0;
BA_ "GenSigTimeoutValue" SG_ 774 SGU5_Msg_CheckSum 0;
BA_ "Remark" SG_ 774 SGU5_Msg_CheckSum "";
BA_ "EventCommandSignal" SG_ 774 SGU5_ObjRCS_05 0;
BA_ "GatewayedSignals" SG_ 774 SGU5_ObjRCS_05 0;
BA_ "GenSigInactiveValue" SG_ 774 SGU5_ObjRCS_05 0;
BA_ "GenSigInvalidValue" SG_ 774 SGU5_ObjRCS_05 0;
BA_ "GenSigSendType" SG_ 774 SGU5_ObjRCS_05 1;
BA_ "GenSigStartValue" SG_ 774 SGU5_ObjRCS_05 0;
BA_ "GenSigTimeoutValue" SG_ 774 SGU5_ObjRCS_05 0;
BA_ "Remark" SG_ 774 SGU5_ObjRCS_05 "";
BA_ "EventCommandSignal" SG_ 774 SGU5_Obj_DistLat_rms 0;
BA_ "GatewayedSignals" SG_ 774 SGU5_Obj_DistLat_rms 0;
BA_ "GenSigInactiveValue" SG_ 774 SGU5_Obj_DistLat_rms 0;
BA_ "GenSigInvalidValue" SG_ 774 SGU5_Obj_DistLat_rms 0;
BA_ "GenSigSendType" SG_ 774 SGU5_Obj_DistLat_rms 1;
BA_ "GenSigStartValue" SG_ 774 SGU5_Obj_DistLat_rms 0;
BA_ "GenSigTimeoutValue" SG_ 774 SGU5_Obj_DistLat_rms 0;
BA_ "Remark" SG_ 774 SGU5_Obj_DistLat_rms "";
BA_ "EventCommandSignal" SG_ 774 SGU5_Obj_VrelLong_rms 0;
BA_ "GatewayedSignals" SG_ 774 SGU5_Obj_VrelLong_rms 0;
BA_ "GenSigInactiveValue" SG_ 774 SGU5_Obj_VrelLong_rms 0;
BA_ "GenSigInvalidValue" SG_ 774 SGU5_Obj_VrelLong_rms 0;
BA_ "GenSigSendType" SG_ 774 SGU5_Obj_VrelLong_rms 1;
BA_ "GenSigStartValue" SG_ 774 SGU5_Obj_VrelLong_rms 0;
BA_ "GenSigTimeoutValue" SG_ 774 SGU5_Obj_VrelLong_rms 0;
BA_ "Remark" SG_ 774 SGU5_Obj_VrelLong_rms "";
BA_ "EventCommandSignal" SG_ 774 SGU5_Obj_Vrelat_rms 0;
BA_ "GatewayedSignals" SG_ 774 SGU5_Obj_Vrelat_rms 0;
BA_ "GenSigInactiveValue" SG_ 774 SGU5_Obj_Vrelat_rms 0;
BA_ "GenSigInvalidValue" SG_ 774 SGU5_Obj_Vrelat_rms 0;
BA_ "GenSigSendType" SG_ 774 SGU5_Obj_Vrelat_rms 1;
BA_ "GenSigStartValue" SG_ 774 SGU5_Obj_Vrelat_rms 0;
BA_ "GenSigTimeoutValue" SG_ 774 SGU5_Obj_Vrelat_rms 0;
BA_ "Remark" SG_ 774 SGU5_Obj_Vrelat_rms "";
BA_ "EventCommandSignal" SG_ 774 SGU5_Object_DetStatus 0;
BA_ "GatewayedSignals" SG_ 774 SGU5_Object_DetStatus 0;
BA_ "GenSigInactiveValue" SG_ 774 SGU5_Object_DetStatus 0;
BA_ "GenSigInvalidValue" SG_ 774 SGU5_Object_DetStatus 0;
BA_ "GenSigSendType" SG_ 774 SGU5_Object_DetStatus 1;
BA_ "GenSigStartValue" SG_ 774 SGU5_Object_DetStatus 0;
BA_ "GenSigTimeoutValue" SG_ 774 SGU5_Object_DetStatus 0;
BA_ "Remark" SG_ 774 SGU5_Object_DetStatus "";
BA_ "EventCommandSignal" SG_ 774 SGU5_Object_DistLong_rms 0;
BA_ "GatewayedSignals" SG_ 774 SGU5_Object_DistLong_rms 0;
BA_ "GenSigInactiveValue" SG_ 774 SGU5_Object_DistLong_rms 0;
BA_ "GenSigInvalidValue" SG_ 774 SGU5_Object_DistLong_rms 0;
BA_ "GenSigSendType" SG_ 774 SGU5_Object_DistLong_rms 1;
BA_ "GenSigStartValue" SG_ 774 SGU5_Object_DistLong_rms 0;
BA_ "GenSigTimeoutValue" SG_ 774 SGU5_Object_DistLong_rms 0;
BA_ "Remark" SG_ 774 SGU5_Object_DistLong_rms "";
BA_ "EventCommandSignal" SG_ 774 SGU5_Object_ID 0;
BA_ "GatewayedSignals" SG_ 774 SGU5_Object_ID 0;
BA_ "GenSigInactiveValue" SG_ 774 SGU5_Object_ID 0;
BA_ "GenSigInvalidValue" SG_ 774 SGU5_Object_ID 0;
BA_ "GenSigSendType" SG_ 774 SGU5_Object_ID 1;
BA_ "GenSigStartValue" SG_ 774 SGU5_Object_ID 0;
BA_ "GenSigTimeoutValue" SG_ 774 SGU5_Object_ID 0;
BA_ "Remark" SG_ 774 SGU5_Object_ID "";
BA_ "EventCommandSignal" SG_ 774 SGU5_Object_Motion_Pattern 0;
BA_ "GatewayedSignals" SG_ 774 SGU5_Object_Motion_Pattern 0;
BA_ "GenSigInactiveValue" SG_ 774 SGU5_Object_Motion_Pattern 0;
BA_ "GenSigInvalidValue" SG_ 774 SGU5_Object_Motion_Pattern 0;
BA_ "GenSigSendType" SG_ 774 SGU5_Object_Motion_Pattern 1;
BA_ "GenSigStartValue" SG_ 774 SGU5_Object_Motion_Pattern 0;
BA_ "GenSigTimeoutValue" SG_ 774 SGU5_Object_Motion_Pattern 0;
BA_ "Remark" SG_ 774 SGU5_Object_Motion_Pattern "";
BA_ "EventCommandSignal" SG_ 774 SGU5_Object_Type 0;
BA_ "GatewayedSignals" SG_ 774 SGU5_Object_Type 0;
BA_ "GenSigInactiveValue" SG_ 774 SGU5_Object_Type 0;
BA_ "GenSigInvalidValue" SG_ 774 SGU5_Object_Type 0;
BA_ "GenSigSendType" SG_ 774 SGU5_Object_Type 1;
BA_ "GenSigStartValue" SG_ 774 SGU5_Object_Type 0;
BA_ "GenSigTimeoutValue" SG_ 774 SGU5_Object_Type 0;
BA_ "Remark" SG_ 774 SGU5_Object_Type "";
BA_ "EventCommandSignal" SG_ 774 SGU5_Object_ax 0;
BA_ "GatewayedSignals" SG_ 774 SGU5_Object_ax 0;
BA_ "GenSigInactiveValue" SG_ 774 SGU5_Object_ax 0;
BA_ "GenSigInvalidValue" SG_ 774 SGU5_Object_ax 0;
BA_ "GenSigSendType" SG_ 774 SGU5_Object_ax 1;
BA_ "GenSigStartValue" SG_ 774 SGU5_Object_ax 0;
BA_ "GenSigTimeoutValue" SG_ 774 SGU5_Object_ax 0;
BA_ "Remark" SG_ 774 SGU5_Object_ax "";
BA_ "EventCommandSignal" SG_ 774 SGU5_Object_ay 0;
BA_ "GatewayedSignals" SG_ 774 SGU5_Object_ay 0;
BA_ "GenSigInactiveValue" SG_ 774 SGU5_Object_ay 0;
BA_ "GenSigInvalidValue" SG_ 774 SGU5_Object_ay 0;
BA_ "GenSigSendType" SG_ 774 SGU5_Object_ay 1;
BA_ "GenSigStartValue" SG_ 774 SGU5_Object_ay 0;
BA_ "GenSigTimeoutValue" SG_ 774 SGU5_Object_ay 0;
BA_ "Remark" SG_ 774 SGU5_Object_ay "";
BA_ "EventCommandSignal" SG_ 774 SGU5_Object_dx 0;
BA_ "GatewayedSignals" SG_ 774 SGU5_Object_dx 0;
BA_ "GenSigInactiveValue" SG_ 774 SGU5_Object_dx 0;
BA_ "GenSigInvalidValue" SG_ 774 SGU5_Object_dx 0;
BA_ "GenSigSendType" SG_ 774 SGU5_Object_dx 1;
BA_ "GenSigStartValue" SG_ 774 SGU5_Object_dx 0;
BA_ "GenSigTimeoutValue" SG_ 774 SGU5_Object_dx 0;
BA_ "Remark" SG_ 774 SGU5_Object_dx "";
BA_ "EventCommandSignal" SG_ 774 SGU5_Object_dx_Rear 0;
BA_ "GatewayedSignals" SG_ 774 SGU5_Object_dx_Rear 0;
BA_ "GenSigInactiveValue" SG_ 774 SGU5_Object_dx_Rear 0;
BA_ "GenSigInvalidValue" SG_ 774 SGU5_Object_dx_Rear 0;
BA_ "GenSigSendType" SG_ 774 SGU5_Object_dx_Rear 1;
BA_ "GenSigStartValue" SG_ 774 SGU5_Object_dx_Rear 0;
BA_ "GenSigTimeoutValue" SG_ 774 SGU5_Object_dx_Rear 0;
BA_ "Remark" SG_ 774 SGU5_Object_dx_Rear "";
BA_ "EventCommandSignal" SG_ 774 SGU5_Object_dy 0;
BA_ "GatewayedSignals" SG_ 774 SGU5_Object_dy 0;
BA_ "GenSigInactiveValue" SG_ 774 SGU5_Object_dy 0;
BA_ "GenSigInvalidValue" SG_ 774 SGU5_Object_dy 0;
BA_ "GenSigSendType" SG_ 774 SGU5_Object_dy 1;
BA_ "GenSigStartValue" SG_ 774 SGU5_Object_dy 0;
BA_ "GenSigTimeoutValue" SG_ 774 SGU5_Object_dy 0;
BA_ "Remark" SG_ 774 SGU5_Object_dy "";
BA_ "EventCommandSignal" SG_ 774 SGU5_Object_dy_Rear 0;
BA_ "GatewayedSignals" SG_ 774 SGU5_Object_dy_Rear 0;
BA_ "GenSigInactiveValue" SG_ 774 SGU5_Object_dy_Rear 0;
BA_ "GenSigInvalidValue" SG_ 774 SGU5_Object_dy_Rear 0;
BA_ "GenSigSendType" SG_ 774 SGU5_Object_dy_Rear 1;
BA_ "GenSigStartValue" SG_ 774 SGU5_Object_dy_Rear 0;
BA_ "GenSigTimeoutValue" SG_ 774 SGU5_Object_dy_Rear 0;
BA_ "Remark" SG_ 774 SGU5_Object_dy_Rear "";
BA_ "EventCommandSignal" SG_ 774 SGU5_Object_vx 0;
BA_ "GatewayedSignals" SG_ 774 SGU5_Object_vx 0;
BA_ "GenSigInactiveValue" SG_ 774 SGU5_Object_vx 0;
BA_ "GenSigInvalidValue" SG_ 774 SGU5_Object_vx 0;
BA_ "GenSigSendType" SG_ 774 SGU5_Object_vx 1;
BA_ "GenSigStartValue" SG_ 774 SGU5_Object_vx 0;
BA_ "GenSigTimeoutValue" SG_ 774 SGU5_Object_vx 0;
BA_ "Remark" SG_ 774 SGU5_Object_vx "";
BA_ "EventCommandSignal" SG_ 774 SGU5_Object_vy 0;
BA_ "GatewayedSignals" SG_ 774 SGU5_Object_vy 0;
BA_ "GenSigInactiveValue" SG_ 774 SGU5_Object_vy 0;
BA_ "GenSigInvalidValue" SG_ 774 SGU5_Object_vy 0;
BA_ "GenSigSendType" SG_ 774 SGU5_Object_vy 1;
BA_ "GenSigStartValue" SG_ 774 SGU5_Object_vy 0;
BA_ "GenSigTimeoutValue" SG_ 774 SGU5_Object_vy 0;
BA_ "Remark" SG_ 774 SGU5_Object_vy "";
BA_ "EventCommandSignal" SG_ 774 SGU5_Object_wExist 0;
BA_ "GatewayedSignals" SG_ 774 SGU5_Object_wExist 0;
BA_ "GenSigInactiveValue" SG_ 774 SGU5_Object_wExist 0;
BA_ "GenSigInvalidValue" SG_ 774 SGU5_Object_wExist 0;
BA_ "GenSigSendType" SG_ 774 SGU5_Object_wExist 1;
BA_ "GenSigStartValue" SG_ 774 SGU5_Object_wExist 0;
BA_ "GenSigTimeoutValue" SG_ 774 SGU5_Object_wExist 0;
BA_ "Remark" SG_ 774 SGU5_Object_wExist "";
BA_ "EventCommandSignal" SG_ 774 SGU5_Object_wObstacle 0;
BA_ "GatewayedSignals" SG_ 774 SGU5_Object_wObstacle 0;
BA_ "GenSigInactiveValue" SG_ 774 SGU5_Object_wObstacle 0;
BA_ "GenSigInvalidValue" SG_ 774 SGU5_Object_wObstacle 0;
BA_ "GenSigSendType" SG_ 774 SGU5_Object_wObstacle 1;
BA_ "GenSigStartValue" SG_ 774 SGU5_Object_wObstacle 0;
BA_ "GenSigTimeoutValue" SG_ 774 SGU5_Object_wObstacle 0;
BA_ "Remark" SG_ 774 SGU5_Object_wObstacle "";
BA_ "EventCommandSignal" SG_ 775 SGU6_BlockCounter 0;
BA_ "GatewayedSignals" SG_ 775 SGU6_BlockCounter 0;
BA_ "GenSigInactiveValue" SG_ 775 SGU6_BlockCounter 0;
BA_ "GenSigInvalidValue" SG_ 775 SGU6_BlockCounter 0;
BA_ "GenSigSendType" SG_ 775 SGU6_BlockCounter 1;
BA_ "GenSigStartValue" SG_ 775 SGU6_BlockCounter 0;
BA_ "GenSigTimeoutValue" SG_ 775 SGU6_BlockCounter 0;
BA_ "Remark" SG_ 775 SGU6_BlockCounter "";
BA_ "EventCommandSignal" SG_ 775 SGU6_LifeCycles_OBJ 0;
BA_ "GatewayedSignals" SG_ 775 SGU6_LifeCycles_OBJ 0;
BA_ "GenSigInactiveValue" SG_ 775 SGU6_LifeCycles_OBJ 0;
BA_ "GenSigInvalidValue" SG_ 775 SGU6_LifeCycles_OBJ 0;
BA_ "GenSigSendType" SG_ 775 SGU6_LifeCycles_OBJ 1;
BA_ "GenSigStartValue" SG_ 775 SGU6_LifeCycles_OBJ 0;
BA_ "GenSigTimeoutValue" SG_ 775 SGU6_LifeCycles_OBJ 0;
BA_ "Remark" SG_ 775 SGU6_LifeCycles_OBJ "";
BA_ "EventCommandSignal" SG_ 775 SGU6_Msg_AliveCounter 0;
BA_ "GatewayedSignals" SG_ 775 SGU6_Msg_AliveCounter 0;
BA_ "GenSigInactiveValue" SG_ 775 SGU6_Msg_AliveCounter 0;
BA_ "GenSigInvalidValue" SG_ 775 SGU6_Msg_AliveCounter 0;
BA_ "GenSigSendType" SG_ 775 SGU6_Msg_AliveCounter 1;
BA_ "GenSigStartValue" SG_ 775 SGU6_Msg_AliveCounter 0;
BA_ "GenSigTimeoutValue" SG_ 775 SGU6_Msg_AliveCounter 0;
BA_ "Remark" SG_ 775 SGU6_Msg_AliveCounter "";
BA_ "EventCommandSignal" SG_ 775 SGU6_Msg_CheckSum 0;
BA_ "GatewayedSignals" SG_ 775 SGU6_Msg_CheckSum 0;
BA_ "GenSigInactiveValue" SG_ 775 SGU6_Msg_CheckSum 0;
BA_ "GenSigInvalidValue" SG_ 775 SGU6_Msg_CheckSum 0;
BA_ "GenSigSendType" SG_ 775 SGU6_Msg_CheckSum 1;
BA_ "GenSigStartValue" SG_ 775 SGU6_Msg_CheckSum 0;
BA_ "GenSigTimeoutValue" SG_ 775 SGU6_Msg_CheckSum 0;
BA_ "Remark" SG_ 775 SGU6_Msg_CheckSum "";
BA_ "EventCommandSignal" SG_ 775 SGU6_ObjRCS_06 0;
BA_ "GatewayedSignals" SG_ 775 SGU6_ObjRCS_06 0;
BA_ "GenSigInactiveValue" SG_ 775 SGU6_ObjRCS_06 0;
BA_ "GenSigInvalidValue" SG_ 775 SGU6_ObjRCS_06 0;
BA_ "GenSigSendType" SG_ 775 SGU6_ObjRCS_06 1;
BA_ "GenSigStartValue" SG_ 775 SGU6_ObjRCS_06 0;
BA_ "GenSigTimeoutValue" SG_ 775 SGU6_ObjRCS_06 0;
BA_ "Remark" SG_ 775 SGU6_ObjRCS_06 "";
BA_ "EventCommandSignal" SG_ 775 SGU6_Obj_DistLat_rms 0;
BA_ "GatewayedSignals" SG_ 775 SGU6_Obj_DistLat_rms 0;
BA_ "GenSigInactiveValue" SG_ 775 SGU6_Obj_DistLat_rms 0;
BA_ "GenSigInvalidValue" SG_ 775 SGU6_Obj_DistLat_rms 0;
BA_ "GenSigSendType" SG_ 775 SGU6_Obj_DistLat_rms 1;
BA_ "GenSigStartValue" SG_ 775 SGU6_Obj_DistLat_rms 0;
BA_ "GenSigTimeoutValue" SG_ 775 SGU6_Obj_DistLat_rms 0;
BA_ "Remark" SG_ 775 SGU6_Obj_DistLat_rms "";
BA_ "EventCommandSignal" SG_ 775 SGU6_Obj_VrelLong_rms 0;
BA_ "GatewayedSignals" SG_ 775 SGU6_Obj_VrelLong_rms 0;
BA_ "GenSigInactiveValue" SG_ 775 SGU6_Obj_VrelLong_rms 0;
BA_ "GenSigInvalidValue" SG_ 775 SGU6_Obj_VrelLong_rms 0;
BA_ "GenSigSendType" SG_ 775 SGU6_Obj_VrelLong_rms 1;
BA_ "GenSigStartValue" SG_ 775 SGU6_Obj_VrelLong_rms 0;
BA_ "GenSigTimeoutValue" SG_ 775 SGU6_Obj_VrelLong_rms 0;
BA_ "Remark" SG_ 775 SGU6_Obj_VrelLong_rms "";
BA_ "EventCommandSignal" SG_ 775 SGU6_Obj_Vrelat_rms 0;
BA_ "GatewayedSignals" SG_ 775 SGU6_Obj_Vrelat_rms 0;
BA_ "GenSigInactiveValue" SG_ 775 SGU6_Obj_Vrelat_rms 0;
BA_ "GenSigInvalidValue" SG_ 775 SGU6_Obj_Vrelat_rms 0;
BA_ "GenSigSendType" SG_ 775 SGU6_Obj_Vrelat_rms 1;
BA_ "GenSigStartValue" SG_ 775 SGU6_Obj_Vrelat_rms 0;
BA_ "GenSigTimeoutValue" SG_ 775 SGU6_Obj_Vrelat_rms 0;
BA_ "Remark" SG_ 775 SGU6_Obj_Vrelat_rms "";
BA_ "EventCommandSignal" SG_ 775 SGU6_Object_DetStatus 0;
BA_ "GatewayedSignals" SG_ 775 SGU6_Object_DetStatus 0;
BA_ "GenSigInactiveValue" SG_ 775 SGU6_Object_DetStatus 0;
BA_ "GenSigInvalidValue" SG_ 775 SGU6_Object_DetStatus 0;
BA_ "GenSigSendType" SG_ 775 SGU6_Object_DetStatus 1;
BA_ "GenSigStartValue" SG_ 775 SGU6_Object_DetStatus 0;
BA_ "GenSigTimeoutValue" SG_ 775 SGU6_Object_DetStatus 0;
BA_ "Remark" SG_ 775 SGU6_Object_DetStatus "";
BA_ "EventCommandSignal" SG_ 775 SGU6_Object_DistLong_rms 0;
BA_ "GatewayedSignals" SG_ 775 SGU6_Object_DistLong_rms 0;
BA_ "GenSigInactiveValue" SG_ 775 SGU6_Object_DistLong_rms 0;
BA_ "GenSigInvalidValue" SG_ 775 SGU6_Object_DistLong_rms 0;
BA_ "GenSigSendType" SG_ 775 SGU6_Object_DistLong_rms 1;
BA_ "GenSigStartValue" SG_ 775 SGU6_Object_DistLong_rms 0;
BA_ "GenSigTimeoutValue" SG_ 775 SGU6_Object_DistLong_rms 0;
BA_ "Remark" SG_ 775 SGU6_Object_DistLong_rms "";
BA_ "EventCommandSignal" SG_ 775 SGU6_Object_ID 0;
BA_ "GatewayedSignals" SG_ 775 SGU6_Object_ID 0;
BA_ "GenSigInactiveValue" SG_ 775 SGU6_Object_ID 0;
BA_ "GenSigInvalidValue" SG_ 775 SGU6_Object_ID 0;
BA_ "GenSigSendType" SG_ 775 SGU6_Object_ID 1;
BA_ "GenSigStartValue" SG_ 775 SGU6_Object_ID 0;
BA_ "GenSigTimeoutValue" SG_ 775 SGU6_Object_ID 0;
BA_ "Remark" SG_ 775 SGU6_Object_ID "";
BA_ "EventCommandSignal" SG_ 775 SGU6_Object_Motion_Pattern 0;
BA_ "GatewayedSignals" SG_ 775 SGU6_Object_Motion_Pattern 0;
BA_ "GenSigInactiveValue" SG_ 775 SGU6_Object_Motion_Pattern 0;
BA_ "GenSigInvalidValue" SG_ 775 SGU6_Object_Motion_Pattern 0;
BA_ "GenSigSendType" SG_ 775 SGU6_Object_Motion_Pattern 1;
BA_ "GenSigStartValue" SG_ 775 SGU6_Object_Motion_Pattern 0;
BA_ "GenSigTimeoutValue" SG_ 775 SGU6_Object_Motion_Pattern 0;
BA_ "Remark" SG_ 775 SGU6_Object_Motion_Pattern "";
BA_ "EventCommandSignal" SG_ 775 SGU6_Object_Type 0;
BA_ "GatewayedSignals" SG_ 775 SGU6_Object_Type 0;
BA_ "GenSigInactiveValue" SG_ 775 SGU6_Object_Type 0;
BA_ "GenSigInvalidValue" SG_ 775 SGU6_Object_Type 0;
BA_ "GenSigSendType" SG_ 775 SGU6_Object_Type 1;
BA_ "GenSigStartValue" SG_ 775 SGU6_Object_Type 0;
BA_ "GenSigTimeoutValue" SG_ 775 SGU6_Object_Type 0;
BA_ "Remark" SG_ 775 SGU6_Object_Type "";
BA_ "EventCommandSignal" SG_ 775 SGU6_Object_ax 0;
BA_ "GatewayedSignals" SG_ 775 SGU6_Object_ax 0;
BA_ "GenSigInactiveValue" SG_ 775 SGU6_Object_ax 0;
BA_ "GenSigInvalidValue" SG_ 775 SGU6_Object_ax 0;
BA_ "GenSigSendType" SG_ 775 SGU6_Object_ax 1;
BA_ "GenSigStartValue" SG_ 775 SGU6_Object_ax 0;
BA_ "GenSigTimeoutValue" SG_ 775 SGU6_Object_ax 0;
BA_ "Remark" SG_ 775 SGU6_Object_ax "";
BA_ "EventCommandSignal" SG_ 775 SGU6_Object_ay 0;
BA_ "GatewayedSignals" SG_ 775 SGU6_Object_ay 0;
BA_ "GenSigInactiveValue" SG_ 775 SGU6_Object_ay 0;
BA_ "GenSigInvalidValue" SG_ 775 SGU6_Object_ay 0;
BA_ "GenSigSendType" SG_ 775 SGU6_Object_ay 1;
BA_ "GenSigStartValue" SG_ 775 SGU6_Object_ay 0;
BA_ "GenSigTimeoutValue" SG_ 775 SGU6_Object_ay 0;
BA_ "Remark" SG_ 775 SGU6_Object_ay "";
BA_ "EventCommandSignal" SG_ 775 SGU6_Object_dx 0;
BA_ "GatewayedSignals" SG_ 775 SGU6_Object_dx 0;
BA_ "GenSigInactiveValue" SG_ 775 SGU6_Object_dx 0;
BA_ "GenSigInvalidValue" SG_ 775 SGU6_Object_dx 0;
BA_ "GenSigSendType" SG_ 775 SGU6_Object_dx 1;
BA_ "GenSigStartValue" SG_ 775 SGU6_Object_dx 0;
BA_ "GenSigTimeoutValue" SG_ 775 SGU6_Object_dx 0;
BA_ "Remark" SG_ 775 SGU6_Object_dx "";
BA_ "EventCommandSignal" SG_ 775 SGU6_Object_dx_Rear 0;
BA_ "GatewayedSignals" SG_ 775 SGU6_Object_dx_Rear 0;
BA_ "GenSigInactiveValue" SG_ 775 SGU6_Object_dx_Rear 0;
BA_ "GenSigInvalidValue" SG_ 775 SGU6_Object_dx_Rear 0;
BA_ "GenSigSendType" SG_ 775 SGU6_Object_dx_Rear 1;
BA_ "GenSigStartValue" SG_ 775 SGU6_Object_dx_Rear 0;
BA_ "GenSigTimeoutValue" SG_ 775 SGU6_Object_dx_Rear 0;
BA_ "Remark" SG_ 775 SGU6_Object_dx_Rear "";
BA_ "EventCommandSignal" SG_ 775 SGU6_Object_dy 0;
BA_ "GatewayedSignals" SG_ 775 SGU6_Object_dy 0;
BA_ "GenSigInactiveValue" SG_ 775 SGU6_Object_dy 0;
BA_ "GenSigInvalidValue" SG_ 775 SGU6_Object_dy 0;
BA_ "GenSigSendType" SG_ 775 SGU6_Object_dy 1;
BA_ "GenSigStartValue" SG_ 775 SGU6_Object_dy 0;
BA_ "GenSigTimeoutValue" SG_ 775 SGU6_Object_dy 0;
BA_ "Remark" SG_ 775 SGU6_Object_dy "";
BA_ "EventCommandSignal" SG_ 775 SGU6_Object_dy_Rear 0;
BA_ "GatewayedSignals" SG_ 775 SGU6_Object_dy_Rear 0;
BA_ "GenSigInactiveValue" SG_ 775 SGU6_Object_dy_Rear 0;
BA_ "GenSigInvalidValue" SG_ 775 SGU6_Object_dy_Rear 0;
BA_ "GenSigSendType" SG_ 775 SGU6_Object_dy_Rear 1;
BA_ "GenSigStartValue" SG_ 775 SGU6_Object_dy_Rear 0;
BA_ "GenSigTimeoutValue" SG_ 775 SGU6_Object_dy_Rear 0;
BA_ "Remark" SG_ 775 SGU6_Object_dy_Rear "";
BA_ "EventCommandSignal" SG_ 775 SGU6_Object_vx 0;
BA_ "GatewayedSignals" SG_ 775 SGU6_Object_vx 0;
BA_ "GenSigInactiveValue" SG_ 775 SGU6_Object_vx 0;
BA_ "GenSigInvalidValue" SG_ 775 SGU6_Object_vx 0;
BA_ "GenSigSendType" SG_ 775 SGU6_Object_vx 1;
BA_ "GenSigStartValue" SG_ 775 SGU6_Object_vx 0;
BA_ "GenSigTimeoutValue" SG_ 775 SGU6_Object_vx 0;
BA_ "Remark" SG_ 775 SGU6_Object_vx "";
BA_ "EventCommandSignal" SG_ 775 SGU6_Object_vy 0;
BA_ "GatewayedSignals" SG_ 775 SGU6_Object_vy 0;
BA_ "GenSigInactiveValue" SG_ 775 SGU6_Object_vy 0;
BA_ "GenSigInvalidValue" SG_ 775 SGU6_Object_vy 0;
BA_ "GenSigSendType" SG_ 775 SGU6_Object_vy 1;
BA_ "GenSigStartValue" SG_ 775 SGU6_Object_vy 0;
BA_ "GenSigTimeoutValue" SG_ 775 SGU6_Object_vy 0;
BA_ "Remark" SG_ 775 SGU6_Object_vy "";
BA_ "EventCommandSignal" SG_ 775 SGU6_Object_wExist 0;
BA_ "GatewayedSignals" SG_ 775 SGU6_Object_wExist 0;
BA_ "GenSigInactiveValue" SG_ 775 SGU6_Object_wExist 0;
BA_ "GenSigInvalidValue" SG_ 775 SGU6_Object_wExist 0;
BA_ "GenSigSendType" SG_ 775 SGU6_Object_wExist 1;
BA_ "GenSigStartValue" SG_ 775 SGU6_Object_wExist 0;
BA_ "GenSigTimeoutValue" SG_ 775 SGU6_Object_wExist 0;
BA_ "Remark" SG_ 775 SGU6_Object_wExist "";
BA_ "EventCommandSignal" SG_ 775 SGU6_Object_wObstacle 0;
BA_ "GatewayedSignals" SG_ 775 SGU6_Object_wObstacle 0;
BA_ "GenSigInactiveValue" SG_ 775 SGU6_Object_wObstacle 0;
BA_ "GenSigInvalidValue" SG_ 775 SGU6_Object_wObstacle 0;
BA_ "GenSigSendType" SG_ 775 SGU6_Object_wObstacle 1;
BA_ "GenSigStartValue" SG_ 775 SGU6_Object_wObstacle 0;
BA_ "GenSigTimeoutValue" SG_ 775 SGU6_Object_wObstacle 0;
BA_ "Remark" SG_ 775 SGU6_Object_wObstacle "";
BA_ "GenMsgILSupport" BO_ 768 0;
BA_ "MsgType" BO_ 541 0;
BA_ "MsgType" BO_ 542 0;
BA_ "MsgType" BO_ 543 0;
BA_ "MsgType" BO_ 544 0;
BA_ "MsgType" BO_ 545 0;
BA_ "MsgType" BO_ 546 0;
BA_ "MsgType" BO_ 616 0;
BA_ "MsgType" BO_ 768 0;
BA_ "MsgType" BO_ 769 0;
BA_ "MsgType" BO_ 770 0;
BA_ "MsgType" BO_ 771 0;
BA_ "MsgType" BO_ 772 0;
BA_ "MsgType" BO_ 773 0;
BA_ "MsgType" BO_ 774 0;
BA_ "MsgType" BO_ 775 0;
BA_ "IsCrcSignal" SG_ 541 SGU28_Msg_CheckSum 1;
BA_ "IsCrcSignal" SG_ 542 SGU29_Msg_CheckSum 1;
BA_ "IsCrcSignal" SG_ 543 SGU30_Msg_CheckSum 1;
BA_ "IsCrcSignal" SG_ 544 SGU31_Msg_CheckSum 1;
BA_ "IsCrcSignal" SG_ 545 SGU32_Msg_CheckSum 1;
BA_ "SystemSignalLongSymbol" SG_ 546 FLR_DTC_RADAR_OVER_TEMPERATURE "FR_DTC_RADAR_OVER_TEMPERATURE_Can03";
BA_ "SystemSignalLongSymbol" SG_ 546 FLR_DTC_VARIANT_SELECTION_NOT_DONE "FR_DTC_VARIANT_SELECTION_NOT_DONE_Can03";
BA_ "IsCrcSignal" SG_ 546 FLR_RadarInfor_Checksum 1;
BA_ "IsCrcSignal" SG_ 769 FRR_Msg_CheckSum 1;
BA_ "IsCrcSignal" SG_ 770 SGU1_Msg_CheckSum 1;
BA_ "IsCrcSignal" SG_ 771 SGU2_Msg_CheckSum 1;
BA_ "IsCrcSignal" SG_ 772 SGU3_Msg_CheckSum 1;
BA_ "IsCrcSignal" SG_ 773 SGU4_Msg_CheckSum 1;
BA_ "IsCrcSignal" SG_ 774 SGU5_Msg_CheckSum 1;
BA_ "IsCrcSignal" SG_ 775 SGU6_Msg_CheckSum 1;
VAL_ 541 SGU28_Object_DetStatus 0 "deleted" 1 "new" 2 "measured" 3 "predicted" 4 "deleted for merge" 5 "new from  merge"  ;
VAL_ 541 SGU28_Object_Motion_Pattern 0 "Unknown" 1 "Stationary" 2 "Stopped" 3 "Moving"  ;
VAL_ 541 SGU28_Object_Type 0 "Unknown" 1 "4 wheeler" 2 "2 wheeler" 3 "Pedestrian"  ;
VAL_ 542 SGU29_Object_DetStatus 0 "deleted" 1 "new" 2 "measured" 3 "predicted" 4 "deleted for merge" 5 "new from  merge"  ;
VAL_ 542 SGU29_Object_Motion_Pattern 0 "Unknown" 1 "Stationary" 2 "Stopped" 3 "Moving"  ;
VAL_ 542 SGU29_Object_Type 0 "Unknown" 1 "4 wheeler" 2 "2 wheeler" 3 "Pedestrian"  ;
VAL_ 543 SGU30_Object_DetStatus 0 "deleted" 1 "new" 2 "measured" 3 "predicted" 4 "deleted for merge" 5 "new from  merge"  ;
VAL_ 543 SGU30_Object_Motion_Pattern 0 "Unknown" 1 "Stationary" 2 "Stopped" 3 "Moving"  ;
VAL_ 543 SGU30_Object_Type 0 "Unknown" 1 "4 wheeler" 2 "2 wheeler" 3 "Pedestrian"  ;
VAL_ 544 SGU31_Object_DetStatus 0 "deleted" 1 "new" 2 "measured" 3 "predicted" 4 "deleted for merge" 5 "new from  merge"  ;
VAL_ 544 SGU31_Object_Motion_Pattern 0 "Unknown" 1 "Stationary" 2 "Stopped" 3 "Moving"  ;
VAL_ 544 SGU31_Object_Type 0 "Unknown" 1 "4 wheeler" 2 "2 wheeler" 3 "Pedestrian"  ;
VAL_ 545 SGU32_Object_DetStatus 0 "deleted" 1 "new" 2 "measured" 3 "predicted" 4 "deleted for merge" 5 "new from  merge"  ;
VAL_ 545 SGU32_Object_Motion_Pattern 0 "Unknown" 1 "Stationary" 2 "Stopped" 3 "Moving"  ;
VAL_ 545 SGU32_Object_Type 0 "Unknown" 1 "4 wheeler" 2 "2 wheeler" 3 "Pedestrian"  ;
VAL_ 546 FLR_Blindness_FaultSts 0 "No Blindness" 1 "Blindness"  ;
VAL_ 546 FLR_DTC_ALIGNMENT_NOT_DONE 0 "No Fail" 1 "Fail"  ;
VAL_ 546 FLR_DTC_CORNER_RADAR_BLIND 0 "No Fail" 1 "Fail"  ;
VAL_ 546 FLR_DTC_CORNER_RADAR_MISALIGNED 0 "No Fail" 1 "Fail"  ;
VAL_ 546 FLR_DTC_DACORE_OOS 0 "No Fail" 1 "Fail"  ;
VAL_ 546 FLR_DTC_DSP_FAILURE 0 "No Fail" 1 "Fail"  ;
VAL_ 546 FLR_DTC_HARDWARE_FAILURE 0 "No Fail" 1 "Fail"  ;
VAL_ 546 FLR_DTC_INVALID_DATA_BCS 0 "No Fail" 1 "Fail"  ;
VAL_ 546 FLR_DTC_INVALID_DATA_EPS 0 "No Fail" 1 "Fail"  ;
VAL_ 546 FLR_DTC_INVALID_DATA_SOC 0 "No Fail" 1 "Fail"  ;
VAL_ 546 FLR_DTC_LOST_COMM_BCS 0 "No Fail" 1 "Fail"  ;
VAL_ 546 FLR_DTC_LOST_COMM_EPS 0 "No Fail" 1 "Fail"  ;
VAL_ 546 FLR_DTC_LOST_COMM_SOC 0 "No Fail" 1 "Fail"  ;
VAL_ 546 FLR_DTC_PUBLIC_CAN_BUSOFF 0 "No Fail" 1 "Fail"  ;
VAL_ 546 FLR_DTC_RADAR_OVER_TEMPERATURE 0 "No Fail" 1 "Fail"  ;
VAL_ 546 FLR_DTC_RADAR_SIDE_MISMATCH 0 "No Fail" 1 "Fail"  ;
VAL_ 546 FLR_DTC_SOC_Time_SYNC_FAIL 0 "No Fail" 1 "Fail"  ;
VAL_ 546 FLR_DTC_VARIANT_SELECTION_NOT_DONE 0 "No Fail" 1 "Fail"  ;
VAL_ 546 FLR_DTC_VBAT_HIGH 0 "No Fail" 1 "Fail"  ;
VAL_ 546 FLR_DTC_VBAT_LOW 0 "No Fail" 1 "Fail"  ;
VAL_ 546 FLR_EOL_CalibrationSts 0 "successfully calibrated" 1 "time out" 2 "target is missing" 3 "target distance is not correct" 4 "Horizontal bad angle" 5 "Vertical bad angle" 6 "NVM error" 7 "Cancelled by user" 255 "Not done calibration"  ;
VAL_ 546 FLR_Misalignment_FaultSts 0 "Aligned" 1 "Misaligned"  ;
VAL_ 546 FLR_ModulationSts 0 "On" 1 "Off"  ;
VAL_ 546 FLR_Radar_FaultSts 0 "No Fail" 1 "Fail" 0 "No Fail" 1 "Fail" 0 "No Fail" 1 "Fail" 0 "No Fail" 1 "Fail" 0 "No Fail" 1 "Fail"  ;
VAL_ 546 FLR_SDA_CalibrationSts 0 "successfully calibrated" 1 "calibration is processing" 2 "calibration is failed" 3 "cancelled by user" 255 "routine not started"  ;
VAL_ 546 FLR_SW_ReleaseType 0 "V(Version)" 1 "RC(Release Candidate)" 2 "LC (Local Release)"  ;
VAL_ 546 Fault_MAL_HOR_ABS_EVENT 0 "Not Fault" 1 "Fault"  ;
VAL_ 546 Fault_MAL_HOR_REL_EVENT 0 "Not Fault" 1 "Fault"  ;
VAL_ 546 Fault_MAL_VER_ABS_EVENT 0 "Not Fault" 1 "Fault"  ;
VAL_ 546 Fault_MAL_VER_REL_EVENT 0 "Not Fault" 1 "Fault"  ;
VAL_ 546 azOutOfProfileCause 0 "No Out" 1 "Out"  ;
VAL_ 546 azOutOfSpecCause 0 "No Out" 1 "Out"  ;
VAL_ 546 elOutOfProfileCause 0 "No Out" 1 "Out"  ;
VAL_ 546 elOutOfSpecCause 0 "No Out" 1 "Out"  ;
VAL_ 616 UMM_UsageModeSt 0 "Standby" 1 "Comfort" 2 "ToBeDRV(Reserved)" 3 "DRV" 7 "Invalid"  ;
VAL_ 616 VMM_OTAModeSt 0 "NonOTA Mode" 1 "OTA Mode" 2 "Invalid Value" 3 "reserved"  ;
VAL_ 769 FRR_Moudulation_State 0 "on" 1 "off"  ;
VAL_ 769 FRR_OperationMode 0 "ON" 1 "Sensor covered"  ;
VAL_ 769 FRR_SGUFail 0 "No fail" 1 "SGU failed"  ;
VAL_ 769 FRR_SensorType 0 "Unknown" 1 "Front Radar" 2 "Rear Radar" 3 "Front Left Radar (Corner)" 4 "Front Right Radar (Corner)" 5 "Rear Left Radar (Corner)" 6 "Rear Right Radar (Corner)" 7 "Reserve"  ;
VAL_ 769 FRR_Signal_Operatation_Channel 0 "no operation" 1 "SOC channel" 2 "MCU channel" 3 "IFC channel"  ;
VAL_ 769 FRR_Signal_Operation_State 0 "Initial State" 1 "Main State" 2 "Redundance State" 3 "Failed State"  ;
VAL_ 769 FRR_TimeSync_Operatation_Channel 0 "no operation" 1 "SOC channel" 2 "MCU channel" 3 "reserved"  ;
VAL_ 769 FRR_TimeSync_Operation_State 0 "Initial State" 1 "Main State" 2 "Redundance State" 3 "Failed State"  ;
VAL_ 770 SGU1_Object_DetStatus 0 "deleted" 1 "new" 2 "measured" 3 "predicted" 4 "deleted for merge" 5 "new from  merge"  ;
VAL_ 770 SGU1_Object_Motion_Pattern 0 "Unknown" 1 "Stationary" 2 "Stopped" 3 "Moving"  ;
VAL_ 770 SGU1_Object_Type 0 "Unknown" 1 "4 wheeler" 2 "2 wheeler" 3 "Pedestrian"  ;
VAL_ 771 SGU2_Object_DetStatus 0 "deleted" 1 "new" 2 "measured" 3 "predicted" 4 "deleted for merge" 5 "new from  merge"  ;
VAL_ 771 SGU2_Object_Motion_Pattern 0 "Unknown" 1 "Stationary" 2 "Stopped" 3 "Moving"  ;
VAL_ 771 SGU2_Object_Type 0 "Unknown" 1 "4 wheeler" 2 "2 wheeler" 3 "Pedestrian"  ;
VAL_ 772 SGU3_Object_DetStatus 0 "deleted" 1 "new" 2 "measured" 3 "predicted" 4 "deleted for merge" 5 "new from  merge"  ;
VAL_ 772 SGU3_Object_Motion_Pattern 0 "Unknown" 1 "Stationary" 2 "Stopped" 3 "Moving"  ;
VAL_ 772 SGU3_Object_Type 0 "Unknown" 1 "4 wheeler" 2 "2 wheeler" 3 "Pedestrian"  ;
VAL_ 773 SGU4_Object_DetStatus 0 "deleted" 1 "new" 2 "measured" 3 "predicted" 4 "deleted for merge" 5 "new from  merge"  ;
VAL_ 773 SGU4_Object_Motion_Pattern 0 "Unknown" 1 "Stationary" 2 "Stopped" 3 "Moving"  ;
VAL_ 773 SGU4_Object_Type 0 "Unknown" 1 "4 wheeler" 2 "2 wheeler" 3 "Pedestrian"  ;
VAL_ 774 SGU5_Object_DetStatus 0 "deleted" 1 "new" 2 "measured" 3 "predicted" 4 "deleted for merge" 5 "new from  merge"  ;
VAL_ 774 SGU5_Object_Motion_Pattern 0 "Unknown" 1 "Stationary" 2 "Stopped" 3 "Moving"  ;
VAL_ 774 SGU5_Object_Type 0 "Unknown" 1 "4 wheeler" 2 "2 wheeler" 3 "Pedestrian"  ;
VAL_ 775 SGU6_Object_DetStatus 0 "deleted" 1 "new" 2 "measured" 3 "predicted" 4 "deleted for merge" 5 "new from  merge"  ;
VAL_ 775 SGU6_Object_Motion_Pattern 0 "Unknown" 1 "Stationary" 2 "Stopped" 3 "Moving"  ;
VAL_ 775 SGU6_Object_Type 0 "Unknown" 1 "4 wheeler" 2 "2 wheeler" 3 "Pedestrian"  ;
